VERSION ""

NS_ :

BS_:

BU_: TestTool_HS BCP_HS ECM_HS TCM_HS CGM_HS BCM_HS EBCM_OBD_HS ACCM_HS EBCM_HS TCCM_HS SAS_HS ICCM_OBD_HS ICCM_HS EPS_HS EPB_HS HMIM_HS ONSTAR_HS

BO_ 1931 DTC_Triggered_78B: 7 SAS_HS
 SG_ DTCI_CodeSupported_78B : 40|1@0+ (1,0) [0|1] ""  CGM_HS,HMIM_HS,ONSTAR_HS
 SG_ DTCI_CurrentStatus_78B : 41|1@0+ (1,0) [0|1] ""  CGM_HS,HMIM_HS,ONSTAR_HS
 SG_ DTCI_DTCFailType_78B : 39|8@0+ (1,0) [0|255] ""  CGM_HS,HMIM_HS,ONSTAR_HS
 SG_ DTCI_DTCFaultType_78B : 55|8@0+ (1,0) [0|255] ""  CGM_HS,HMIM_HS,ONSTAR_HS
 SG_ DTCI_DTCNumber_78B : 23|16@0+ (1,0) [0|65535] ""  CGM_HS,HMIM_HS,ONSTAR_HS
 SG_ DTCI_DTCSource_78B : 15|8@0+ (1,0) [0|255] ""  CGM_HS,HMIM_HS,ONSTAR_HS
 SG_ DTCI_DTCTriggered_78B : 0|1@0+ (1,0) [0|1] ""  CGM_HS,HMIM_HS,ONSTAR_HS
 SG_ DTCI_HistStat_78B : 44|1@0+ (1,0) [0|1] ""  CGM_HS,HMIM_HS,ONSTAR_HS
 SG_ DTCI_TstFldCdClrdStat_78B : 43|1@0+ (1,0) [0|1] ""  CGM_HS,HMIM_HS,ONSTAR_HS
 SG_ DTCI_TstFldPwrUpSt_78B : 46|1@0+ (1,0) [0|1] ""  CGM_HS,HMIM_HS,ONSTAR_HS
 SG_ DTCI_TstNPsdCdClrdSt_78B : 42|1@0+ (1,0) [0|1] ""  CGM_HS,HMIM_HS,ONSTAR_HS
 SG_ DTCI_TstNPsdPwrUpSt_78B : 45|1@0+ (1,0) [0|1] ""  CGM_HS,HMIM_HS,ONSTAR_HS
 SG_ DTCIUnused1_78B : 7|1@0+ (1,0) [0|1] ""  CGM_HS,HMIM_HS,ONSTAR_HS
 SG_ DTCIUnused2_78B : 6|1@0+ (1,0) [0|1] ""  CGM_HS,HMIM_HS,ONSTAR_HS
 SG_ DTCIUnused3_78B : 5|1@0+ (1,0) [0|1] ""  CGM_HS,HMIM_HS,ONSTAR_HS
 SG_ DTCIUnused4_78B : 4|1@0+ (1,0) [0|1] ""  CGM_HS,HMIM_HS,ONSTAR_HS
 SG_ DTCIUnused5_78B : 3|1@0+ (1,0) [0|1] ""  CGM_HS,HMIM_HS,ONSTAR_HS
 SG_ DTCIUnused6_78B : 2|1@0+ (1,0) [0|1] ""  CGM_HS,HMIM_HS,ONSTAR_HS
 SG_ DTCIUnused7_78B : 1|1@0+ (1,0) [0|1] ""  CGM_HS,HMIM_HS,ONSTAR_HS
 SG_ DTCI_WrnIndRqdSt_78B : 47|1@0+ (1,0) [0|1] ""  CGM_HS,HMIM_HS,ONSTAR_HS

BO_ 1928 DTC_Triggered_788: 7 HMIM_HS
 SG_ DTCI_CodeSupported_788 : 40|1@0+ (1,0) [0|1] ""  CGM_HS,HMIM_HS,ONSTAR_HS
 SG_ DTCI_CurrentStatus_788 : 41|1@0+ (1,0) [0|1] ""  CGM_HS,HMIM_HS,ONSTAR_HS
 SG_ DTCI_DTCFailType_788 : 39|8@0+ (1,0) [0|255] ""  CGM_HS,HMIM_HS,ONSTAR_HS
 SG_ DTCI_DTCFaultType_788 : 55|8@0+ (1,0) [0|255] ""  CGM_HS,HMIM_HS,ONSTAR_HS
 SG_ DTCI_DTCNumber_788 : 23|16@0+ (1,0) [0|65535] ""  CGM_HS,HMIM_HS,ONSTAR_HS
 SG_ DTCI_DTCSource_788 : 15|8@0+ (1,0) [0|255] ""  CGM_HS,HMIM_HS,ONSTAR_HS
 SG_ DTCI_DTCTriggered_788 : 0|1@0+ (1,0) [0|1] ""  CGM_HS,HMIM_HS,ONSTAR_HS
 SG_ DTCI_HistStat_788 : 44|1@0+ (1,0) [0|1] ""  CGM_HS,HMIM_HS,ONSTAR_HS
 SG_ DTCI_TstFldCdClrdStat_788 : 42|1@0+ (1,0) [0|1] ""  CGM_HS,HMIM_HS,ONSTAR_HS
 SG_ DTCI_TstFldPwrUpSt_788 : 46|1@0+ (1,0) [0|1] ""  CGM_HS,HMIM_HS,ONSTAR_HS
 SG_ DTCI_TstNPsdCdClrdSt_788 : 43|1@0+ (1,0) [0|1] ""  CGM_HS,HMIM_HS,ONSTAR_HS
 SG_ DTCI_TstNPsdPwrUpSt_788 : 45|1@0+ (1,0) [0|1] ""  CGM_HS,HMIM_HS,ONSTAR_HS
 SG_ DTCIUnused1_788 : 7|1@0+ (1,0) [0|1] ""  CGM_HS,HMIM_HS,ONSTAR_HS
 SG_ DTCIUnused2_788 : 6|1@0+ (1,0) [0|1] ""  CGM_HS,HMIM_HS,ONSTAR_HS
 SG_ DTCIUnused3_788 : 5|1@0+ (1,0) [0|1] ""  CGM_HS,HMIM_HS,ONSTAR_HS
 SG_ DTCIUnused4_788 : 4|1@0+ (1,0) [0|1] ""  CGM_HS,HMIM_HS,ONSTAR_HS
 SG_ DTCIUnused5_788 : 3|1@0+ (1,0) [0|1] ""  CGM_HS,HMIM_HS,ONSTAR_HS
 SG_ DTCIUnused6_788 : 2|1@0+ (1,0) [0|1] ""  CGM_HS,HMIM_HS,ONSTAR_HS
 SG_ DTCIUnused7_788 : 1|1@0+ (1,0) [0|1] ""  CGM_HS,HMIM_HS,ONSTAR_HS
 SG_ DTCI_WrnIndRqdSt_788 : 47|1@0+ (1,0) [0|1] ""  CGM_HS,HMIM_HS,ONSTAR_HS

BO_ 1925 DTC_Triggered_785: 7 ICCM_HS
 SG_ DTCI_CodeSupported_785 : 40|1@0+ (1,0) [0|1] ""  CGM_HS,HMIM_HS,ONSTAR_HS
 SG_ DTCI_CurrentStatus_785 : 41|1@0+ (1,0) [0|1] ""  CGM_HS,HMIM_HS,ONSTAR_HS
 SG_ DTCI_DTCFailType_785 : 39|8@0+ (1,0) [0|255] ""  CGM_HS,HMIM_HS,ONSTAR_HS
 SG_ DTCI_DTCFaultType_785 : 55|8@0+ (1,0) [0|255] ""  CGM_HS,HMIM_HS,ONSTAR_HS
 SG_ DTCI_DTCNumber_785 : 23|16@0+ (1,0) [0|65535] ""  CGM_HS,HMIM_HS,ONSTAR_HS
 SG_ DTCI_DTCSource_785 : 15|8@0+ (1,0) [0|255] ""  CGM_HS,HMIM_HS,ONSTAR_HS
 SG_ DTCI_DTCTriggered_785 : 0|1@0+ (1,0) [0|1] ""  CGM_HS,HMIM_HS,ONSTAR_HS
 SG_ DTCI_HistStat_785 : 44|1@0+ (1,0) [0|1] ""  CGM_HS,HMIM_HS,ONSTAR_HS
 SG_ DTCI_TstFldCdClrdStat_785 : 43|1@0+ (1,0) [0|1] ""  CGM_HS,HMIM_HS,ONSTAR_HS
 SG_ DTCI_TstFldPwrUpSt_785 : 46|1@0+ (1,0) [0|1] ""  CGM_HS,HMIM_HS,ONSTAR_HS
 SG_ DTCI_TstNPsdCdClrdSt_785 : 42|1@0+ (1,0) [0|1] ""  CGM_HS,HMIM_HS,ONSTAR_HS
 SG_ DTCI_TstNPsdPwrUpSt_785 : 45|1@0+ (1,0) [0|1] ""  CGM_HS,HMIM_HS,ONSTAR_HS
 SG_ DTCIUnused1_785 : 7|1@0+ (1,0) [0|1] ""  CGM_HS,HMIM_HS,ONSTAR_HS
 SG_ DTCIUnused2_785 : 6|1@0+ (1,0) [0|1] ""  CGM_HS,HMIM_HS,ONSTAR_HS
 SG_ DTCIUnused3_785 : 5|1@0+ (1,0) [0|1] ""  CGM_HS,HMIM_HS,ONSTAR_HS
 SG_ DTCIUnused4_785 : 4|1@0+ (1,0) [0|1] ""  CGM_HS,HMIM_HS,ONSTAR_HS
 SG_ DTCIUnused5_785 : 3|1@0+ (1,0) [0|1] ""  CGM_HS,HMIM_HS,ONSTAR_HS
 SG_ DTCIUnused6_785 : 2|1@0+ (1,0) [0|1] ""  CGM_HS,HMIM_HS,ONSTAR_HS
 SG_ DTCIUnused7_785 : 1|1@0+ (1,0) [0|1] ""  CGM_HS,HMIM_HS,ONSTAR_HS
 SG_ DTCI_WrnIndRqdSt_785 : 47|1@0+ (1,0) [0|1] ""  CGM_HS,HMIM_HS,ONSTAR_HS

BO_ 1922 DTC_Triggered_782: 7 CGM_HS
 SG_ DTCI_WrnIndRqdSt_782 : 47|1@0+ (1,0) [0|1] ""  CGM_HS,HMIM_HS,ONSTAR_HS
 SG_ DTCIUnused7_782 : 1|1@0+ (1,0) [0|1] ""  CGM_HS,HMIM_HS,ONSTAR_HS
 SG_ DTCIUnused6_782 : 2|1@0+ (1,0) [0|1] ""  CGM_HS,HMIM_HS,ONSTAR_HS
 SG_ DTCIUnused5_782 : 3|1@0+ (1,0) [0|1] ""  CGM_HS,HMIM_HS,ONSTAR_HS
 SG_ DTCIUnused4_782 : 4|1@0+ (1,0) [0|1] ""  CGM_HS,HMIM_HS,ONSTAR_HS
 SG_ DTCIUnused3_782 : 5|1@0+ (1,0) [0|1] ""  CGM_HS,HMIM_HS,ONSTAR_HS
 SG_ DTCIUnused2_782 : 6|1@0+ (1,0) [0|1] ""  CGM_HS,HMIM_HS,ONSTAR_HS
 SG_ DTCIUnused1_782 : 7|1@0+ (1,0) [0|1] ""  CGM_HS,HMIM_HS,ONSTAR_HS
 SG_ DTCI_TstNPsdPwrUpSt_782 : 45|1@0+ (1,0) [0|1] ""  CGM_HS,HMIM_HS,ONSTAR_HS
 SG_ DTCI_TstNPsdCdClrdSt_782 : 42|1@0+ (1,0) [0|1] ""  CGM_HS,HMIM_HS,ONSTAR_HS
 SG_ DTCI_TstFldPwrUpSt_782 : 46|1@0+ (1,0) [0|1] ""  CGM_HS,HMIM_HS,ONSTAR_HS
 SG_ DTCI_TstFldCdClrdStat_782 : 43|1@0+ (1,0) [0|1] ""  CGM_HS,HMIM_HS,ONSTAR_HS
 SG_ DTCI_HistStat_782 : 44|1@0+ (1,0) [0|1] ""  CGM_HS,HMIM_HS,ONSTAR_HS
 SG_ DTCI_DTCTriggered_782 : 0|1@0+ (1,0) [0|1] ""  CGM_HS,HMIM_HS,ONSTAR_HS
 SG_ DTCI_DTCSource_782 : 15|8@0+ (1,0) [0|255] ""  CGM_HS,HMIM_HS,ONSTAR_HS
 SG_ DTCI_DTCNumber_782 : 23|16@0+ (1,0) [0|65535] ""  CGM_HS,HMIM_HS,ONSTAR_HS
 SG_ DTCI_DTCFaultType_782 : 55|8@0+ (1,0) [0|255] ""  CGM_HS,HMIM_HS,ONSTAR_HS
 SG_ DTCI_DTCFailType_782 : 39|8@0+ (1,0) [0|255] ""  CGM_HS,HMIM_HS,ONSTAR_HS
 SG_ DTCI_CurrentStatus_782 : 41|1@0+ (1,0) [0|1] ""  CGM_HS,HMIM_HS,ONSTAR_HS
 SG_ DTCI_CodeSupported_782 : 40|1@0+ (1,0) [0|1] ""  CGM_HS,HMIM_HS,ONSTAR_HS

BO_ 1904 DTC_Triggered_770: 7 ICCM_OBD_HS
 SG_ DTCI_WrnIndRqdSt_770 : 47|1@0+ (1,0) [0|1] ""  CGM_HS,HMIM_HS,ONSTAR_HS
 SG_ DTCIUnused7_770 : 7|1@0+ (1,0) [0|1] ""  CGM_HS,HMIM_HS,ONSTAR_HS
 SG_ DTCIUnused6_770 : 6|1@0+ (1,0) [0|1] ""  CGM_HS,HMIM_HS,ONSTAR_HS
 SG_ DTCIUnused5_770 : 5|1@0+ (1,0) [0|1] ""  CGM_HS,HMIM_HS,ONSTAR_HS
 SG_ DTCIUnused4_770 : 4|1@0+ (1,0) [0|1] ""  CGM_HS,HMIM_HS,ONSTAR_HS
 SG_ DTCIUnused3_770 : 3|1@0+ (1,0) [0|1] ""  CGM_HS,HMIM_HS,ONSTAR_HS
 SG_ DTCIUnused2_770 : 2|1@0+ (1,0) [0|1] ""  CGM_HS,HMIM_HS,ONSTAR_HS
 SG_ DTCIUnused1_770 : 1|1@0+ (1,0) [0|1] ""  CGM_HS,HMIM_HS,ONSTAR_HS
 SG_ DTCI_TstNPsdPwrUpSt_770 : 45|1@0+ (1,0) [0|1] ""  CGM_HS,HMIM_HS,ONSTAR_HS
 SG_ DTCI_TstNPsdCdClrdSt_770 : 42|1@0+ (1,0) [0|1] ""  CGM_HS,HMIM_HS,ONSTAR_HS
 SG_ DTCI_TstFldPwrUpSt_770 : 46|1@0+ (1,0) [0|1] ""  CGM_HS,HMIM_HS,ONSTAR_HS
 SG_ DTCI_TstFldCdClrdStat_770 : 43|1@0+ (1,0) [0|1] ""  CGM_HS,HMIM_HS,ONSTAR_HS
 SG_ DTCI_HistStat_770 : 44|1@0+ (1,0) [0|1] ""  CGM_HS,HMIM_HS,ONSTAR_HS
 SG_ DTCI_DTCTriggered_770 : 0|1@0+ (1,0) [0|1] ""  CGM_HS,HMIM_HS,ONSTAR_HS
 SG_ DTCI_DTCSource_770 : 15|8@0+ (1,0) [0|255] ""  CGM_HS,HMIM_HS,ONSTAR_HS
 SG_ DTCI_DTCNumber_770 : 23|16@0+ (1,0) [0|65535] ""  CGM_HS,HMIM_HS,ONSTAR_HS
 SG_ DTCI_DTCFaultType_770 : 55|8@0+ (1,0) [0|255] ""  CGM_HS,HMIM_HS,ONSTAR_HS
 SG_ DTCI_DTCFailType_770 : 39|8@0+ (1,0) [0|255] ""  CGM_HS,HMIM_HS,ONSTAR_HS
 SG_ DTCI_CurrentStatus_770 : 41|1@0+ (1,0) [0|1] ""  CGM_HS,HMIM_HS,ONSTAR_HS
 SG_ DTCI_CodeSupported_770 : 40|1@0+ (1,0) [0|1] ""  CGM_HS,HMIM_HS,ONSTAR_HS

BO_ 1921 DTC_Triggered_781: 7 CGM_HS
 SG_ DTCI_CurrentStatus_781 : 41|1@0+ (1,0) [0|1] ""  CGM_HS,HMIM_HS,ONSTAR_HS
 SG_ DTCI_WrnIndRqdSt_781 : 47|1@0+ (1,0) [0|1] ""  CGM_HS,HMIM_HS,ONSTAR_HS
 SG_ DTCIUnused7_781 : 1|1@0+ (1,0) [0|1] ""  CGM_HS,HMIM_HS,ONSTAR_HS
 SG_ DTCIUnused6_781 : 2|1@0+ (1,0) [0|1] ""  CGM_HS,HMIM_HS,ONSTAR_HS
 SG_ DTCIUnused5_781 : 3|1@0+ (1,0) [0|1] ""  CGM_HS,HMIM_HS,ONSTAR_HS
 SG_ DTCIUnused4_781 : 4|1@0+ (1,0) [0|1] ""  CGM_HS,HMIM_HS,ONSTAR_HS
 SG_ DTCIUnused3_781 : 5|1@0+ (1,0) [0|1] ""  CGM_HS,HMIM_HS,ONSTAR_HS
 SG_ DTCIUnused2_781 : 6|1@0+ (1,0) [0|1] ""  CGM_HS,HMIM_HS,ONSTAR_HS
 SG_ DTCIUnused1_781 : 7|1@0+ (1,0) [0|1] ""  CGM_HS,HMIM_HS,ONSTAR_HS
 SG_ DTCI_TstNPsdPwrUpSt_781 : 45|1@0+ (1,0) [0|1] ""  CGM_HS,HMIM_HS,ONSTAR_HS
 SG_ DTCI_TstNPsdCdClrdSt_781 : 42|1@0+ (1,0) [0|1] ""  CGM_HS,HMIM_HS,ONSTAR_HS
 SG_ DTCI_TstFldPwrUpSt_781 : 46|1@0+ (1,0) [0|1] ""  CGM_HS,HMIM_HS,ONSTAR_HS
 SG_ DTCI_TstFldCdClrdStat_781 : 43|1@0+ (1,0) [0|1] ""  CGM_HS,HMIM_HS,ONSTAR_HS
 SG_ DTCI_HistStat_781 : 44|1@0+ (1,0) [0|1] ""  CGM_HS,HMIM_HS,ONSTAR_HS
 SG_ DTCI_DTCTriggered_781 : 0|1@0+ (1,0) [0|1] ""  CGM_HS,HMIM_HS,ONSTAR_HS
 SG_ DTCI_DTCSource_781 : 15|8@0+ (1,0) [0|255] ""  CGM_HS,HMIM_HS,ONSTAR_HS
 SG_ DTCI_DTCNumber_781 : 23|16@0+ (1,0) [0|65535] ""  CGM_HS,HMIM_HS,ONSTAR_HS
 SG_ DTCI_DTCFaultType_781 : 55|8@0+ (1,0) [0|255] ""  CGM_HS,HMIM_HS,ONSTAR_HS
 SG_ DTCI_DTCFailType_781 : 39|8@0+ (1,0) [0|255] ""  CGM_HS,HMIM_HS,ONSTAR_HS
 SG_ DTCI_CodeSupported_781 : 40|1@0+ (1,0) [0|1] ""  CGM_HS,HMIM_HS,ONSTAR_HS

BO_ 1912 DTC_Triggered_778: 7 EPS_HS
 SG_ DTCI_DTCFaultType_778 : 55|8@0+ (1,0) [0|255] ""  CGM_HS,HMIM_HS,ONSTAR_HS
 SG_ DTCI_CodeSupported_778 : 40|1@0+ (1,0) [0|1] ""  CGM_HS,HMIM_HS,ONSTAR_HS
 SG_ DTCI_CurrentStatus_778 : 41|1@0+ (1,0) [0|1] ""  CGM_HS,HMIM_HS,ONSTAR_HS
 SG_ DTCI_TstNPsdCdClrdSt_778 : 42|1@0+ (1,0) [0|1] ""  CGM_HS,HMIM_HS,ONSTAR_HS
 SG_ DTCI_TstFldCdClrdStat_778 : 43|1@0+ (1,0) [0|1] ""  CGM_HS,HMIM_HS,ONSTAR_HS
 SG_ DTCI_HistStat_778 : 44|1@0+ (1,0) [0|1] ""  CGM_HS,HMIM_HS,ONSTAR_HS
 SG_ DTCI_TstNPsdPwrUpSt_778 : 45|1@0+ (1,0) [0|1] ""  CGM_HS,HMIM_HS,ONSTAR_HS
 SG_ DTCI_TstFldPwrUpSt_778 : 46|1@0+ (1,0) [0|1] ""  CGM_HS,HMIM_HS,ONSTAR_HS
 SG_ DTCI_WrnIndRqdSt_778 : 47|1@0+ (1,0) [0|1] ""  CGM_HS,HMIM_HS,ONSTAR_HS
 SG_ DTCI_DTCFailType_778 : 39|8@0+ (1,0) [0|255] ""  CGM_HS,HMIM_HS,ONSTAR_HS
 SG_ DTCI_DTCNumber_778 : 23|16@0+ (1,0) [0|65535] ""  CGM_HS,HMIM_HS,ONSTAR_HS
 SG_ DTCI_DTCSource_778 : 15|8@0+ (1,0) [0|255] ""  CGM_HS,HMIM_HS,ONSTAR_HS
 SG_ DTCI_DTCTriggered_778 : 0|1@0+ (1,0) [0|1] ""  CGM_HS,HMIM_HS,ONSTAR_HS
 SG_ DTCIUnused7_778 : 1|1@0+ (1,0) [0|1] ""  CGM_HS,HMIM_HS,ONSTAR_HS
 SG_ DTCIUnused6_778 : 2|1@0+ (1,0) [0|1] ""  CGM_HS,HMIM_HS,ONSTAR_HS
 SG_ DTCIUnused5_778 : 3|1@0+ (1,0) [0|1] ""  CGM_HS,HMIM_HS,ONSTAR_HS
 SG_ DTCIUnused4_778 : 4|1@0+ (1,0) [0|1] ""  CGM_HS,HMIM_HS,ONSTAR_HS
 SG_ DTCIUnused3_778 : 5|1@0+ (1,0) [0|1] ""  CGM_HS,HMIM_HS,ONSTAR_HS
 SG_ DTCIUnused2_778 : 6|1@0+ (1,0) [0|1] ""  CGM_HS,HMIM_HS,ONSTAR_HS
 SG_ DTCIUnused1_778 : 7|1@0+ (1,0) [0|1] ""  CGM_HS,HMIM_HS,ONSTAR_HS

BO_ 1610 USDT_Resp_From_SAS_HS: 8 SAS_HS
 SG_ DgnInf : 7|64@0+ (1,0) [0|1.84467440737096E+019] ""  CGM_HS,ONSTAR_HS,TestTool_HS

BO_ 1363 UUDT_Resp_From_AMP_HS: 8 CGM_HS
 SG_ DgnInf_HS553 : 7|64@0+ (1,0) [0|1.84467440737096E+019] ""  ONSTAR_HS,TestTool_HS

BO_ 1631 USDT_Resp_From_VLBS_CGM_HS: 8 CGM_HS
 SG_ DgnInf : 7|64@0+ (1,0) [0|1.84467440737096E+019] ""  ONSTAR_HS,TestTool_HS

BO_ 1375 UUDT_Resp_From_VLBS_CGM_HS: 8 CGM_HS
 SG_ DgnInf_HS55F : 7|64@0+ (1,0) [0|1.84467440737096E+019] ""  ONSTAR_HS,TestTool_HS

BO_ 1372 UUDT_Resp_From_ACCM_HS: 8 ACCM_HS
 SG_ DgnInf_HS55C : 7|64@0+ (1,0) [0|1.84467440737096E+019] ""  CGM_HS,ONSTAR_HS,TestTool_HS

BO_ 1362 UUDT_Resp_From_HMIM_HS: 8 HMIM_HS
 SG_ DgnInf_HS552 : 7|64@0+ (1,0) [0|1.84467440737096E+019] ""  ONSTAR_HS,TestTool_HS

BO_ 1628 USDT_Resp_From_ACCM_HS: 8 ACCM_HS
 SG_ DgnInf : 7|64@0+ (1,0) [0|1.84467440737096E+019] ""  CGM_HS,ONSTAR_HS,TestTool_HS

BO_ 1619 USDT_Resp_From_AMP_HS: 8 CGM_HS
 SG_ DgnInf : 7|64@0+ (1,0) [0|1.84467440737096E+019] ""  ONSTAR_HS,TestTool_HS

BO_ 1618 USDT_Resp_From_HMIM_HS: 8 HMIM_HS
 SG_ DgnInf : 7|64@0+ (1,0) [0|1.84467440737096E+019] ""  ONSTAR_HS,TestTool_HS

BO_ 1357 UUDT_Resp_From_ONS_HS: 8 ONSTAR_HS
 SG_ DgnInf_HS54D : 7|64@0+ (1,0) [0|1.84467440737096E+019] ""  TestTool_HS

BO_ 1613 USDT_Resp_From_ONS_HS: 8 ONSTAR_HS
 SG_ DgnInf : 7|64@0+ (1,0) [0|1.84467440737096E+019] ""  TestTool_HS

BO_ 1606 USDT_Resp_From_APPS_HS: 8 CGM_HS
 SG_ DgnInf : 7|64@0+ (1,0) [0|1.84467440737096E+019] ""  CGM_HS,ONSTAR_HS,TestTool_HS

BO_ 1356 UUDT_Resp_From_PFAF_HS: 8 CGM_HS
 SG_ DgnInf_HS54C : 7|64@0+ (1,0) [0|1.84467440737096E+019] ""  CGM_HS,ONSTAR_HS,TestTool_HS

BO_ 1350 UUDT_Resp_From_APPS_HS: 8 CGM_HS
 SG_ DgnInf_HS546 : 7|64@0+ (1,0) [0|1.84467440737096E+019] ""  CGM_HS,TestTool_HS,ONSTAR_HS

BO_ 2029 USDT_Resp_From_OBD_Device5: 8 EBCM_OBD_HS
 SG_ DgnInf : 7|64@0+ (1,0) [0|1.84467440737096E+019] ""  CGM_HS,TestTool_HS,ONSTAR_HS

BO_ 1517 UUDT_Resp_From_OBD_Device5: 8 EBCM_OBD_HS
 SG_ DgnInf : 7|64@0+ (1,0) [0|1.84467440737096E+019] ""  CGM_HS,TestTool_HS,ONSTAR_HS

BO_ 1346 UUDT_Resp_From_EHPS_EPS_HS: 8 EPS_HS
 SG_ DgnInf_HS542 : 7|64@0+ (1,0) [0|1.84467440737096E+019] ""  CGM_HS,TestTool_HS,ONSTAR_HS

BO_ 1602 USDT_Resp_From_EHPS_EPS_HS: 8 EPS_HS
 SG_ DgnInf : 7|64@0+ (1,0) [0|1.84467440737096E+019] ""  CGM_HS,TestTool_HS,ONSTAR_HS

BO_ 2027 USDT_Resp_From_ICCM_OBD_HS: 8 ICCM_HS
 SG_ DgnInf : 7|64@0+ (1,0) [0|1.84467440737096E+019] ""  CGM_HS,TestTool_HS,ONSTAR_HS

BO_ 1515 UUDT_Resp_From_ICCM_OBD_HS: 8 ICCM_HS
 SG_ DgnInf : 7|64@0+ (1,0) [0|1.84467440737096E+019] ""  CGM_HS,TestTool_HS,ONSTAR_HS

BO_ 1354 UUDT_Resp_From_SAS_HS: 8 SAS_HS
 SG_ DgnInf_HS54A : 7|64@0+ (1,0) [0|1.84467440737096E+019] ""  CGM_HS,TestTool_HS,ONSTAR_HS

BO_ 1612 USDT_Resp_From_PFAF_HS: 8 CGM_HS
 SG_ DgnInf : 7|64@0+ (1,0) [0|1.84467440737096E+019] ""  CGM_HS,ONSTAR_HS,TestTool_HS

BO_ 607 USDT_Req_to_VLBS_CGM_HS: 8 TestTool_HS
 SG_ DgnInf : 7|64@0+ (1,0) [0|1.84467440737096E+019] ""  CGM_HS

BO_ 606 USDT_Req_to_VCM_HS: 8 TestTool_HS
 SG_ DgnInf : 7|64@0+ (1,0) [0|1.84467440737096E+019] "" Vector__XXX

BO_ 605 USDT_Req_to_ARS_HS: 8 TestTool_HS
 SG_ DgnInf : 7|64@0+ (1,0) [0|1.84467440737096E+019] "" Vector__XXX

BO_ 604 USDT_Req_to_ACCM_HS: 8 TestTool_HS
 SG_ DgnInf : 7|64@0+ (1,0) [0|1.84467440737096E+019] ""  ACCM_HS

BO_ 602 USDT_Req_to_Free_5A_HS: 8 TestTool_HS
 SG_ DgnInf : 7|64@0+ (1,0) [0|1.84467440737096E+019] "" Vector__XXX

BO_ 600 USDT_Req_to_MCP_B_HS: 8 TestTool_HS
 SG_ DgnInf : 7|64@0+ (1,0) [0|1.84467440737096E+019] "" Vector__XXX

BO_ 595 USDT_Req_to_AMP_HS: 8 TestTool_HS
 SG_ DgnInf : 7|64@0+ (1,0) [0|1.84467440737096E+019] ""  CGM_HS

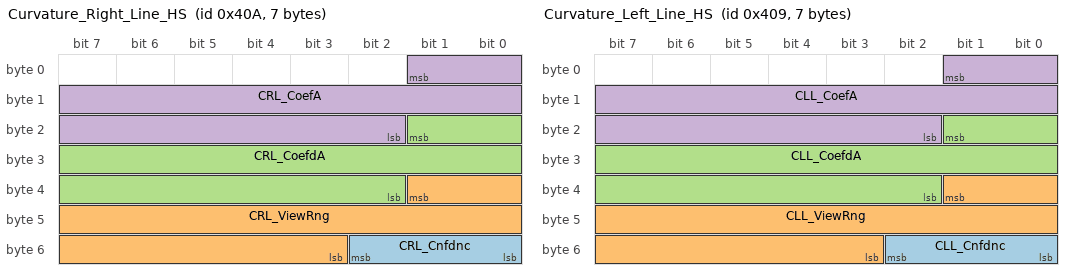
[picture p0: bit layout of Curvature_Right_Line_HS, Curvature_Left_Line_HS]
BO_ 1034 Curvature_Right_Line_HS: 7 CGM_HS
 SG_ CRL_Cnfdnc : 50|3@0+ (1,0) [0|7] ""  EBCM_OBD_HS,EBCM_HS
 SG_ CRL_ViewRng : 33|15@0+ (0.0039064,0) [0|128.0010088] "m"  EBCM_OBD_HS,EBCM_HS
 SG_ CRL_CoefdA : 17|16@0- (3.6622E-009,0) [-0.0001200029696|0.0001199993074] "1/m^2"  EBCM_OBD_HS,EBCM_HS
 SG_ CRL_CoefA : 1|16@0- (6.1036E-007,0) [-0.02000027648|0.01999966612] "1/m"  EBCM_OBD_HS,EBCM_HS

BO_ 1033 Curvature_Left_Line_HS: 7 CGM_HS
 SG_ CLL_Cnfdnc : 50|3@0+ (1,0) [0|7] ""  EBCM_OBD_HS,EBCM_HS
 SG_ CLL_ViewRng : 33|15@0+ (0.0039064,0) [0|128.0010088] "m"  EBCM_OBD_HS,EBCM_HS
 SG_ CLL_CoefdA : 17|16@0- (3.6622E-009,0) [-0.0001200029696|0.0001199993074] "1/m^2"  EBCM_OBD_HS,EBCM_HS
 SG_ CLL_CoefA : 1|16@0- (6.1036E-007,0) [-0.02000027648|0.01999966612] "1/m"  EBCM_OBD_HS,EBCM_HS

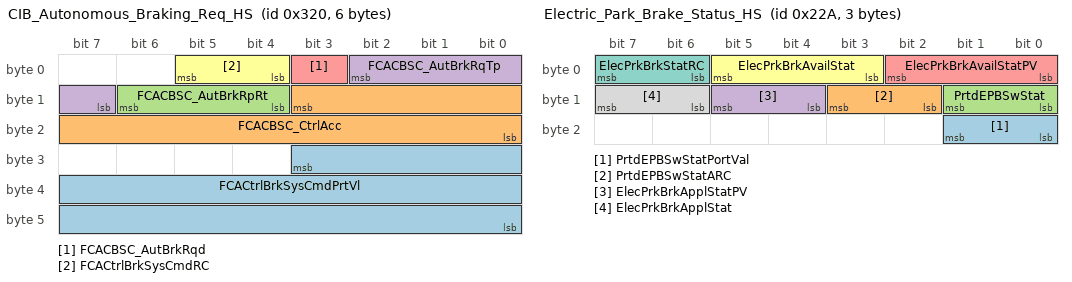
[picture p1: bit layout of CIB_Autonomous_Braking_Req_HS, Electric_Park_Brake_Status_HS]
BO_ 800 CIB_Autonomous_Braking_Req_HS: 6 CGM_HS
 SG_ FCACtrlBrkSysCmdPrtVl : 27|20@0+ (1,0) [0|1048575] ""  EBCM_OBD_HS,EBCM_HS
 SG_ FCACBSC_CtrlAcc : 11|12@0- (0.01,0) [-20.48|20.47] "m/s^2"  EBCM_OBD_HS,EBCM_HS
 SG_ FCACBSC_AutBrkRpRt : 14|3@0+ (1,0) [0|7] ""  EBCM_OBD_HS,EBCM_HS
 SG_ FCACBSC_AutBrkRqTp : 2|4@0+ (1,0) [0|15] ""  EBCM_OBD_HS,EBCM_HS
 SG_ FCACBSC_AutBrkRqd : 3|1@0+ (1,0) [0|1] ""  EBCM_OBD_HS,EBCM_HS
 SG_ FCACtrlBrkSysCmdRC : 5|2@0+ (1,0) [0|3] ""  EBCM_OBD_HS,EBCM_HS

BO_ 554 Electric_Park_Brake_Status_HS: 3 EPB_HS
 SG_ PrtdEPBSwStatPortVal : 17|2@0+ (1,0) [0|3] "Counts"  EBCM_OBD_HS,EBCM_HS
 SG_ PrtdEPBSwStatARC : 11|2@0+ (1,0) [0|3] "Counts"  EBCM_OBD_HS,EBCM_HS
 SG_ PrtdEPBSwStat : 9|2@0+ (1,0) [0|3] ""  EBCM_OBD_HS,EBCM_HS
 SG_ ElecPrkBrkApplStatPV : 13|2@0+ (1,0) [0|3] ""  EBCM_OBD_HS,EBCM_HS
 SG_ ElecPrkBrkAvailStatPV : 2|3@0+ (1,0) [0|7] ""  EBCM_OBD_HS,EBCM_HS
 SG_ ElecPrkBrkAvailStat : 5|3@0+ (1,0) [0|7] ""  EBCM_OBD_HS,EBCM_HS
 SG_ ElecPrkBrkStatRC : 7|2@0+ (1,0) [0|3] ""  EBCM_OBD_HS,EBCM_HS
 SG_ ElecPrkBrkApplStat : 15|2@0+ (1,0) [0|3] ""  EBCM_OBD_HS,EBCM_HS

BO_ 464 PPEI_Front_Axle_Status: 4 TCCM_HS
 SG_ FrtAxlOpeMod : 31|3@0+ (1,0) [0|7] ""  EBCM_OBD_HS,EBCM_HS

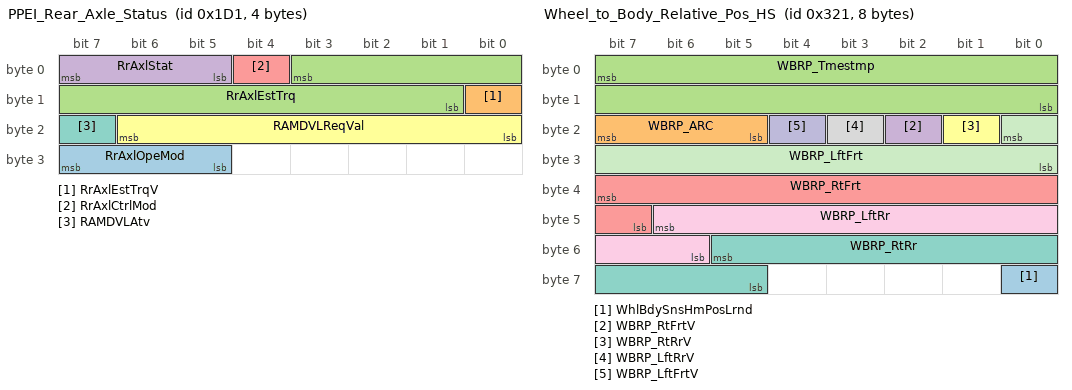
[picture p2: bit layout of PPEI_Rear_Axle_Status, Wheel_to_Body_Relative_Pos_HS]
BO_ 465 PPEI_Rear_Axle_Status: 4 TCCM_HS
 SG_ RrAxlOpeMod : 31|3@0+ (1,0) [0|7] ""  EBCM_OBD_HS,EBCM_HS
 SG_ RrAxlEstTrqV : 8|1@0+ (1,0) [0|1] ""  EBCM_OBD_HS,EBCM_HS
 SG_ RrAxlEstTrq : 3|11@0- (5,0) [-5120|5115] "Nm"  EBCM_OBD_HS,EBCM_HS
 SG_ RrAxlStat : 7|3@0+ (1,0) [0|7] ""  EBCM_OBD_HS,EBCM_HS
 SG_ RrAxlCtrlMod : 4|1@0+ (1,0) [0|1] ""  EBCM_OBD_HS,EBCM_HS
 SG_ RAMDVLReqVal : 22|7@0+ (2,0) [0|254] "rpm"  EBCM_OBD_HS,EBCM_HS
 SG_ RAMDVLAtv : 23|1@0+ (1,0) [0|1] ""  EBCM_OBD_HS,EBCM_HS

BO_ 801 Wheel_to_Body_Relative_Pos_HS: 8 ICCM_HS
 SG_ WhlBdySnsHmPosLrnd : 56|1@0+ (1,0) [0|1] ""  CGM_HS,ICCM_OBD_HS,EBCM_OBD_HS,ICCM_HS,EBCM_HS
 SG_ WBRP_ARC : 23|3@0+ (1,0) [0|7] "counts"  CGM_HS,ICCM_OBD_HS,EBCM_OBD_HS,ICCM_HS,EBCM_HS
 SG_ WBRP_Tmestmp : 7|16@0+ (1,0) [0|65535] "micro sec"  CGM_HS,ICCM_OBD_HS,EBCM_OBD_HS,ICCM_HS,EBCM_HS
 SG_ WBRP_RtFrtV : 18|1@0+ (1,0) [0|1] ""  CGM_HS,ICCM_OBD_HS,EBCM_OBD_HS,ICCM_HS,EBCM_HS
 SG_ WBRP_RtFrt : 39|9@0- (1,0) [-256|255] "mm"  CGM_HS,ICCM_OBD_HS,EBCM_OBD_HS,ICCM_HS,EBCM_HS
 SG_ WBRP_RtRrV : 17|1@0+ (1,0) [0|1] ""  CGM_HS,ICCM_OBD_HS,EBCM_OBD_HS,ICCM_HS,EBCM_HS
 SG_ WBRP_RtRr : 53|9@0- (1,0) [-256|255] "mm"  CGM_HS,ICCM_OBD_HS,EBCM_OBD_HS,ICCM_HS,EBCM_HS
 SG_ WBRP_LftRrV : 19|1@0+ (1,0) [0|1] ""  CGM_HS,ICCM_OBD_HS,EBCM_OBD_HS,ICCM_HS,EBCM_HS
 SG_ WBRP_LftRr : 46|9@0- (1,0) [-256|255] "mm"  CGM_HS,ICCM_OBD_HS,EBCM_OBD_HS,ICCM_HS,EBCM_HS
 SG_ WBRP_LftFrtV : 20|1@0+ (1,0) [0|1] ""  CGM_HS,ICCM_OBD_HS,EBCM_OBD_HS,ICCM_HS,EBCM_HS
 SG_ WBRP_LftFrt : 16|9@0- (1,0) [-256|255] "mm"  CGM_HS,ICCM_OBD_HS,EBCM_OBD_HS,ICCM_HS,EBCM_HS

BO_ 579 USDT_Req_to_EBCM_HPCC_HS: 8 TestTool_HS
 SG_ DgnInf : 7|64@0+ (1,0) [0|1.84467440737096E+019] ""  EBCM_HS

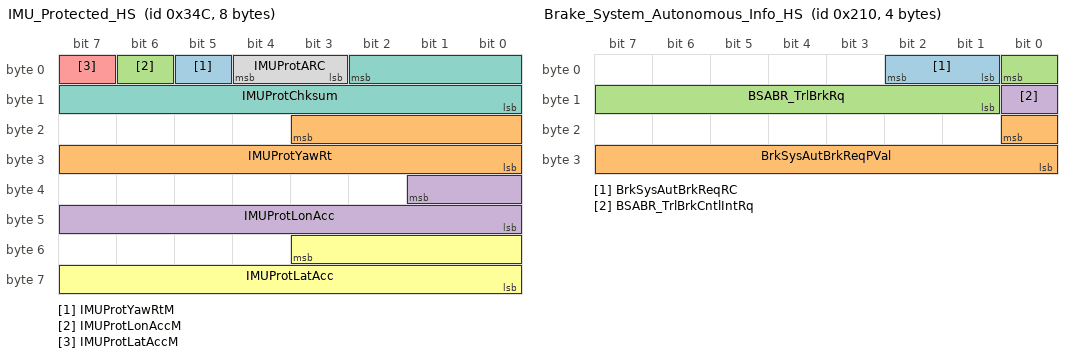
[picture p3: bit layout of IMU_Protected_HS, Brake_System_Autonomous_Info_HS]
BO_ 844 IMU_Protected_HS: 8 EBCM_HS
 SG_ IMUProtYawRtM : 5|1@0+ (1,0) [0|1] ""  CGM_HS,EPS_HS
 SG_ IMUProtYawRt : 19|12@0- (0.0625,0) [-128|127.9375] "deg/sec"  CGM_HS,EPS_HS
 SG_ IMUProtLonAccM : 6|1@0+ (1,0) [0|1] ""  CGM_HS,EPS_HS
 SG_ IMUProtLonAcc : 33|10@0- (0.03,0) [-15.36|15.33] "m/s^2"  CGM_HS,EPS_HS
 SG_ IMUProtLatAccM : 7|1@0+ (1,0) [0|1] ""  CGM_HS,EPS_HS
 SG_ IMUProtLatAcc : 51|12@0- (0.015625,0) [-32|31.984375] "m/s^2"  CGM_HS,EPS_HS
 SG_ IMUProtChksum : 2|11@0+ (1,0) [0|2047] ""  CGM_HS,EPS_HS
 SG_ IMUProtARC : 4|2@0+ (1,0) [0|3] ""  CGM_HS,EPS_HS

BO_ 528 Brake_System_Autonomous_Info_HS: 4 EBCM_HS
 SG_ BrkSysAutBrkReqRC : 2|2@0+ (1,0) [0|3] ""  ICCM_OBD_HS,ICCM_HS
 SG_ BrkSysAutBrkReqPVal : 16|9@0+ (1,0) [0|511] ""  ICCM_OBD_HS,ICCM_HS
 SG_ BSABR_TrlBrkRq : 0|8@0+ (0.392157,0) [0|100.000035] "%"  ICCM_OBD_HS,ICCM_HS
 SG_ BSABR_TrlBrkCntlIntRq : 8|1@0+ (1,0) [0|1] ""  ICCM_OBD_HS,ICCM_HS

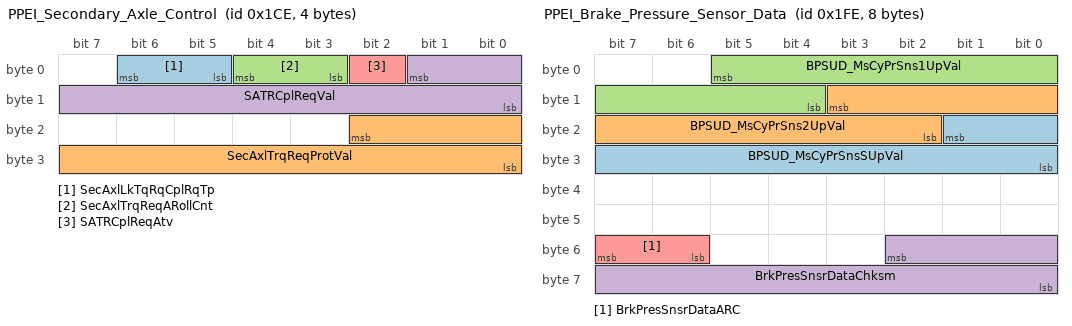
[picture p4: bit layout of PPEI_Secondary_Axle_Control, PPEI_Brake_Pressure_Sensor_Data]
BO_ 462 PPEI_Secondary_Axle_Control: 4 EBCM_HS
 SG_ SecAxlLkTqRqCplRqTp : 6|2@0+ (1,0) [0|3] ""  TCCM_HS
 SG_ SecAxlTrqReqProtVal : 18|11@0+ (1,0) [0|2047] "Counts"  TCCM_HS
 SG_ SecAxlTrqReqARollCnt : 4|2@0+ (1,0) [0|3] "Counts"  TCCM_HS
 SG_ SATRCplReqVal : 1|10@0+ (10,0) [0|10230] "Nm"  TCCM_HS
 SG_ SATRCplReqAtv : 2|1@0+ (1,0) [0|1] ""  TCCM_HS

BO_ 510 PPEI_Brake_Pressure_Sensor_Data: 8 EBCM_HS
 SG_ BPSUD_MsCyPrSnsSUpVal : 17|10@0+ (1,0) [0|1023] "" Vector__XXX
 SG_ BPSUD_MsCyPrSns2UpVal : 11|10@0+ (1,0) [0|1023] "" Vector__XXX
 SG_ BPSUD_MsCyPrSns1UpVal : 5|10@0+ (1,0) [0|1023] "" Vector__XXX
 SG_ BrkPresSnsrDataChksm : 50|11@0+ (1,0) [0|2047] "" Vector__XXX
 SG_ BrkPresSnsrDataARC : 55|2@0+ (1,0) [0|3] "" Vector__XXX

BO_ 1920 DTC_Triggered_780: 7 EBCM_HS
 SG_ DTCI_CurrentStatus_780 : 41|1@0+ (1,0) [0|1] ""  CGM_HS,HMIM_HS,ONSTAR_HS
 SG_ DTCI_WrnIndRqdSt_780 : 47|1@0+ (1,0) [0|1] ""  CGM_HS,HMIM_HS,ONSTAR_HS
 SG_ DTCIUnused7_780 : 1|1@0+ (1,0) [0|1] ""  CGM_HS,HMIM_HS,ONSTAR_HS
 SG_ DTCIUnused6_780 : 2|1@0+ (1,0) [0|1] ""  CGM_HS,HMIM_HS,ONSTAR_HS
 SG_ DTCIUnused5_780 : 3|1@0+ (1,0) [0|1] ""  CGM_HS,HMIM_HS,ONSTAR_HS
 SG_ DTCIUnused4_780 : 4|1@0+ (1,0) [0|1] ""  CGM_HS,HMIM_HS,ONSTAR_HS
 SG_ DTCIUnused3_780 : 5|1@0+ (1,0) [0|1] ""  CGM_HS,HMIM_HS,ONSTAR_HS
 SG_ DTCIUnused2_780 : 6|1@0+ (1,0) [0|1] ""  CGM_HS,HMIM_HS,ONSTAR_HS
 SG_ DTCIUnused1_780 : 7|1@0+ (1,0) [0|1] ""  CGM_HS,HMIM_HS,ONSTAR_HS
 SG_ DTCI_TstNPsdPwrUpSt_780 : 45|1@0+ (1,0) [0|1] ""  CGM_HS,HMIM_HS,ONSTAR_HS
 SG_ DTCI_TstNPsdCdClrdSt_780 : 42|1@0+ (1,0) [0|1] ""  CGM_HS,HMIM_HS,ONSTAR_HS
 SG_ DTCI_TstFldPwrUpSt_780 : 46|1@0+ (1,0) [0|1] ""  CGM_HS,HMIM_HS,ONSTAR_HS
 SG_ DTCI_TstFldCdClrdStat_780 : 43|1@0+ (1,0) [0|1] ""  CGM_HS,HMIM_HS,ONSTAR_HS
 SG_ DTCI_HistStat_780 : 44|1@0+ (1,0) [0|1] ""  CGM_HS,HMIM_HS,ONSTAR_HS
 SG_ DTCI_DTCTriggered_780 : 0|1@0+ (1,0) [0|1] ""  CGM_HS,HMIM_HS,ONSTAR_HS
 SG_ DTCI_DTCSource_780 : 15|8@0+ (1,0) [0|255] ""  CGM_HS,HMIM_HS,ONSTAR_HS
 SG_ DTCI_DTCNumber_780 : 23|16@0+ (1,0) [0|65535] ""  CGM_HS,HMIM_HS,ONSTAR_HS
 SG_ DTCI_DTCFaultType_780 : 55|8@0+ (1,0) [0|255] ""  CGM_HS,HMIM_HS,ONSTAR_HS
 SG_ DTCI_DTCFailType_780 : 39|8@0+ (1,0) [0|255] ""  CGM_HS,HMIM_HS,ONSTAR_HS
 SG_ DTCI_CodeSupported_780 : 40|1@0+ (1,0) [0|1] ""  CGM_HS,HMIM_HS,ONSTAR_HS

BO_ 1907 DTC_Triggered_773: 7 EBCM_HS
 SG_ DTCI_DTCFaultType_773 : 55|8@0+ (1,0) [0|255] ""  CGM_HS,HMIM_HS,ONSTAR_HS
 SG_ DTCI_CodeSupported_773 : 40|1@0+ (1,0) [0|1] ""  CGM_HS,HMIM_HS,ONSTAR_HS
 SG_ DTCI_CurrentStatus_773 : 41|1@0+ (1,0) [0|1] ""  CGM_HS,HMIM_HS,ONSTAR_HS
 SG_ DTCI_TstNPsdCdClrdSt_773 : 42|1@0+ (1,0) [0|1] ""  CGM_HS,HMIM_HS,ONSTAR_HS
 SG_ DTCI_TstFldCdClrdStat_773 : 43|1@0+ (1,0) [0|1] ""  CGM_HS,HMIM_HS,ONSTAR_HS
 SG_ DTCI_HistStat_773 : 44|1@0+ (1,0) [0|1] ""  CGM_HS,HMIM_HS,ONSTAR_HS
 SG_ DTCI_TstNPsdPwrUpSt_773 : 45|1@0+ (1,0) [0|1] ""  CGM_HS,HMIM_HS,ONSTAR_HS
 SG_ DTCI_TstFldPwrUpSt_773 : 46|1@0+ (1,0) [0|1] ""  CGM_HS,HMIM_HS,ONSTAR_HS
 SG_ DTCI_WrnIndRqdSt_773 : 47|1@0+ (1,0) [0|1] ""  CGM_HS,HMIM_HS,ONSTAR_HS
 SG_ DTCI_DTCFailType_773 : 39|8@0+ (1,0) [0|255] ""  CGM_HS,HMIM_HS,ONSTAR_HS
 SG_ DTCI_DTCNumber_773 : 23|16@0+ (1,0) [0|65535] ""  CGM_HS,HMIM_HS,ONSTAR_HS
 SG_ DTCI_DTCSource_773 : 15|8@0+ (1,0) [0|255] ""  CGM_HS,HMIM_HS,ONSTAR_HS
 SG_ DTCI_DTCTriggered_773 : 0|1@0+ (1,0) [0|1] ""  CGM_HS,HMIM_HS,ONSTAR_HS
 SG_ DTCIUnused7_773 : 1|1@0+ (1,0) [0|1] ""  CGM_HS,HMIM_HS,ONSTAR_HS
 SG_ DTCIUnused6_773 : 2|1@0+ (1,0) [0|1] ""  CGM_HS,HMIM_HS,ONSTAR_HS
 SG_ DTCIUnused5_773 : 3|1@0+ (1,0) [0|1] ""  CGM_HS,HMIM_HS,ONSTAR_HS
 SG_ DTCIUnused4_773 : 4|1@0+ (1,0) [0|1] ""  CGM_HS,HMIM_HS,ONSTAR_HS
 SG_ DTCIUnused3_773 : 5|1@0+ (1,0) [0|1] ""  CGM_HS,HMIM_HS,ONSTAR_HS
 SG_ DTCIUnused2_773 : 6|1@0+ (1,0) [0|1] ""  CGM_HS,HMIM_HS,ONSTAR_HS
 SG_ DTCIUnused1_773 : 7|1@0+ (1,0) [0|1] ""  CGM_HS,HMIM_HS,ONSTAR_HS

BO_ 1603 USDT_Resp_From_EBCM_HPCC_HS: 8 EBCM_HS
 SG_ DgnInf : 7|64@0+ (1,0) [0|1.84467440737096E+019] ""  CGM_HS,TestTool_HS,ONSTAR_HS

BO_ 1347 UUDT_Resp_From_EBCM_HPCC_HS: 8 EBCM_HS
 SG_ DgnInf_HS543 : 7|64@0+ (1,0) [0|1.84467440737096E+019] ""  CGM_HS,TestTool_HS,ONSTAR_HS

BO_ 603 USDT_Req_to_ACC_HS: 8 TestTool_HS
 SG_ DgnInf : 7|64@0+ (1,0) [0|1.84467440737096E+019] ""  CGM_HS

BO_ 1371 UUDT_Resp_From_ACC_HS: 8 CGM_HS
 SG_ DgnInf_HS55B : 7|64@0+ (1,0) [0|1.84467440737096E+019] ""  CGM_HS,ONSTAR_HS,TestTool_HS

BO_ 1627 USDT_Resp_From_ACC_HS: 8 CGM_HS
 SG_ DgnInf : 7|64@0+ (1,0) [0|1.84467440737096E+019] ""  CGM_HS,ONSTAR_HS,TestTool_HS

BO_ 1915 DTC_Triggered_77B: 7 CGM_HS
 SG_ DTCI_DTCFaultType_77B : 55|8@0+ (1,0) [0|255] ""  CGM_HS,HMIM_HS,ONSTAR_HS
 SG_ DTCI_CodeSupported_77B : 40|1@0+ (1,0) [0|1] ""  CGM_HS,HMIM_HS,ONSTAR_HS
 SG_ DTCI_CurrentStatus_77B : 41|1@0+ (1,0) [0|1] ""  CGM_HS,HMIM_HS,ONSTAR_HS
 SG_ DTCI_TstNPsdCdClrdSt_77B : 42|1@0+ (1,0) [0|1] ""  CGM_HS,HMIM_HS,ONSTAR_HS
 SG_ DTCI_TstFldCdClrdStat_77B : 43|1@0+ (1,0) [0|1] ""  CGM_HS,HMIM_HS,ONSTAR_HS
 SG_ DTCI_HistStat_77B : 44|1@0+ (1,0) [0|1] ""  CGM_HS,HMIM_HS,ONSTAR_HS
 SG_ DTCI_TstNPsdPwrUpSt_77B : 45|1@0+ (1,0) [0|1] ""  CGM_HS,HMIM_HS,ONSTAR_HS
 SG_ DTCI_TstFldPwrUpSt_77B : 46|1@0+ (1,0) [0|1] ""  CGM_HS,HMIM_HS,ONSTAR_HS
 SG_ DTCI_WrnIndRqdSt_77B : 47|1@0+ (1,0) [0|1] ""  CGM_HS,HMIM_HS,ONSTAR_HS
 SG_ DTCI_DTCFailType_77B : 39|8@0+ (1,0) [0|255] ""  CGM_HS,HMIM_HS,ONSTAR_HS
 SG_ DTCI_DTCNumber_77B : 23|16@0+ (1,0) [0|65535] ""  CGM_HS,HMIM_HS,ONSTAR_HS
 SG_ DTCI_DTCSource_77B : 15|8@0+ (1,0) [0|255] ""  CGM_HS,HMIM_HS,ONSTAR_HS
 SG_ DTCI_DTCTriggered_77B : 0|1@0+ (1,0) [0|1] ""  CGM_HS,HMIM_HS,ONSTAR_HS
 SG_ DTCIUnused7_77B : 1|1@0+ (1,0) [0|1] ""  CGM_HS,HMIM_HS,ONSTAR_HS
 SG_ DTCIUnused6_77B : 2|1@0+ (1,0) [0|1] ""  CGM_HS,HMIM_HS,ONSTAR_HS
 SG_ DTCIUnused5_77B : 3|1@0+ (1,0) [0|1] ""  CGM_HS,HMIM_HS,ONSTAR_HS
 SG_ DTCIUnused4_77B : 4|1@0+ (1,0) [0|1] ""  CGM_HS,HMIM_HS,ONSTAR_HS
 SG_ DTCIUnused3_77B : 5|1@0+ (1,0) [0|1] ""  CGM_HS,HMIM_HS,ONSTAR_HS
 SG_ DTCIUnused2_77B : 6|1@0+ (1,0) [0|1] ""  CGM_HS,HMIM_HS,ONSTAR_HS
 SG_ DTCIUnused1_77B : 7|1@0+ (1,0) [0|1] ""  CGM_HS,HMIM_HS,ONSTAR_HS

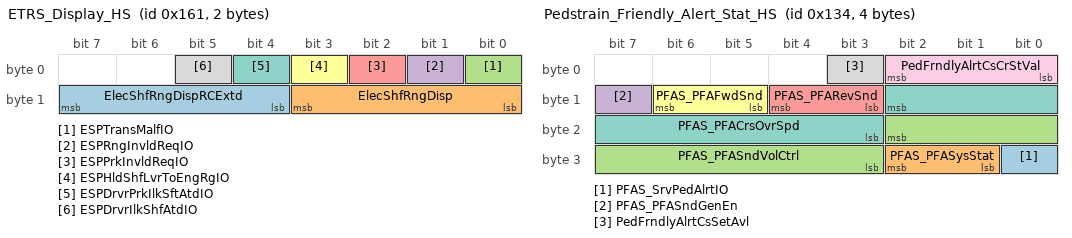
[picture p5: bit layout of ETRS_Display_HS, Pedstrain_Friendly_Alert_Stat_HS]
BO_ 353 ETRS_Display_HS: 2 ICCM_HS
 SG_ ElecShfRngDispRCExtd : 15|4@0+ (1,0) [0|15] ""  BCM_HS
 SG_ ElecShfRngDisp : 11|4@0+ (1,0) [0|15] ""  BCM_HS
 SG_ ESPTransMalfIO : 0|1@0+ (1,0) [0|1] ""  BCM_HS
 SG_ ESPRngInvldReqIO : 1|1@0+ (1,0) [0|1] ""  BCM_HS
 SG_ ESPPrkInvldReqIO : 2|1@0+ (1,0) [0|1] ""  BCM_HS
 SG_ ESPHldShfLvrToEngRgIO : 3|1@0+ (1,0) [0|1] ""  BCM_HS
 SG_ ESPDrvrPrkIlkSftAtdIO : 4|1@0+ (1,0) [0|1] ""  BCM_HS
 SG_ ESPDrvrIlkShfAtdIO : 5|1@0+ (1,0) [0|1] ""  BCM_HS

BO_ 308 Pedstrain_Friendly_Alert_Stat_HS: 4 CGM_HS
 SG_ PFAS_SrvPedAlrtIO : 24|1@0+ (1,0) [0|1] ""  BCM_HS
 SG_ PFAS_PFASysStat : 26|2@0+ (1,0) [0|3] ""  BCM_HS
 SG_ PFAS_PFASndVolCtrl : 18|8@0+ (0.392157,0) [0|100.000035] "%"  BCM_HS
 SG_ PFAS_PFASndGenEn : 15|1@0+ (1,0) [0|1] ""  BCM_HS
 SG_ PFAS_PFARevSnd : 12|2@0+ (1,0) [0|3] ""  BCM_HS
 SG_ PFAS_PFAFwdSnd : 14|2@0+ (1,0) [0|3] ""  BCM_HS
 SG_ PFAS_PFACrsOvrSpd : 10|8@0+ (1,0) [0|255] "km/h"  BCM_HS
 SG_ PedFrndlyAlrtCsSetAvl : 3|1@0+ (1,0) [0|1] ""  BCM_HS
 SG_ PedFrndlyAlrtCsCrStVal : 2|3@0+ (1,0) [0|7] ""  BCM_HS

BO_ 563 Performance_Mode_Cust_Setings_HS: 5 EBCM_HS
 SG_ SPMCA_SusPrfMd6Avl : 32|1@0+ (1,0) [0|1] ""  BCM_HS
 SG_ SPMCA_SusPrfMd5Avl : 33|1@0+ (1,0) [0|1] ""  BCM_HS
 SG_ SPMCA_SusPrfMd4Avl : 34|1@0+ (1,0) [0|1] ""  BCM_HS
 SG_ SPMCA_SusPrfMd3Avl : 35|1@0+ (1,0) [0|1] ""  BCM_HS
 SG_ SPMCA_SusPrfMd2Avl : 36|1@0+ (1,0) [0|1] ""  BCM_HS
 SG_ SPMCA_SusPrfMd1Avl : 37|1@0+ (1,0) [0|1] ""  BCM_HS
 SG_ SPMCA_StrPrfMd6Avl : 24|1@0+ (1,0) [0|1] ""  BCM_HS
 SG_ SPMCA_StrPrfMd5Avl : 25|1@0+ (1,0) [0|1] ""  BCM_HS
 SG_ SPMCA_StrPrfMd4Avl : 26|1@0+ (1,0) [0|1] ""  BCM_HS
 SG_ SPMCA_StrPrfMd3Avl : 27|1@0+ (1,0) [0|1] ""  BCM_HS
 SG_ SPMCA_StrPrfMd2Avl : 28|1@0+ (1,0) [0|1] ""  BCM_HS
 SG_ SPMCA_StrPrfMd1Avl : 29|1@0+ (1,0) [0|1] ""  BCM_HS
 SG_ SPMCA_SndPrfMd6Avl : 16|1@0+ (1,0) [0|1] ""  BCM_HS
 SG_ SPMCA_SndPrfMd5Avl : 17|1@0+ (1,0) [0|1] ""  BCM_HS
 SG_ SPMCA_SndPrfMd4Avl : 18|1@0+ (1,0) [0|1] ""  BCM_HS
 SG_ SPMCA_SndPrfMd3Avl : 19|1@0+ (1,0) [0|1] ""  BCM_HS
 SG_ SPMCA_SndPrfMd2Avl : 20|1@0+ (1,0) [0|1] ""  BCM_HS
 SG_ SPMCA_SndPrfMd1Avl : 21|1@0+ (1,0) [0|1] ""  BCM_HS
 SG_ DPMCA_DispPrfMd6Avl : 8|1@0+ (1,0) [0|1] ""  BCM_HS
 SG_ DPMCA_DispPrfMd5Avl : 9|1@0+ (1,0) [0|1] ""  BCM_HS
 SG_ DPMCA_DispPrfMd4Avl : 10|1@0+ (1,0) [0|1] ""  BCM_HS
 SG_ DPMCA_DispPrfMd3Avl : 11|1@0+ (1,0) [0|1] ""  BCM_HS
 SG_ DPMCA_DispPrfMd2Avl : 12|1@0+ (1,0) [0|1] ""  BCM_HS
 SG_ DPMCA_DispPrfMd1Avl : 13|1@0+ (1,0) [0|1] ""  BCM_HS
 SG_ DPMCA_DrvlPrfMd6Avl : 0|1@0+ (1,0) [0|1] ""  BCM_HS
 SG_ DPMCA_DrvlPrfMd5Avl : 1|1@0+ (1,0) [0|1] ""  BCM_HS
 SG_ DPMCA_DrvlPrfMd4Avl : 2|1@0+ (1,0) [0|1] ""  BCM_HS
 SG_ DPMCA_DrvlPrfMd3Avl : 3|1@0+ (1,0) [0|1] ""  BCM_HS
 SG_ DPMCA_DrvlPrfMd2Avl : 4|1@0+ (1,0) [0|1] ""  BCM_HS
 SG_ DPMCA_DrvlPrfMd1Avl : 5|1@0+ (1,0) [0|1] ""  BCM_HS

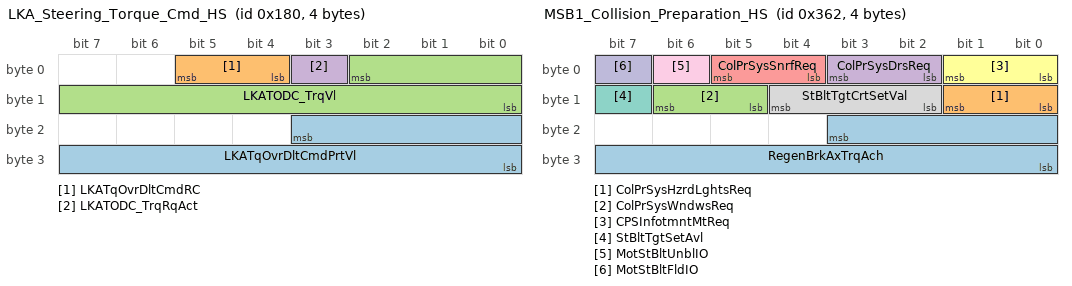
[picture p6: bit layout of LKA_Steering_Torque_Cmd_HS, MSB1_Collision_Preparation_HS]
BO_ 384 LKA_Steering_Torque_Cmd_HS: 4 CGM_HS
 SG_ LKATqOvrDltCmdPrtVl : 19|12@0+ (1,0) [0|4095] ""  EPS_HS
 SG_ LKATqOvrDltCmdRC : 5|2@0+ (1,0) [0|3] ""  EPS_HS
 SG_ LKATODC_TrqVl : 2|11@0- (0.01,0) [-10.24|10.23] "Nm"  EPS_HS,BCM_HS
 SG_ LKATODC_TrqRqAct : 3|1@0+ (1,0) [0|1] ""  EPS_HS,BCM_HS

BO_ 866 MSB1_Collision_Preparation_HS: 4 EBCM_HS
 SG_ RegenBrkAxTrqAch : 19|12@0+ (2,0) [0|8190] "Nm" Vector__XXX
 SG_ ColPrSysHzrdLghtsReq : 9|2@0+ (1,0) [0|3] ""  BCM_HS
 SG_ ColPrSysWndwsReq : 14|2@0+ (1,0) [0|3] ""  BCM_HS
 SG_ ColPrSysDrsReq : 3|2@0+ (1,0) [0|3] ""  BCM_HS
 SG_ ColPrSysSnrfReq : 5|2@0+ (1,0) [0|3] ""  BCM_HS
 SG_ CPSInfotmntMtReq : 1|2@0+ (1,0) [0|3] ""  BCM_HS
 SG_ StBltTgtSetAvl : 15|1@0+ (1,0) [0|1] ""  BCM_HS
 SG_ StBltTgtCrtSetVal : 12|3@0+ (1,0) [0|7] ""  BCM_HS
 SG_ MotStBltUnblIO : 6|1@0+ (1,0) [0|1] ""  BCM_HS
 SG_ MotStBltFldIO : 7|1@0+ (1,0) [0|1] ""  BCM_HS

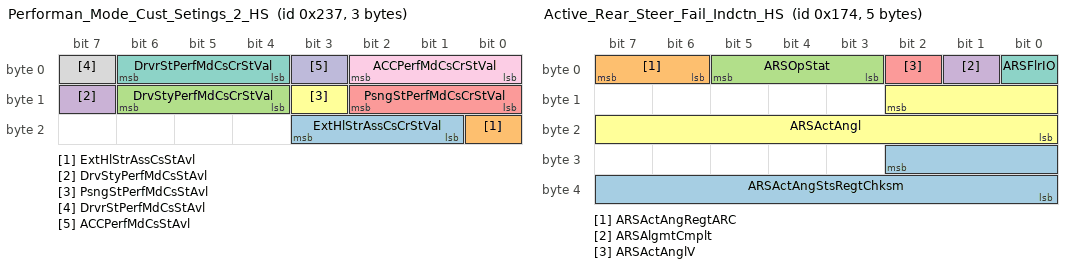
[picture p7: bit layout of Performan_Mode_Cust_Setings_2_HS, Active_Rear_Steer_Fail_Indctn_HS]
BO_ 567 Performan_Mode_Cust_Setings_2_HS: 3 EBCM_HS
 SG_ ExtHlStrAssCsCrStVal : 19|3@0+ (1,0) [0|7] ""  BCM_HS
 SG_ ExtHlStrAssCsStAvl : 16|1@0+ (1,0) [0|1] ""  BCM_HS
 SG_ DrvStyPerfMdCsCrStVal : 14|3@0+ (1,0) [0|7] ""  BCM_HS
 SG_ DrvStyPerfMdCsStAvl : 15|1@0+ (1,0) [0|1] ""  BCM_HS
 SG_ PsngStPerfMdCsCrStVal : 10|3@0+ (1,0) [0|7] ""  BCM_HS
 SG_ PsngStPerfMdCsStAvl : 11|1@0+ (1,0) [0|1] ""  BCM_HS
 SG_ DrvrStPerfMdCsCrStVal : 6|3@0+ (1,0) [0|7] ""  BCM_HS
 SG_ DrvrStPerfMdCsStAvl : 7|1@0+ (1,0) [0|1] ""  BCM_HS
 SG_ ACCPerfMdCsCrStVal : 2|3@0+ (1,0) [0|7] ""  BCM_HS
 SG_ ACCPerfMdCsStAvl : 3|1@0+ (1,0) [0|1] ""  BCM_HS

BO_ 372 Active_Rear_Steer_Fail_Indctn_HS: 5 EBCM_HS
 SG_ ARSActAngStsRegtChksm : 26|11@0+ (1,0) [0|2047] ""  CGM_HS
 SG_ ARSActAngRegtARC : 7|2@0+ (1,0) [0|3] ""  CGM_HS
 SG_ ARSOpStat : 5|3@0+ (1,0) [0|7] ""  CGM_HS
 SG_ ARSAlgmtCmplt : 1|1@0+ (1,0) [0|1] ""  CGM_HS
 SG_ ARSActAnglV : 2|1@0+ (1,0) [0|1] ""  CGM_HS
 SG_ ARSActAngl : 10|11@0- (0.01,0) [-10.24|10.23] "deg"  CGM_HS
 SG_ ARSFlrIO : 0|1@0+ (1,0) [0|1] ""  CGM_HS,BCM_HS

BO_TX_BU_ 1362 : CGM_HS,HMIM_HS;
BO_TX_BU_ 1618 : CGM_HS,HMIM_HS;
BO_TX_BU_ 1357 : CGM_HS,ONSTAR_HS;
BO_TX_BU_ 1613 : CGM_HS,ONSTAR_HS;
BO_TX_BU_ 2027 : ICCM_OBD_HS,ICCM_HS;
BO_TX_BU_ 1515 : ICCM_OBD_HS,ICCM_HS;
BO_TX_BU_ 607 : ONSTAR_HS,TestTool_HS;
BO_TX_BU_ 606 : CGM_HS,ONSTAR_HS,TestTool_HS;
BO_TX_BU_ 605 : CGM_HS,ONSTAR_HS,TestTool_HS;
BO_TX_BU_ 604 : CGM_HS,ONSTAR_HS,TestTool_HS;
BO_TX_BU_ 602 : CGM_HS,ONSTAR_HS,TestTool_HS;
BO_TX_BU_ 600 : CGM_HS,ONSTAR_HS,TestTool_HS;
BO_TX_BU_ 595 : ONSTAR_HS,TestTool_HS;
BO_TX_BU_ 801 : ICCM_OBD_HS,ICCM_HS;
BO_TX_BU_ 579 : CGM_HS,ONSTAR_HS,TestTool_HS;
BO_TX_BU_ 844 : EBCM_OBD_HS,EBCM_HS;
BO_TX_BU_ 528 : EBCM_OBD_HS,EBCM_HS;
BO_TX_BU_ 462 : EBCM_OBD_HS,EBCM_HS;
BO_TX_BU_ 510 : EBCM_OBD_HS,EBCM_HS;
BO_TX_BU_ 1920 : EBCM_OBD_HS,EBCM_HS;
BO_TX_BU_ 1907 : EBCM_OBD_HS,EBCM_HS;
BO_TX_BU_ 603 : CGM_HS,ONSTAR_HS,TestTool_HS;
BO_TX_BU_ 563 : EBCM_OBD_HS,EBCM_HS;
BO_TX_BU_ 866 : EBCM_OBD_HS,EBCM_HS;
BO_TX_BU_ 567 : EBCM_OBD_HS,EBCM_HS;
BO_TX_BU_ 372 : EBCM_OBD_HS,EBCM_HS;
CM_ SG_ 1931 DTCI_DTCFailType_78B "Assigned per GMW3110, Appendix E";
CM_ SG_ 1931 DTCI_DTCFaultType_78B "Based on Powertrain definition.  Not expected to be supported by all devices.";
CM_ SG_ 1931 DTCI_DTCSource_78B "This shall be equal to the Diagnostic Address of the transmittting device.";
CM_ SG_ 1928 DTCI_DTCFailType_788 "Assigned per GMW3110, Appendix E";
CM_ SG_ 1928 DTCI_DTCFaultType_788 "Based on Powertrain definition.  Not expected to be supported by all devices.";
CM_ SG_ 1928 DTCI_DTCSource_788 "This shall be equal to the Diagnostic Address of the transmittting device.";
CM_ SG_ 1925 DTCI_DTCFailType_785 "Assigned per GMW3110, Appendix E";
CM_ SG_ 1925 DTCI_DTCFaultType_785 "Based on Powertrain definition.  Not expected to be supported by all devices.";
CM_ SG_ 1925 DTCI_DTCSource_785 "This shall be equal to the Diagnostic Address of the transmittting device.";
CM_ SG_ 1922 DTCI_DTCSource_782 "This shall be equal to the Diagnostic Address of the transmittting device.";
CM_ SG_ 1922 DTCI_DTCFaultType_782 "Based on Powertrain definition.  Not expected to be supported by all devices.";
CM_ SG_ 1922 DTCI_DTCFailType_782 "Assigned per GMW3110, Appendix E";
CM_ SG_ 1904 DTCI_DTCSource_770 "This shall be equal to the Diagnostic Address of the transmittting device.";
CM_ SG_ 1904 DTCI_DTCFaultType_770 "Based on Powertrain definition.  Not expected to be supported by all devices.";
CM_ SG_ 1904 DTCI_DTCFailType_770 "Assigned per GMW3110, Appendix E";
CM_ SG_ 1921 DTCI_DTCSource_781 "This shall be equal to the Diagnostic Address of the transmittting device.";
CM_ SG_ 1921 DTCI_DTCFaultType_781 "Based on Powertrain definition.  Not expected to be supported by all devices.";
CM_ SG_ 1921 DTCI_DTCFailType_781 "Assigned per GMW3110, Appendix E";
CM_ SG_ 1912 DTCI_DTCFaultType_778 "Based on Powertrain definition.  Not expected to be supported by all devices.";
CM_ SG_ 1912 DTCI_DTCFailType_778 "Assigned per GMW3110, Appendix E";
CM_ SG_ 1912 DTCI_DTCSource_778 "This shall be equal to the Diagnostic Address of the transmittting device.";
CM_ SG_ 801 WBRP_RtFrt "Negative values indicate Compression, Positive values indicate Extension.";
CM_ SG_ 801 WBRP_RtRr "Negative values indicate Compression, Positive values indicate Extension.";
CM_ SG_ 801 WBRP_LftRr "Negative values indicate Compression, Positive values indicate Extension.";
CM_ SG_ 801 WBRP_LftFrt "Negative values indicate Compression, Positive values indicate Extension.";
CM_ SG_ 1920 DTCI_DTCSource_780 "This shall be equal to the Diagnostic Address of the transmittting device.";
CM_ SG_ 1920 DTCI_DTCFaultType_780 "Based on Powertrain definition.  Not expected to be supported by all devices.";
CM_ SG_ 1920 DTCI_DTCFailType_780 "Assigned per GMW3110, Appendix E";
CM_ SG_ 1907 DTCI_DTCFaultType_773 "Based on Powertrain definition.  Not expected to be supported by all devices.";
CM_ SG_ 1907 DTCI_DTCFailType_773 "Assigned per GMW3110, Appendix E";
CM_ SG_ 1907 DTCI_DTCSource_773 "This shall be equal to the Diagnostic Address of the transmittting device.";
CM_ SG_ 1915 DTCI_DTCFaultType_77B "Based on Powertrain definition.  Not expected to be supported by all devices.";
CM_ SG_ 1915 DTCI_DTCFailType_77B "Assigned per GMW3110, Appendix E";
CM_ SG_ 1915 DTCI_DTCSource_77B "This shall be equal to the Diagnostic Address of the transmittting device.";
BA_DEF_ SG_  "VNSigSLHSSharedDiagnostic" ENUM  "No","Yes";
BA_DEF_ SG_  "VNSigSLHS_VNReq" ENUM  "No","Yes";
BA_DEF_ SG_  "GenSigSendOnInit" ENUM  "Not Initialized","Application","Handler";
BA_DEF_ SG_  "GenSigSendType" ENUM  "not used","not used","not used","not used","not used","not used","not used","NoSigSendType","not used","not used","OnAnyChange","OnChangeIfActive","OnDelta";
BA_DEF_ SG_  "GenSigDeltaValue" INT 0 0;
BA_DEF_ SG_  "VNSigAllNodes" ENUM  "No","Yes";
BA_DEF_ SG_  "SignalType" STRING ;
BA_DEF_ SG_  "PacketOrder" INT 0 65535;
BA_DEF_ SG_  "SignalLongName" STRING ;
BA_DEF_ SG_  "GenSigStartValue" INT 0 65535;
BA_DEF_ SG_  "TxSignalSendOnInit" ENUM  "Not Initialized","Application","Handler";
BA_DEF_ BO_  "GenMsgILSupport" ENUM  "No","Yes";
BA_DEF_ BO_  "AppGenMsgCycleTime" INT 0 0;
BA_DEF_ BO_  "TpApplType" STRING ;
BA_DEF_ BO_  "Prio" INT 0 7;
BA_DEF_ BO_  "MessageSubnet" ENUM  "LS","MS","HS","CE","PE","HV","FO","S1","HE","LE","HE2","vector_leerstring";
BA_DEF_ BO_  "DiagState" ENUM  "No","Yes";
BA_DEF_ BO_  "GenMsgIlSupport" ENUM  "No","Yes";
BA_DEF_ BO_  "GenMsgStartDelayTime" INT 0 100000;
BA_DEF_ BO_  "GenMsgDelayTime" INT 0 100000;
BA_DEF_ BO_  "GenMsgCycleTime" INT 0 100000;
BA_DEF_ BO_  "GenMsgSendType" ENUM  "cyclicX","spontanX","cyclicIfActiveX","spontanWithDelay","cyclicAndSpontanX","cyclicAndSpontanWithDelay","spontanWithRepitition","cyclicIfActiveAndSpontanWD";
BA_DEF_ BO_  "DiagResponse" ENUM  "No","Yes";
BA_DEF_ BO_  "DiagRequest" ENUM  "No","Yes";
BA_DEF_ BO_  "NmMessage" ENUM  "No","Yes";
BA_DEF_REL_ BU_SG_REL_  "GenSigSuprvResp" ENUM  "None","Notify App","Substitute Default";
BA_DEF_REL_ BU_SG_REL_  "GenSigSuprvRespSubValue" INT 0 65535;
BA_DEF_REL_ BU_SG_REL_  "GenSigRxStartValue" STRING ;
BA_DEF_REL_ BU_SG_REL_  "GenSigVDAFailResp" ENUM  "No","Yes";
BA_DEF_REL_ BU_SG_REL_  "GenSigVDAFailComment" STRING ;
BA_DEF_REL_ BU_SG_REL_  "GenSigVBitRespComment" STRING ;
BA_DEF_REL_ BU_SG_REL_  "GenSigVBitResp" ENUM  "No","Yes";
BA_DEF_REL_ BU_SG_REL_  "GenSigSuprvRespComment" STRING ;
BA_DEF_REL_ BU_SG_REL_  "GenSigTimeoutMsg" HEX 0 268435455;
BA_DEF_REL_ BU_SG_REL_  "GenSigTimeoutTime" INT 0 5000;
BA_DEF_DEF_  "VNSigSLHSSharedDiagnostic" "No";
BA_DEF_DEF_  "VNSigSLHS_VNReq" "No";
BA_DEF_DEF_  "GenSigSendOnInit" "Not Initialized";
BA_DEF_DEF_  "GenSigSendType" "NoSigSendType";
BA_DEF_DEF_  "GenSigDeltaValue" 0;
BA_DEF_DEF_  "VNSigAllNodes" "No";
BA_DEF_DEF_  "SignalType" "";
BA_DEF_DEF_  "PacketOrder" 0;
BA_DEF_DEF_  "SignalLongName" "";
BA_DEF_DEF_  "GenSigStartValue" 0;
BA_DEF_DEF_  "TxSignalSendOnInit" "Not Initialized";
BA_DEF_DEF_  "GenMsgILSupport" "Yes";
BA_DEF_DEF_  "AppGenMsgCycleTime" 0;
BA_DEF_DEF_  "TpApplType" "";
BA_DEF_DEF_  "Prio" 0;
BA_DEF_DEF_  "MessageSubnet" "LS";
BA_DEF_DEF_  "DiagState" "No";
BA_DEF_DEF_  "GenMsgIlSupport" "Yes";
BA_DEF_DEF_  "GenMsgStartDelayTime" 0;
BA_DEF_DEF_  "GenMsgDelayTime" 0;
BA_DEF_DEF_  "GenMsgCycleTime" 0;
BA_DEF_DEF_  "GenMsgSendType" "spontanX";
BA_DEF_DEF_  "DiagResponse" "No";
BA_DEF_DEF_  "DiagRequest" "No";
BA_DEF_DEF_  "NmMessage" "No";
BA_DEF_DEF_REL_ "GenSigSuprvResp" "None";
BA_DEF_DEF_REL_ "GenSigSuprvRespSubValue" 0;
BA_DEF_DEF_REL_ "GenSigRxStartValue" "";
BA_DEF_DEF_REL_ "GenSigVDAFailResp" "No";
BA_DEF_DEF_REL_ "GenSigVDAFailComment" "";
BA_DEF_DEF_REL_ "GenSigVBitRespComment" "";
BA_DEF_DEF_REL_ "GenSigVBitResp" "No";
BA_DEF_DEF_REL_ "GenSigSuprvRespComment" "";
BA_DEF_DEF_REL_ "GenSigTimeoutMsg" 0;
BA_DEF_DEF_REL_ "GenSigTimeoutTime" 0;
BA_ "GenMsgSendType" BO_ 1931 0;
BA_ "GenMsgCycleTime" BO_ 1931 1000;
BA_ "MessageSubnet" BO_ 1931 2;
BA_ "GenMsgSendType" BO_ 1928 0;
BA_ "GenMsgCycleTime" BO_ 1928 1000;
BA_ "MessageSubnet" BO_ 1928 2;
BA_ "GenMsgSendType" BO_ 1925 0;
BA_ "GenMsgCycleTime" BO_ 1925 1000;
BA_ "MessageSubnet" BO_ 1925 2;
BA_ "GenMsgSendType" BO_ 1922 0;
BA_ "GenMsgCycleTime" BO_ 1922 1000;
BA_ "MessageSubnet" BO_ 1922 2;
BA_ "GenMsgSendType" BO_ 1904 0;
BA_ "GenMsgCycleTime" BO_ 1904 1000;
BA_ "MessageSubnet" BO_ 1904 2;
BA_ "Prio" BO_ 1904 6;
BA_ "GenMsgSendType" BO_ 1921 0;
BA_ "GenMsgCycleTime" BO_ 1921 1000;
BA_ "MessageSubnet" BO_ 1921 2;
BA_ "GenMsgSendType" BO_ 1912 0;
BA_ "GenMsgCycleTime" BO_ 1912 1000;
BA_ "MessageSubnet" BO_ 1912 2;
BA_ "Prio" BO_ 1912 6;
BA_ "DiagResponse" BO_ 1610 1;
BA_ "MessageSubnet" BO_ 1610 2;
BA_ "MessageSubnet" BO_ 1363 2;
BA_ "TpApplType" BO_ 1363 "DiagUUDTResponse";
BA_ "GenMsgILSupport" BO_ 1363 0;
BA_ "DiagResponse" BO_ 1631 1;
BA_ "MessageSubnet" BO_ 1631 2;
BA_ "MessageSubnet" BO_ 1375 2;
BA_ "TpApplType" BO_ 1375 "DiagUUDTResponse";
BA_ "GenMsgILSupport" BO_ 1375 0;
BA_ "MessageSubnet" BO_ 1372 2;
BA_ "TpApplType" BO_ 1372 "DiagUUDTResponse";
BA_ "GenMsgILSupport" BO_ 1372 0;
BA_ "MessageSubnet" BO_ 1362 2;
BA_ "TpApplType" BO_ 1362 "DiagUUDTResponse";
BA_ "GenMsgILSupport" BO_ 1362 0;
BA_ "DiagResponse" BO_ 1628 1;
BA_ "MessageSubnet" BO_ 1628 2;
BA_ "DiagResponse" BO_ 1619 1;
BA_ "MessageSubnet" BO_ 1619 2;
BA_ "DiagResponse" BO_ 1618 1;
BA_ "MessageSubnet" BO_ 1618 2;
BA_ "MessageSubnet" BO_ 1357 2;
BA_ "TpApplType" BO_ 1357 "DiagUUDTResponse";
BA_ "GenMsgILSupport" BO_ 1357 0;
BA_ "DiagResponse" BO_ 1613 1;
BA_ "MessageSubnet" BO_ 1613 2;
BA_ "DiagResponse" BO_ 1606 1;
BA_ "MessageSubnet" BO_ 1606 2;
BA_ "MessageSubnet" BO_ 1356 2;
BA_ "TpApplType" BO_ 1356 "DiagUUDTResponse";
BA_ "GenMsgILSupport" BO_ 1356 0;
BA_ "MessageSubnet" BO_ 1350 2;
BA_ "TpApplType" BO_ 1350 "DiagUUDTResponse";
BA_ "GenMsgILSupport" BO_ 1350 0;
BA_ "DiagResponse" BO_ 2029 1;
BA_ "MessageSubnet" BO_ 2029 2;
BA_ "MessageSubnet" BO_ 1517 2;
BA_ "TpApplType" BO_ 1517 "DiagUUDTResponse";
BA_ "GenMsgILSupport" BO_ 1517 0;
BA_ "MessageSubnet" BO_ 1346 2;
BA_ "TpApplType" BO_ 1346 "DiagUUDTResponse";
BA_ "GenMsgILSupport" BO_ 1346 0;
BA_ "DiagResponse" BO_ 1602 1;
BA_ "MessageSubnet" BO_ 1602 2;
BA_ "DiagResponse" BO_ 2027 1;
BA_ "MessageSubnet" BO_ 2027 2;
BA_ "MessageSubnet" BO_ 1515 2;
BA_ "TpApplType" BO_ 1515 "DiagUUDTResponse";
BA_ "GenMsgILSupport" BO_ 1515 0;
BA_ "MessageSubnet" BO_ 1354 2;
BA_ "TpApplType" BO_ 1354 "DiagUUDTResponse";
BA_ "GenMsgILSupport" BO_ 1354 0;
BA_ "DiagResponse" BO_ 1612 1;
BA_ "MessageSubnet" BO_ 1612 2;
BA_ "GenMsgILSupport" BO_ 1612 0;
BA_ "DiagRequest" BO_ 607 1;
BA_ "MessageSubnet" BO_ 607 2;
BA_ "DiagRequest" BO_ 606 1;
BA_ "MessageSubnet" BO_ 606 2;
BA_ "GenMsgILSupport" BO_ 606 0;
BA_ "DiagRequest" BO_ 605 1;
BA_ "MessageSubnet" BO_ 605 2;
BA_ "GenMsgILSupport" BO_ 605 0;
BA_ "DiagRequest" BO_ 604 1;
BA_ "MessageSubnet" BO_ 604 2;
BA_ "DiagRequest" BO_ 602 1;
BA_ "MessageSubnet" BO_ 602 2;
BA_ "DiagRequest" BO_ 600 1;
BA_ "MessageSubnet" BO_ 600 2;
BA_ "DiagRequest" BO_ 595 1;
BA_ "MessageSubnet" BO_ 595 2;
BA_ "GenMsgSendType" BO_ 1034 0;
BA_ "GenMsgCycleTime" BO_ 1034 100;
BA_ "MessageSubnet" BO_ 1034 2;
BA_ "GenMsgSendType" BO_ 1033 0;
BA_ "GenMsgCycleTime" BO_ 1033 100;
BA_ "MessageSubnet" BO_ 1033 2;
BA_ "GenMsgSendType" BO_ 800 0;
BA_ "GenMsgCycleTime" BO_ 800 100;
BA_ "GenMsgDelayTime" BO_ 800 10;
BA_ "MessageSubnet" BO_ 800 2;
BA_ "GenMsgSendType" BO_ 554 0;
BA_ "GenMsgCycleTime" BO_ 554 100;
BA_ "MessageSubnet" BO_ 554 2;
BA_ "GenMsgSendType" BO_ 464 0;
BA_ "GenMsgCycleTime" BO_ 464 20;
BA_ "MessageSubnet" BO_ 464 2;
BA_ "GenMsgSendType" BO_ 465 0;
BA_ "GenMsgCycleTime" BO_ 465 20;
BA_ "MessageSubnet" BO_ 465 2;
BA_ "GenMsgSendType" BO_ 801 0;
BA_ "GenMsgCycleTime" BO_ 801 25;
BA_ "MessageSubnet" BO_ 801 2;
BA_ "DiagRequest" BO_ 579 1;
BA_ "MessageSubnet" BO_ 579 2;
BA_ "GenMsgSendType" BO_ 844 0;
BA_ "GenMsgCycleTime" BO_ 844 50;
BA_ "MessageSubnet" BO_ 844 2;
BA_ "GenMsgSendType" BO_ 528 0;
BA_ "GenMsgCycleTime" BO_ 528 50;
BA_ "MessageSubnet" BO_ 528 2;
BA_ "GenMsgSendType" BO_ 462 0;
BA_ "GenMsgCycleTime" BO_ 462 20;
BA_ "MessageSubnet" BO_ 462 2;
BA_ "GenMsgSendType" BO_ 510 0;
BA_ "GenMsgCycleTime" BO_ 510 50;
BA_ "MessageSubnet" BO_ 510 2;
BA_ "GenMsgSendType" BO_ 1920 0;
BA_ "GenMsgCycleTime" BO_ 1920 1000;
BA_ "MessageSubnet" BO_ 1920 2;
BA_ "GenMsgSendType" BO_ 1907 0;
BA_ "GenMsgCycleTime" BO_ 1907 1000;
BA_ "MessageSubnet" BO_ 1907 2;
BA_ "Prio" BO_ 1907 6;
BA_ "DiagResponse" BO_ 1603 1;
BA_ "MessageSubnet" BO_ 1603 2;
BA_ "MessageSubnet" BO_ 1347 2;
BA_ "TpApplType" BO_ 1347 "DiagUUDTResponse";
BA_ "GenMsgILSupport" BO_ 1347 0;
BA_ "DiagRequest" BO_ 603 1;
BA_ "MessageSubnet" BO_ 603 2;
BA_ "MessageSubnet" BO_ 1371 2;
BA_ "TpApplType" BO_ 1371 "DiagUUDTResponse";
BA_ "GenMsgILSupport" BO_ 1371 0;
BA_ "DiagResponse" BO_ 1627 1;
BA_ "MessageSubnet" BO_ 1627 2;
BA_ "GenMsgSendType" BO_ 1915 0;
BA_ "GenMsgCycleTime" BO_ 1915 1000;
BA_ "MessageSubnet" BO_ 1915 2;
BA_ "Prio" BO_ 1915 6;
BA_ "GenMsgSendType" BO_ 353 0;
BA_ "GenMsgCycleTime" BO_ 353 100;
BA_ "MessageSubnet" BO_ 353 2;
BA_ "GenMsgSendType" BO_ 308 0;
BA_ "GenMsgCycleTime" BO_ 308 1000;
BA_ "MessageSubnet" BO_ 308 2;
BA_ "GenMsgSendType" BO_ 563 0;
BA_ "GenMsgCycleTime" BO_ 563 2000;
BA_ "MessageSubnet" BO_ 563 2;
BA_ "GenMsgSendType" BO_ 384 0;
BA_ "GenMsgCycleTime" BO_ 384 100;
BA_ "GenMsgDelayTime" BO_ 384 10;
BA_ "MessageSubnet" BO_ 384 2;
BA_ "GenMsgSendType" BO_ 866 0;
BA_ "GenMsgCycleTime" BO_ 866 50;
BA_ "MessageSubnet" BO_ 866 2;
BA_ "GenMsgSendType" BO_ 567 0;
BA_ "GenMsgCycleTime" BO_ 567 250;
BA_ "MessageSubnet" BO_ 567 2;
BA_ "GenMsgSendType" BO_ 372 0;
BA_ "GenMsgCycleTime" BO_ 372 100;
BA_ "MessageSubnet" BO_ 372 2;
BA_ "SignalLongName" SG_ 1931 DTCI_CodeSupported_78B "Diagnostic Trouble Code Information Extended 78B : Code Supported";
BA_ "PacketOrder" SG_ 1931 DTCI_CodeSupported_78B 19;
BA_ "SignalType" SG_ 1931 DTCI_CodeSupported_78B "BLN";
BA_ "VNSigAllNodes" SG_ 1931 DTCI_CodeSupported_78B 1;
BA_ "SignalLongName" SG_ 1931 DTCI_CurrentStatus_78B "Diagnostic Trouble Code Information Extended 78B : Current Status";
BA_ "PacketOrder" SG_ 1931 DTCI_CurrentStatus_78B 18;
BA_ "SignalType" SG_ 1931 DTCI_CurrentStatus_78B "BLN";
BA_ "VNSigAllNodes" SG_ 1931 DTCI_CurrentStatus_78B 1;
BA_ "SignalLongName" SG_ 1931 DTCI_DTCFailType_78B "Diagnostic Trouble Code Information Extended 78B : Diagnostic Trouble Code Failure Type";
BA_ "PacketOrder" SG_ 1931 DTCI_DTCFailType_78B 11;
BA_ "SignalType" SG_ 1931 DTCI_DTCFailType_78B "UNM";
BA_ "VNSigAllNodes" SG_ 1931 DTCI_DTCFailType_78B 1;
BA_ "SignalLongName" SG_ 1931 DTCI_DTCFaultType_78B "Diagnostic Trouble Code Information Extended 78B : Diagnostic Trouble Code Fault Type";
BA_ "PacketOrder" SG_ 1931 DTCI_DTCFaultType_78B 20;
BA_ "SignalType" SG_ 1931 DTCI_DTCFaultType_78B "ENM";
BA_ "VNSigAllNodes" SG_ 1931 DTCI_DTCFaultType_78B 1;
BA_ "SignalLongName" SG_ 1931 DTCI_DTCNumber_78B "Diagnostic Trouble Code Information Extended 78B : Diagnostic Trouble Code Number";
BA_ "PacketOrder" SG_ 1931 DTCI_DTCNumber_78B 10;
BA_ "SignalType" SG_ 1931 DTCI_DTCNumber_78B "UNM";
BA_ "VNSigAllNodes" SG_ 1931 DTCI_DTCNumber_78B 1;
BA_ "SignalLongName" SG_ 1931 DTCI_DTCSource_78B "Diagnostic Trouble Code Information Extended 78B : Diagnostic Trouble Code Source";
BA_ "PacketOrder" SG_ 1931 DTCI_DTCSource_78B 9;
BA_ "SignalType" SG_ 1931 DTCI_DTCSource_78B "UNM";
BA_ "VNSigAllNodes" SG_ 1931 DTCI_DTCSource_78B 1;
BA_ "SignalLongName" SG_ 1931 DTCI_DTCTriggered_78B "Diagnostic Trouble Code Information Extended 78B : Diagnostic Trouble Code Triggered";
BA_ "PacketOrder" SG_ 1931 DTCI_DTCTriggered_78B 8;
BA_ "SignalType" SG_ 1931 DTCI_DTCTriggered_78B "BLN";
BA_ "VNSigAllNodes" SG_ 1931 DTCI_DTCTriggered_78B 1;
BA_ "SignalLongName" SG_ 1931 DTCI_HistStat_78B "Diagnostic Trouble Code Information Extended 78B : History Status";
BA_ "PacketOrder" SG_ 1931 DTCI_HistStat_78B 15;
BA_ "SignalType" SG_ 1931 DTCI_HistStat_78B "BLN";
BA_ "VNSigAllNodes" SG_ 1931 DTCI_HistStat_78B 1;
BA_ "SignalLongName" SG_ 1931 DTCI_TstFldCdClrdStat_78B "Diagnostic Trouble Code Information Extended 78B : Test Failed Since Code Cleared Status";
BA_ "PacketOrder" SG_ 1931 DTCI_TstFldCdClrdStat_78B 16;
BA_ "SignalType" SG_ 1931 DTCI_TstFldCdClrdStat_78B "BLN";
BA_ "VNSigAllNodes" SG_ 1931 DTCI_TstFldCdClrdStat_78B 1;
BA_ "SignalLongName" SG_ 1931 DTCI_TstFldPwrUpSt_78B "Diagnostic Trouble Code Information Extended 78B : Test Failed Since Power Up Status";
BA_ "PacketOrder" SG_ 1931 DTCI_TstFldPwrUpSt_78B 13;
BA_ "SignalType" SG_ 1931 DTCI_TstFldPwrUpSt_78B "BLN";
BA_ "VNSigAllNodes" SG_ 1931 DTCI_TstFldPwrUpSt_78B 1;
BA_ "SignalLongName" SG_ 1931 DTCI_TstNPsdCdClrdSt_78B "Diagnostic Trouble Code Information Extended 78B : Test Not Passed Since Code Cleared Status";
BA_ "PacketOrder" SG_ 1931 DTCI_TstNPsdCdClrdSt_78B 17;
BA_ "SignalType" SG_ 1931 DTCI_TstNPsdCdClrdSt_78B "BLN";
BA_ "VNSigAllNodes" SG_ 1931 DTCI_TstNPsdCdClrdSt_78B 1;
BA_ "SignalLongName" SG_ 1931 DTCI_TstNPsdPwrUpSt_78B "Diagnostic Trouble Code Information Extended 78B : Test Not Passed Since Power Up Status";
BA_ "PacketOrder" SG_ 1931 DTCI_TstNPsdPwrUpSt_78B 14;
BA_ "SignalType" SG_ 1931 DTCI_TstNPsdPwrUpSt_78B "BLN";
BA_ "VNSigAllNodes" SG_ 1931 DTCI_TstNPsdPwrUpSt_78B 1;
BA_ "SignalLongName" SG_ 1931 DTCIUnused1_78B "Diagnostic Trouble Code Information Extended 78B : Unused 1";
BA_ "PacketOrder" SG_ 1931 DTCIUnused1_78B 1;
BA_ "SignalType" SG_ 1931 DTCIUnused1_78B "BLN";
BA_ "VNSigAllNodes" SG_ 1931 DTCIUnused1_78B 1;
BA_ "SignalLongName" SG_ 1931 DTCIUnused2_78B "Diagnostic Trouble Code Information Extended 78B : Unused 2";
BA_ "PacketOrder" SG_ 1931 DTCIUnused2_78B 2;
BA_ "SignalType" SG_ 1931 DTCIUnused2_78B "BLN";
BA_ "VNSigAllNodes" SG_ 1931 DTCIUnused2_78B 1;
BA_ "SignalLongName" SG_ 1931 DTCIUnused3_78B "Diagnostic Trouble Code Information Extended 78B : Unused 3";
BA_ "PacketOrder" SG_ 1931 DTCIUnused3_78B 3;
BA_ "SignalType" SG_ 1931 DTCIUnused3_78B "BLN";
BA_ "VNSigAllNodes" SG_ 1931 DTCIUnused3_78B 1;
BA_ "SignalLongName" SG_ 1931 DTCIUnused4_78B "Diagnostic Trouble Code Information Extended 78B : Unused 4";
BA_ "PacketOrder" SG_ 1931 DTCIUnused4_78B 4;
BA_ "SignalType" SG_ 1931 DTCIUnused4_78B "BLN";
BA_ "VNSigAllNodes" SG_ 1931 DTCIUnused4_78B 1;
BA_ "SignalLongName" SG_ 1931 DTCIUnused5_78B "Diagnostic Trouble Code Information Extended 78B : Unused 5";
BA_ "PacketOrder" SG_ 1931 DTCIUnused5_78B 5;
BA_ "SignalType" SG_ 1931 DTCIUnused5_78B "BLN";
BA_ "VNSigAllNodes" SG_ 1931 DTCIUnused5_78B 1;
BA_ "SignalLongName" SG_ 1931 DTCIUnused6_78B "Diagnostic Trouble Code Information Extended 78B : Unused 6";
BA_ "PacketOrder" SG_ 1931 DTCIUnused6_78B 6;
BA_ "SignalType" SG_ 1931 DTCIUnused6_78B "BLN";
BA_ "VNSigAllNodes" SG_ 1931 DTCIUnused6_78B 1;
BA_ "SignalLongName" SG_ 1931 DTCIUnused7_78B "Diagnostic Trouble Code Information Extended 78B : Unused 7";
BA_ "PacketOrder" SG_ 1931 DTCIUnused7_78B 7;
BA_ "SignalType" SG_ 1931 DTCIUnused7_78B "BLN";
BA_ "VNSigAllNodes" SG_ 1931 DTCIUnused7_78B 1;
BA_ "SignalLongName" SG_ 1931 DTCI_WrnIndRqdSt_78B "Diagnostic Trouble Code Information Extended 78B : Warning Indicator Requested Status";
BA_ "PacketOrder" SG_ 1931 DTCI_WrnIndRqdSt_78B 12;
BA_ "SignalType" SG_ 1931 DTCI_WrnIndRqdSt_78B "BLN";
BA_ "VNSigAllNodes" SG_ 1931 DTCI_WrnIndRqdSt_78B 1;
BA_ "SignalLongName" SG_ 1928 DTCI_CodeSupported_788 "Diagnostic Trouble Code Information Extended 788 : Code Supported";
BA_ "PacketOrder" SG_ 1928 DTCI_CodeSupported_788 19;
BA_ "SignalType" SG_ 1928 DTCI_CodeSupported_788 "BLN";
BA_ "VNSigAllNodes" SG_ 1928 DTCI_CodeSupported_788 1;
BA_ "SignalLongName" SG_ 1928 DTCI_CurrentStatus_788 "Diagnostic Trouble Code Information Extended 788 : Current Status";
BA_ "PacketOrder" SG_ 1928 DTCI_CurrentStatus_788 18;
BA_ "SignalType" SG_ 1928 DTCI_CurrentStatus_788 "BLN";
BA_ "VNSigAllNodes" SG_ 1928 DTCI_CurrentStatus_788 1;
BA_ "SignalLongName" SG_ 1928 DTCI_DTCFailType_788 "Diagnostic Trouble Code Information Extended 788 : Diagnostic Trouble Code Failure Type";
BA_ "PacketOrder" SG_ 1928 DTCI_DTCFailType_788 11;
BA_ "SignalType" SG_ 1928 DTCI_DTCFailType_788 "UNM";
BA_ "VNSigAllNodes" SG_ 1928 DTCI_DTCFailType_788 1;
BA_ "SignalLongName" SG_ 1928 DTCI_DTCFaultType_788 "Diagnostic Trouble Code Information Extended 788 : Diagnostic Trouble Code Fault Type";
BA_ "PacketOrder" SG_ 1928 DTCI_DTCFaultType_788 20;
BA_ "SignalType" SG_ 1928 DTCI_DTCFaultType_788 "ENM";
BA_ "VNSigAllNodes" SG_ 1928 DTCI_DTCFaultType_788 1;
BA_ "SignalLongName" SG_ 1928 DTCI_DTCNumber_788 "Diagnostic Trouble Code Information Extended 788 : Diagnostic Trouble Code Number";
BA_ "PacketOrder" SG_ 1928 DTCI_DTCNumber_788 10;
BA_ "SignalType" SG_ 1928 DTCI_DTCNumber_788 "UNM";
BA_ "VNSigAllNodes" SG_ 1928 DTCI_DTCNumber_788 1;
BA_ "SignalLongName" SG_ 1928 DTCI_DTCSource_788 "Diagnostic Trouble Code Information Extended 788 : Diagnostic Trouble Code Source";
BA_ "PacketOrder" SG_ 1928 DTCI_DTCSource_788 9;
BA_ "SignalType" SG_ 1928 DTCI_DTCSource_788 "UNM";
BA_ "VNSigAllNodes" SG_ 1928 DTCI_DTCSource_788 1;
BA_ "SignalLongName" SG_ 1928 DTCI_DTCTriggered_788 "Diagnostic Trouble Code Information Extended 788 : Diagnostic Trouble Code Triggered";
BA_ "PacketOrder" SG_ 1928 DTCI_DTCTriggered_788 8;
BA_ "SignalType" SG_ 1928 DTCI_DTCTriggered_788 "BLN";
BA_ "VNSigAllNodes" SG_ 1928 DTCI_DTCTriggered_788 1;
BA_ "SignalLongName" SG_ 1928 DTCI_HistStat_788 "Diagnostic Trouble Code Information Extended 788 : History Status";
BA_ "PacketOrder" SG_ 1928 DTCI_HistStat_788 15;
BA_ "SignalType" SG_ 1928 DTCI_HistStat_788 "BLN";
BA_ "VNSigAllNodes" SG_ 1928 DTCI_HistStat_788 1;
BA_ "SignalLongName" SG_ 1928 DTCI_TstFldCdClrdStat_788 "Diagnostic Trouble Code Information Extended 788 : Test Failed Since Code Cleared Status";
BA_ "PacketOrder" SG_ 1928 DTCI_TstFldCdClrdStat_788 17;
BA_ "SignalType" SG_ 1928 DTCI_TstFldCdClrdStat_788 "BLN";
BA_ "VNSigAllNodes" SG_ 1928 DTCI_TstFldCdClrdStat_788 1;
BA_ "SignalLongName" SG_ 1928 DTCI_TstFldPwrUpSt_788 "Diagnostic Trouble Code Information Extended 788 : Test Failed Since Power Up Status";
BA_ "PacketOrder" SG_ 1928 DTCI_TstFldPwrUpSt_788 13;
BA_ "SignalType" SG_ 1928 DTCI_TstFldPwrUpSt_788 "BLN";
BA_ "VNSigAllNodes" SG_ 1928 DTCI_TstFldPwrUpSt_788 1;
BA_ "SignalLongName" SG_ 1928 DTCI_TstNPsdCdClrdSt_788 "Diagnostic Trouble Code Information Extended 788 : Test Not Passed Since Code Cleared Status";
BA_ "PacketOrder" SG_ 1928 DTCI_TstNPsdCdClrdSt_788 16;
BA_ "SignalType" SG_ 1928 DTCI_TstNPsdCdClrdSt_788 "BLN";
BA_ "VNSigAllNodes" SG_ 1928 DTCI_TstNPsdCdClrdSt_788 1;
BA_ "SignalLongName" SG_ 1928 DTCI_TstNPsdPwrUpSt_788 "Diagnostic Trouble Code Information Extended 788 : Test Not Passed Since Power Up Status";
BA_ "PacketOrder" SG_ 1928 DTCI_TstNPsdPwrUpSt_788 14;
BA_ "SignalType" SG_ 1928 DTCI_TstNPsdPwrUpSt_788 "BLN";
BA_ "VNSigAllNodes" SG_ 1928 DTCI_TstNPsdPwrUpSt_788 1;
BA_ "SignalLongName" SG_ 1928 DTCIUnused1_788 "Diagnostic Trouble Code Information Extended 788 : Unused 1";
BA_ "PacketOrder" SG_ 1928 DTCIUnused1_788 1;
BA_ "SignalType" SG_ 1928 DTCIUnused1_788 "BLN";
BA_ "VNSigAllNodes" SG_ 1928 DTCIUnused1_788 1;
BA_ "SignalLongName" SG_ 1928 DTCIUnused2_788 "Diagnostic Trouble Code Information Extended 788 : Unused 2";
BA_ "PacketOrder" SG_ 1928 DTCIUnused2_788 2;
BA_ "SignalType" SG_ 1928 DTCIUnused2_788 "BLN";
BA_ "VNSigAllNodes" SG_ 1928 DTCIUnused2_788 1;
BA_ "SignalLongName" SG_ 1928 DTCIUnused3_788 "Diagnostic Trouble Code Information Extended 788 : Unused 3";
BA_ "PacketOrder" SG_ 1928 DTCIUnused3_788 3;
BA_ "SignalType" SG_ 1928 DTCIUnused3_788 "BLN";
BA_ "VNSigAllNodes" SG_ 1928 DTCIUnused3_788 1;
BA_ "SignalLongName" SG_ 1928 DTCIUnused4_788 "Diagnostic Trouble Code Information Extended 788 : Unused 4";
BA_ "PacketOrder" SG_ 1928 DTCIUnused4_788 4;
BA_ "SignalType" SG_ 1928 DTCIUnused4_788 "BLN";
BA_ "VNSigAllNodes" SG_ 1928 DTCIUnused4_788 1;
BA_ "SignalLongName" SG_ 1928 DTCIUnused5_788 "Diagnostic Trouble Code Information Extended 788 : Unused 5";
BA_ "PacketOrder" SG_ 1928 DTCIUnused5_788 5;
BA_ "SignalType" SG_ 1928 DTCIUnused5_788 "BLN";
BA_ "VNSigAllNodes" SG_ 1928 DTCIUnused5_788 1;
BA_ "SignalLongName" SG_ 1928 DTCIUnused6_788 "Diagnostic Trouble Code Information Extended 788 : Unused 6";
BA_ "PacketOrder" SG_ 1928 DTCIUnused6_788 6;
BA_ "SignalType" SG_ 1928 DTCIUnused6_788 "BLN";
BA_ "VNSigAllNodes" SG_ 1928 DTCIUnused6_788 1;
BA_ "SignalLongName" SG_ 1928 DTCIUnused7_788 "Diagnostic Trouble Code Information Extended 788 : Unused 7";
BA_ "PacketOrder" SG_ 1928 DTCIUnused7_788 7;
BA_ "SignalType" SG_ 1928 DTCIUnused7_788 "BLN";
BA_ "VNSigAllNodes" SG_ 1928 DTCIUnused7_788 1;
BA_ "SignalLongName" SG_ 1928 DTCI_WrnIndRqdSt_788 "Diagnostic Trouble Code Information Extended 788 : Warning Indicator Requested Status";
BA_ "PacketOrder" SG_ 1928 DTCI_WrnIndRqdSt_788 12;
BA_ "SignalType" SG_ 1928 DTCI_WrnIndRqdSt_788 "BLN";
BA_ "VNSigAllNodes" SG_ 1928 DTCI_WrnIndRqdSt_788 1;
BA_ "SignalLongName" SG_ 1925 DTCI_CodeSupported_785 "Diagnostic Trouble Code Information Extended 785 : Code Supported";
BA_ "PacketOrder" SG_ 1925 DTCI_CodeSupported_785 19;
BA_ "SignalType" SG_ 1925 DTCI_CodeSupported_785 "BLN";
BA_ "VNSigAllNodes" SG_ 1925 DTCI_CodeSupported_785 1;
BA_ "SignalLongName" SG_ 1925 DTCI_CurrentStatus_785 "Diagnostic Trouble Code Information Extended 785 : Current Status";
BA_ "PacketOrder" SG_ 1925 DTCI_CurrentStatus_785 18;
BA_ "SignalType" SG_ 1925 DTCI_CurrentStatus_785 "BLN";
BA_ "VNSigAllNodes" SG_ 1925 DTCI_CurrentStatus_785 1;
BA_ "SignalLongName" SG_ 1925 DTCI_DTCFailType_785 "Diagnostic Trouble Code Information Extended 785 : Diagnostic Trouble Code Failure Type";
BA_ "PacketOrder" SG_ 1925 DTCI_DTCFailType_785 11;
BA_ "SignalType" SG_ 1925 DTCI_DTCFailType_785 "UNM";
BA_ "VNSigAllNodes" SG_ 1925 DTCI_DTCFailType_785 1;
BA_ "SignalLongName" SG_ 1925 DTCI_DTCFaultType_785 "Diagnostic Trouble Code Information Extended 785 : Diagnostic Trouble Code Fault Type";
BA_ "PacketOrder" SG_ 1925 DTCI_DTCFaultType_785 20;
BA_ "SignalType" SG_ 1925 DTCI_DTCFaultType_785 "ENM";
BA_ "VNSigAllNodes" SG_ 1925 DTCI_DTCFaultType_785 1;
BA_ "SignalLongName" SG_ 1925 DTCI_DTCNumber_785 "Diagnostic Trouble Code Information Extended 785 : Diagnostic Trouble Code Number";
BA_ "PacketOrder" SG_ 1925 DTCI_DTCNumber_785 10;
BA_ "SignalType" SG_ 1925 DTCI_DTCNumber_785 "UNM";
BA_ "VNSigAllNodes" SG_ 1925 DTCI_DTCNumber_785 1;
BA_ "SignalLongName" SG_ 1925 DTCI_DTCSource_785 "Diagnostic Trouble Code Information Extended 785 : Diagnostic Trouble Code Source";
BA_ "PacketOrder" SG_ 1925 DTCI_DTCSource_785 9;
BA_ "SignalType" SG_ 1925 DTCI_DTCSource_785 "UNM";
BA_ "VNSigAllNodes" SG_ 1925 DTCI_DTCSource_785 1;
BA_ "SignalLongName" SG_ 1925 DTCI_DTCTriggered_785 "Diagnostic Trouble Code Information Extended 785 : Diagnostic Trouble Code Triggered";
BA_ "PacketOrder" SG_ 1925 DTCI_DTCTriggered_785 8;
BA_ "SignalType" SG_ 1925 DTCI_DTCTriggered_785 "BLN";
BA_ "VNSigAllNodes" SG_ 1925 DTCI_DTCTriggered_785 1;
BA_ "SignalLongName" SG_ 1925 DTCI_HistStat_785 "Diagnostic Trouble Code Information Extended 785 : History Status";
BA_ "PacketOrder" SG_ 1925 DTCI_HistStat_785 15;
BA_ "SignalType" SG_ 1925 DTCI_HistStat_785 "BLN";
BA_ "VNSigAllNodes" SG_ 1925 DTCI_HistStat_785 1;
BA_ "SignalLongName" SG_ 1925 DTCI_TstFldCdClrdStat_785 "Diagnostic Trouble Code Information Extended 785 : Test Failed Since Code Cleared Status";
BA_ "PacketOrder" SG_ 1925 DTCI_TstFldCdClrdStat_785 16;
BA_ "SignalType" SG_ 1925 DTCI_TstFldCdClrdStat_785 "BLN";
BA_ "VNSigAllNodes" SG_ 1925 DTCI_TstFldCdClrdStat_785 1;
BA_ "SignalLongName" SG_ 1925 DTCI_TstFldPwrUpSt_785 "Diagnostic Trouble Code Information Extended 785 : Test Failed Since Power Up Status";
BA_ "PacketOrder" SG_ 1925 DTCI_TstFldPwrUpSt_785 13;
BA_ "SignalType" SG_ 1925 DTCI_TstFldPwrUpSt_785 "BLN";
BA_ "VNSigAllNodes" SG_ 1925 DTCI_TstFldPwrUpSt_785 1;
BA_ "SignalLongName" SG_ 1925 DTCI_TstNPsdCdClrdSt_785 "Diagnostic Trouble Code Information Extended 785 : Test Not Passed Since Code Cleared Status";
BA_ "PacketOrder" SG_ 1925 DTCI_TstNPsdCdClrdSt_785 17;
BA_ "SignalType" SG_ 1925 DTCI_TstNPsdCdClrdSt_785 "BLN";
BA_ "VNSigAllNodes" SG_ 1925 DTCI_TstNPsdCdClrdSt_785 1;
BA_ "SignalLongName" SG_ 1925 DTCI_TstNPsdPwrUpSt_785 "Diagnostic Trouble Code Information Extended 785 : Test Not Passed Since Power Up Status";
BA_ "PacketOrder" SG_ 1925 DTCI_TstNPsdPwrUpSt_785 14;
BA_ "SignalType" SG_ 1925 DTCI_TstNPsdPwrUpSt_785 "BLN";
BA_ "VNSigAllNodes" SG_ 1925 DTCI_TstNPsdPwrUpSt_785 1;
BA_ "SignalLongName" SG_ 1925 DTCIUnused1_785 "Diagnostic Trouble Code Information Extended 785 : Unused 1";
BA_ "PacketOrder" SG_ 1925 DTCIUnused1_785 1;
BA_ "SignalType" SG_ 1925 DTCIUnused1_785 "BLN";
BA_ "VNSigAllNodes" SG_ 1925 DTCIUnused1_785 1;
BA_ "SignalLongName" SG_ 1925 DTCIUnused2_785 "Diagnostic Trouble Code Information Extended 785 : Unused 2";
BA_ "PacketOrder" SG_ 1925 DTCIUnused2_785 2;
BA_ "SignalType" SG_ 1925 DTCIUnused2_785 "BLN";
BA_ "VNSigAllNodes" SG_ 1925 DTCIUnused2_785 1;
BA_ "SignalLongName" SG_ 1925 DTCIUnused3_785 "Diagnostic Trouble Code Information Extended 785 : Unused 3";
BA_ "PacketOrder" SG_ 1925 DTCIUnused3_785 3;
BA_ "SignalType" SG_ 1925 DTCIUnused3_785 "BLN";
BA_ "VNSigAllNodes" SG_ 1925 DTCIUnused3_785 1;
BA_ "SignalLongName" SG_ 1925 DTCIUnused4_785 "Diagnostic Trouble Code Information Extended 785 : Unused 4";
BA_ "PacketOrder" SG_ 1925 DTCIUnused4_785 4;
BA_ "SignalType" SG_ 1925 DTCIUnused4_785 "BLN";
BA_ "VNSigAllNodes" SG_ 1925 DTCIUnused4_785 1;
BA_ "SignalLongName" SG_ 1925 DTCIUnused5_785 "Diagnostic Trouble Code Information Extended 785 : Unused 5";
BA_ "PacketOrder" SG_ 1925 DTCIUnused5_785 5;
BA_ "SignalType" SG_ 1925 DTCIUnused5_785 "BLN";
BA_ "VNSigAllNodes" SG_ 1925 DTCIUnused5_785 1;
BA_ "SignalLongName" SG_ 1925 DTCIUnused6_785 "Diagnostic Trouble Code Information Extended 785 : Unused 6";
BA_ "PacketOrder" SG_ 1925 DTCIUnused6_785 6;
BA_ "SignalType" SG_ 1925 DTCIUnused6_785 "BLN";
BA_ "VNSigAllNodes" SG_ 1925 DTCIUnused6_785 1;
BA_ "SignalLongName" SG_ 1925 DTCIUnused7_785 "Diagnostic Trouble Code Information Extended 785 : Unused 7";
BA_ "PacketOrder" SG_ 1925 DTCIUnused7_785 7;
BA_ "SignalType" SG_ 1925 DTCIUnused7_785 "BLN";
BA_ "VNSigAllNodes" SG_ 1925 DTCIUnused7_785 1;
BA_ "SignalLongName" SG_ 1925 DTCI_WrnIndRqdSt_785 "Diagnostic Trouble Code Information Extended 785 : Warning Indicator Requested Status";
BA_ "PacketOrder" SG_ 1925 DTCI_WrnIndRqdSt_785 12;
BA_ "SignalType" SG_ 1925 DTCI_WrnIndRqdSt_785 "BLN";
BA_ "VNSigAllNodes" SG_ 1925 DTCI_WrnIndRqdSt_785 1;
BA_ "SignalLongName" SG_ 1922 DTCI_WrnIndRqdSt_782 "Diagnostic Trouble Code Information Extended 782 : Warning Indicator Requested Status";
BA_ "PacketOrder" SG_ 1922 DTCI_WrnIndRqdSt_782 12;
BA_ "SignalType" SG_ 1922 DTCI_WrnIndRqdSt_782 "BLN";
BA_ "VNSigAllNodes" SG_ 1922 DTCI_WrnIndRqdSt_782 1;
BA_ "SignalLongName" SG_ 1922 DTCIUnused7_782 "Diagnostic Trouble Code Information Extended 782 : Unused 7";
BA_ "PacketOrder" SG_ 1922 DTCIUnused7_782 7;
BA_ "SignalType" SG_ 1922 DTCIUnused7_782 "BLN";
BA_ "VNSigAllNodes" SG_ 1922 DTCIUnused7_782 1;
BA_ "SignalLongName" SG_ 1922 DTCIUnused6_782 "Diagnostic Trouble Code Information Extended 782 : Unused 6";
BA_ "PacketOrder" SG_ 1922 DTCIUnused6_782 6;
BA_ "SignalType" SG_ 1922 DTCIUnused6_782 "BLN";
BA_ "VNSigAllNodes" SG_ 1922 DTCIUnused6_782 1;
BA_ "SignalLongName" SG_ 1922 DTCIUnused5_782 "Diagnostic Trouble Code Information Extended 782 : Unused 5";
BA_ "PacketOrder" SG_ 1922 DTCIUnused5_782 5;
BA_ "SignalType" SG_ 1922 DTCIUnused5_782 "BLN";
BA_ "VNSigAllNodes" SG_ 1922 DTCIUnused5_782 1;
BA_ "SignalLongName" SG_ 1922 DTCIUnused4_782 "Diagnostic Trouble Code Information Extended 782 : Unused 4";
BA_ "PacketOrder" SG_ 1922 DTCIUnused4_782 4;
BA_ "SignalType" SG_ 1922 DTCIUnused4_782 "BLN";
BA_ "VNSigAllNodes" SG_ 1922 DTCIUnused4_782 1;
BA_ "SignalLongName" SG_ 1922 DTCIUnused3_782 "Diagnostic Trouble Code Information Extended 782 : Unused 3";
BA_ "PacketOrder" SG_ 1922 DTCIUnused3_782 3;
BA_ "SignalType" SG_ 1922 DTCIUnused3_782 "BLN";
BA_ "VNSigAllNodes" SG_ 1922 DTCIUnused3_782 1;
BA_ "SignalLongName" SG_ 1922 DTCIUnused2_782 "Diagnostic Trouble Code Information Extended 782 : Unused 2";
BA_ "PacketOrder" SG_ 1922 DTCIUnused2_782 2;
BA_ "SignalType" SG_ 1922 DTCIUnused2_782 "BLN";
BA_ "VNSigAllNodes" SG_ 1922 DTCIUnused2_782 1;
BA_ "SignalLongName" SG_ 1922 DTCIUnused1_782 "Diagnostic Trouble Code Information Extended 782 : Unused 1";
BA_ "PacketOrder" SG_ 1922 DTCIUnused1_782 1;
BA_ "SignalType" SG_ 1922 DTCIUnused1_782 "BLN";
BA_ "VNSigAllNodes" SG_ 1922 DTCIUnused1_782 1;
BA_ "SignalLongName" SG_ 1922 DTCI_TstNPsdPwrUpSt_782 "Diagnostic Trouble Code Information Extended 782 : Test Not Passed Since Power Up Status";
BA_ "PacketOrder" SG_ 1922 DTCI_TstNPsdPwrUpSt_782 14;
BA_ "SignalType" SG_ 1922 DTCI_TstNPsdPwrUpSt_782 "BLN";
BA_ "VNSigAllNodes" SG_ 1922 DTCI_TstNPsdPwrUpSt_782 1;
BA_ "SignalLongName" SG_ 1922 DTCI_TstNPsdCdClrdSt_782 "Diagnostic Trouble Code Information Extended 782 : Test Not Passed Since Code Cleared Status";
BA_ "PacketOrder" SG_ 1922 DTCI_TstNPsdCdClrdSt_782 17;
BA_ "SignalType" SG_ 1922 DTCI_TstNPsdCdClrdSt_782 "BLN";
BA_ "VNSigAllNodes" SG_ 1922 DTCI_TstNPsdCdClrdSt_782 1;
BA_ "SignalLongName" SG_ 1922 DTCI_TstFldPwrUpSt_782 "Diagnostic Trouble Code Information Extended 782 : Test Failed Since Power Up Status";
BA_ "PacketOrder" SG_ 1922 DTCI_TstFldPwrUpSt_782 13;
BA_ "SignalType" SG_ 1922 DTCI_TstFldPwrUpSt_782 "BLN";
BA_ "VNSigAllNodes" SG_ 1922 DTCI_TstFldPwrUpSt_782 1;
BA_ "SignalLongName" SG_ 1922 DTCI_TstFldCdClrdStat_782 "Diagnostic Trouble Code Information Extended 782 : Test Failed Since Code Cleared Status";
BA_ "PacketOrder" SG_ 1922 DTCI_TstFldCdClrdStat_782 16;
BA_ "SignalType" SG_ 1922 DTCI_TstFldCdClrdStat_782 "BLN";
BA_ "VNSigAllNodes" SG_ 1922 DTCI_TstFldCdClrdStat_782 1;
BA_ "SignalLongName" SG_ 1922 DTCI_HistStat_782 "Diagnostic Trouble Code Information Extended 782 : History Status";
BA_ "PacketOrder" SG_ 1922 DTCI_HistStat_782 15;
BA_ "SignalType" SG_ 1922 DTCI_HistStat_782 "BLN";
BA_ "VNSigAllNodes" SG_ 1922 DTCI_HistStat_782 1;
BA_ "SignalLongName" SG_ 1922 DTCI_DTCTriggered_782 "Diagnostic Trouble Code Information Extended 782 : Diagnostic Trouble Code Triggered";
BA_ "PacketOrder" SG_ 1922 DTCI_DTCTriggered_782 8;
BA_ "SignalType" SG_ 1922 DTCI_DTCTriggered_782 "BLN";
BA_ "VNSigAllNodes" SG_ 1922 DTCI_DTCTriggered_782 1;
BA_ "SignalLongName" SG_ 1922 DTCI_DTCSource_782 "Diagnostic Trouble Code Information Extended 782 : Diagnostic Trouble Code Source";
BA_ "PacketOrder" SG_ 1922 DTCI_DTCSource_782 9;
BA_ "SignalType" SG_ 1922 DTCI_DTCSource_782 "UNM";
BA_ "VNSigAllNodes" SG_ 1922 DTCI_DTCSource_782 1;
BA_ "SignalLongName" SG_ 1922 DTCI_DTCNumber_782 "Diagnostic Trouble Code Information Extended 782 : Diagnostic Trouble Code Number";
BA_ "PacketOrder" SG_ 1922 DTCI_DTCNumber_782 10;
BA_ "SignalType" SG_ 1922 DTCI_DTCNumber_782 "UNM";
BA_ "VNSigAllNodes" SG_ 1922 DTCI_DTCNumber_782 1;
BA_ "SignalLongName" SG_ 1922 DTCI_DTCFaultType_782 "Diagnostic Trouble Code Information Extended 782 : Diagnostic Trouble Code Fault Type";
BA_ "PacketOrder" SG_ 1922 DTCI_DTCFaultType_782 20;
BA_ "SignalType" SG_ 1922 DTCI_DTCFaultType_782 "ENM";
BA_ "VNSigAllNodes" SG_ 1922 DTCI_DTCFaultType_782 1;
BA_ "SignalLongName" SG_ 1922 DTCI_DTCFailType_782 "Diagnostic Trouble Code Information Extended 782 : Diagnostic Trouble Code Failure Type";
BA_ "PacketOrder" SG_ 1922 DTCI_DTCFailType_782 11;
BA_ "SignalType" SG_ 1922 DTCI_DTCFailType_782 "UNM";
BA_ "VNSigAllNodes" SG_ 1922 DTCI_DTCFailType_782 1;
BA_ "SignalLongName" SG_ 1922 DTCI_CurrentStatus_782 "Diagnostic Trouble Code Information Extended 782 : Current Status";
BA_ "PacketOrder" SG_ 1922 DTCI_CurrentStatus_782 18;
BA_ "SignalType" SG_ 1922 DTCI_CurrentStatus_782 "BLN";
BA_ "VNSigAllNodes" SG_ 1922 DTCI_CurrentStatus_782 1;
BA_ "SignalLongName" SG_ 1922 DTCI_CodeSupported_782 "Diagnostic Trouble Code Information Extended 782 : Code Supported";
BA_ "PacketOrder" SG_ 1922 DTCI_CodeSupported_782 19;
BA_ "SignalType" SG_ 1922 DTCI_CodeSupported_782 "BLN";
BA_ "VNSigAllNodes" SG_ 1922 DTCI_CodeSupported_782 1;
BA_ "SignalLongName" SG_ 1904 DTCI_WrnIndRqdSt_770 "Diagnostic Trouble Code Information Extended 770 : Warning Indicator Requested Status";
BA_ "PacketOrder" SG_ 1904 DTCI_WrnIndRqdSt_770 12;
BA_ "SignalType" SG_ 1904 DTCI_WrnIndRqdSt_770 "BLN";
BA_ "VNSigAllNodes" SG_ 1904 DTCI_WrnIndRqdSt_770 1;
BA_ "SignalLongName" SG_ 1904 DTCIUnused7_770 "Diagnostic Trouble Code Information Extended 770 : Unused 7";
BA_ "PacketOrder" SG_ 1904 DTCIUnused7_770 1;
BA_ "SignalType" SG_ 1904 DTCIUnused7_770 "BLN";
BA_ "VNSigAllNodes" SG_ 1904 DTCIUnused7_770 1;
BA_ "SignalLongName" SG_ 1904 DTCIUnused6_770 "Diagnostic Trouble Code Information Extended 770 : Unused 6";
BA_ "PacketOrder" SG_ 1904 DTCIUnused6_770 2;
BA_ "SignalType" SG_ 1904 DTCIUnused6_770 "BLN";
BA_ "VNSigAllNodes" SG_ 1904 DTCIUnused6_770 1;
BA_ "SignalLongName" SG_ 1904 DTCIUnused5_770 "Diagnostic Trouble Code Information Extended 770 : Unused 5";
BA_ "PacketOrder" SG_ 1904 DTCIUnused5_770 3;
BA_ "SignalType" SG_ 1904 DTCIUnused5_770 "BLN";
BA_ "VNSigAllNodes" SG_ 1904 DTCIUnused5_770 1;
BA_ "SignalLongName" SG_ 1904 DTCIUnused4_770 "Diagnostic Trouble Code Information Extended 770 : Unused 4";
BA_ "PacketOrder" SG_ 1904 DTCIUnused4_770 4;
BA_ "SignalType" SG_ 1904 DTCIUnused4_770 "BLN";
BA_ "VNSigAllNodes" SG_ 1904 DTCIUnused4_770 1;
BA_ "SignalLongName" SG_ 1904 DTCIUnused3_770 "Diagnostic Trouble Code Information Extended 770 : Unused 3";
BA_ "PacketOrder" SG_ 1904 DTCIUnused3_770 5;
BA_ "SignalType" SG_ 1904 DTCIUnused3_770 "BLN";
BA_ "VNSigAllNodes" SG_ 1904 DTCIUnused3_770 1;
BA_ "SignalLongName" SG_ 1904 DTCIUnused2_770 "Diagnostic Trouble Code Information Extended 770 : Unused 2";
BA_ "PacketOrder" SG_ 1904 DTCIUnused2_770 6;
BA_ "SignalType" SG_ 1904 DTCIUnused2_770 "BLN";
BA_ "VNSigAllNodes" SG_ 1904 DTCIUnused2_770 1;
BA_ "SignalLongName" SG_ 1904 DTCIUnused1_770 "Diagnostic Trouble Code Information Extended 770 : Unused 1";
BA_ "PacketOrder" SG_ 1904 DTCIUnused1_770 7;
BA_ "SignalType" SG_ 1904 DTCIUnused1_770 "BLN";
BA_ "VNSigAllNodes" SG_ 1904 DTCIUnused1_770 1;
BA_ "SignalLongName" SG_ 1904 DTCI_TstNPsdPwrUpSt_770 "Diagnostic Trouble Code Information Extended 770 : Test Not Passed Since Power Up Status";
BA_ "PacketOrder" SG_ 1904 DTCI_TstNPsdPwrUpSt_770 14;
BA_ "SignalType" SG_ 1904 DTCI_TstNPsdPwrUpSt_770 "BLN";
BA_ "VNSigAllNodes" SG_ 1904 DTCI_TstNPsdPwrUpSt_770 1;
BA_ "SignalLongName" SG_ 1904 DTCI_TstNPsdCdClrdSt_770 "Diagnostic Trouble Code Information Extended 770 : Test Not Passed Since Code Cleared Status";
BA_ "PacketOrder" SG_ 1904 DTCI_TstNPsdCdClrdSt_770 17;
BA_ "SignalType" SG_ 1904 DTCI_TstNPsdCdClrdSt_770 "BLN";
BA_ "VNSigAllNodes" SG_ 1904 DTCI_TstNPsdCdClrdSt_770 1;
BA_ "SignalLongName" SG_ 1904 DTCI_TstFldPwrUpSt_770 "Diagnostic Trouble Code Information Extended 770 : Test Failed Since Power Up Status";
BA_ "PacketOrder" SG_ 1904 DTCI_TstFldPwrUpSt_770 13;
BA_ "SignalType" SG_ 1904 DTCI_TstFldPwrUpSt_770 "BLN";
BA_ "VNSigAllNodes" SG_ 1904 DTCI_TstFldPwrUpSt_770 1;
BA_ "SignalLongName" SG_ 1904 DTCI_TstFldCdClrdStat_770 "Diagnostic Trouble Code Information Extended 770 : Test Failed Since Code Cleared Status";
BA_ "PacketOrder" SG_ 1904 DTCI_TstFldCdClrdStat_770 16;
BA_ "SignalType" SG_ 1904 DTCI_TstFldCdClrdStat_770 "BLN";
BA_ "VNSigAllNodes" SG_ 1904 DTCI_TstFldCdClrdStat_770 1;
BA_ "SignalLongName" SG_ 1904 DTCI_HistStat_770 "Diagnostic Trouble Code Information Extended 770 : History Status";
BA_ "PacketOrder" SG_ 1904 DTCI_HistStat_770 15;
BA_ "SignalType" SG_ 1904 DTCI_HistStat_770 "BLN";
BA_ "VNSigAllNodes" SG_ 1904 DTCI_HistStat_770 1;
BA_ "SignalLongName" SG_ 1904 DTCI_DTCTriggered_770 "Diagnostic Trouble Code Information Extended 770 : Diagnostic Trouble Code Triggered";
BA_ "PacketOrder" SG_ 1904 DTCI_DTCTriggered_770 8;
BA_ "SignalType" SG_ 1904 DTCI_DTCTriggered_770 "BLN";
BA_ "VNSigAllNodes" SG_ 1904 DTCI_DTCTriggered_770 1;
BA_ "SignalLongName" SG_ 1904 DTCI_DTCSource_770 "Diagnostic Trouble Code Information Extended 770 : Diagnostic Trouble Code Source";
BA_ "PacketOrder" SG_ 1904 DTCI_DTCSource_770 9;
BA_ "SignalType" SG_ 1904 DTCI_DTCSource_770 "UNM";
BA_ "VNSigAllNodes" SG_ 1904 DTCI_DTCSource_770 1;
BA_ "SignalLongName" SG_ 1904 DTCI_DTCNumber_770 "Diagnostic Trouble Code Information Extended 770 : Diagnostic Trouble Code Number";
BA_ "PacketOrder" SG_ 1904 DTCI_DTCNumber_770 10;
BA_ "SignalType" SG_ 1904 DTCI_DTCNumber_770 "UNM";
BA_ "VNSigAllNodes" SG_ 1904 DTCI_DTCNumber_770 1;
BA_ "SignalLongName" SG_ 1904 DTCI_DTCFaultType_770 "Diagnostic Trouble Code Information Extended 770 : Diagnostic Trouble Code Fault Type";
BA_ "PacketOrder" SG_ 1904 DTCI_DTCFaultType_770 20;
BA_ "SignalType" SG_ 1904 DTCI_DTCFaultType_770 "ENM";
BA_ "VNSigAllNodes" SG_ 1904 DTCI_DTCFaultType_770 1;
BA_ "SignalLongName" SG_ 1904 DTCI_DTCFailType_770 "Diagnostic Trouble Code Information Extended 770 : Diagnostic Trouble Code Failure Type";
BA_ "PacketOrder" SG_ 1904 DTCI_DTCFailType_770 11;
BA_ "SignalType" SG_ 1904 DTCI_DTCFailType_770 "UNM";
BA_ "VNSigAllNodes" SG_ 1904 DTCI_DTCFailType_770 1;
BA_ "SignalLongName" SG_ 1904 DTCI_CurrentStatus_770 "Diagnostic Trouble Code Information Extended 770 : Current Status";
BA_ "PacketOrder" SG_ 1904 DTCI_CurrentStatus_770 18;
BA_ "SignalType" SG_ 1904 DTCI_CurrentStatus_770 "BLN";
BA_ "VNSigAllNodes" SG_ 1904 DTCI_CurrentStatus_770 1;
BA_ "SignalLongName" SG_ 1904 DTCI_CodeSupported_770 "Diagnostic Trouble Code Information Extended 770 : Code Supported";
BA_ "PacketOrder" SG_ 1904 DTCI_CodeSupported_770 19;
BA_ "SignalType" SG_ 1904 DTCI_CodeSupported_770 "BLN";
BA_ "VNSigAllNodes" SG_ 1904 DTCI_CodeSupported_770 1;
BA_ "SignalLongName" SG_ 1921 DTCI_CurrentStatus_781 "Diagnostic Trouble Code Information Extended 781: Current Status";
BA_ "PacketOrder" SG_ 1921 DTCI_CurrentStatus_781 18;
BA_ "SignalType" SG_ 1921 DTCI_CurrentStatus_781 "BLN";
BA_ "VNSigAllNodes" SG_ 1921 DTCI_CurrentStatus_781 1;
BA_ "SignalLongName" SG_ 1921 DTCI_WrnIndRqdSt_781 "Diagnostic Trouble Code Information Extended 781 : Warning Indicator Requested Status";
BA_ "PacketOrder" SG_ 1921 DTCI_WrnIndRqdSt_781 12;
BA_ "SignalType" SG_ 1921 DTCI_WrnIndRqdSt_781 "BLN";
BA_ "VNSigAllNodes" SG_ 1921 DTCI_WrnIndRqdSt_781 1;
BA_ "SignalLongName" SG_ 1921 DTCIUnused7_781 "Diagnostic Trouble Code Information Extended 781 : Unused 7";
BA_ "PacketOrder" SG_ 1921 DTCIUnused7_781 7;
BA_ "SignalType" SG_ 1921 DTCIUnused7_781 "BLN";
BA_ "VNSigAllNodes" SG_ 1921 DTCIUnused7_781 1;
BA_ "SignalLongName" SG_ 1921 DTCIUnused6_781 "Diagnostic Trouble Code Information Extended 781 : Unused 6";
BA_ "PacketOrder" SG_ 1921 DTCIUnused6_781 6;
BA_ "SignalType" SG_ 1921 DTCIUnused6_781 "BLN";
BA_ "VNSigAllNodes" SG_ 1921 DTCIUnused6_781 1;
BA_ "SignalLongName" SG_ 1921 DTCIUnused5_781 "Diagnostic Trouble Code Information Extended 781 : Unused 5";
BA_ "PacketOrder" SG_ 1921 DTCIUnused5_781 5;
BA_ "SignalType" SG_ 1921 DTCIUnused5_781 "BLN";
BA_ "VNSigAllNodes" SG_ 1921 DTCIUnused5_781 1;
BA_ "SignalLongName" SG_ 1921 DTCIUnused4_781 "Diagnostic Trouble Code Information Extended 781 : Unused 4";
BA_ "PacketOrder" SG_ 1921 DTCIUnused4_781 4;
BA_ "SignalType" SG_ 1921 DTCIUnused4_781 "BLN";
BA_ "VNSigAllNodes" SG_ 1921 DTCIUnused4_781 1;
BA_ "SignalLongName" SG_ 1921 DTCIUnused3_781 "Diagnostic Trouble Code Information Extended 781 : Unused 3";
BA_ "PacketOrder" SG_ 1921 DTCIUnused3_781 3;
BA_ "SignalType" SG_ 1921 DTCIUnused3_781 "BLN";
BA_ "VNSigAllNodes" SG_ 1921 DTCIUnused3_781 1;
BA_ "SignalLongName" SG_ 1921 DTCIUnused2_781 "Diagnostic Trouble Code Information Extended 781 : Unused 2";
BA_ "PacketOrder" SG_ 1921 DTCIUnused2_781 2;
BA_ "SignalType" SG_ 1921 DTCIUnused2_781 "BLN";
BA_ "VNSigAllNodes" SG_ 1921 DTCIUnused2_781 1;
BA_ "SignalLongName" SG_ 1921 DTCIUnused1_781 "Diagnostic Trouble Code Information Extended 781 : Unused 1";
BA_ "PacketOrder" SG_ 1921 DTCIUnused1_781 1;
BA_ "SignalType" SG_ 1921 DTCIUnused1_781 "BLN";
BA_ "VNSigAllNodes" SG_ 1921 DTCIUnused1_781 1;
BA_ "SignalLongName" SG_ 1921 DTCI_TstNPsdPwrUpSt_781 "Diagnostic Trouble Code Information Extended 781 : Test Not Passed Since Power Up Status";
BA_ "PacketOrder" SG_ 1921 DTCI_TstNPsdPwrUpSt_781 14;
BA_ "SignalType" SG_ 1921 DTCI_TstNPsdPwrUpSt_781 "BLN";
BA_ "VNSigAllNodes" SG_ 1921 DTCI_TstNPsdPwrUpSt_781 1;
BA_ "SignalLongName" SG_ 1921 DTCI_TstNPsdCdClrdSt_781 "Diagnostic Trouble Code Information Extended 781 : Test Not Passed Since Code Cleared Status";
BA_ "PacketOrder" SG_ 1921 DTCI_TstNPsdCdClrdSt_781 17;
BA_ "SignalType" SG_ 1921 DTCI_TstNPsdCdClrdSt_781 "BLN";
BA_ "VNSigAllNodes" SG_ 1921 DTCI_TstNPsdCdClrdSt_781 1;
BA_ "SignalLongName" SG_ 1921 DTCI_TstFldPwrUpSt_781 "Diagnostic Trouble Code Information Extended 781 : Test Failed Since Power Up Status";
BA_ "PacketOrder" SG_ 1921 DTCI_TstFldPwrUpSt_781 13;
BA_ "SignalType" SG_ 1921 DTCI_TstFldPwrUpSt_781 "BLN";
BA_ "VNSigAllNodes" SG_ 1921 DTCI_TstFldPwrUpSt_781 1;
BA_ "SignalLongName" SG_ 1921 DTCI_TstFldCdClrdStat_781 "Diagnostic Trouble Code Information Extended 781 : Test Failed Since Code Cleared Status";
BA_ "PacketOrder" SG_ 1921 DTCI_TstFldCdClrdStat_781 16;
BA_ "SignalType" SG_ 1921 DTCI_TstFldCdClrdStat_781 "BLN";
BA_ "VNSigAllNodes" SG_ 1921 DTCI_TstFldCdClrdStat_781 1;
BA_ "SignalLongName" SG_ 1921 DTCI_HistStat_781 "Diagnostic Trouble Code Information Extended 781 : History Status";
BA_ "PacketOrder" SG_ 1921 DTCI_HistStat_781 15;
BA_ "SignalType" SG_ 1921 DTCI_HistStat_781 "BLN";
BA_ "VNSigAllNodes" SG_ 1921 DTCI_HistStat_781 1;
BA_ "SignalLongName" SG_ 1921 DTCI_DTCTriggered_781 "Diagnostic Trouble Code Information Extended 781 : Diagnostic Trouble Code Triggered";
BA_ "PacketOrder" SG_ 1921 DTCI_DTCTriggered_781 8;
BA_ "SignalType" SG_ 1921 DTCI_DTCTriggered_781 "BLN";
BA_ "VNSigAllNodes" SG_ 1921 DTCI_DTCTriggered_781 1;
BA_ "SignalLongName" SG_ 1921 DTCI_DTCSource_781 "Diagnostic Trouble Code Information Extended 781 : Diagnostic Trouble Code Source";
BA_ "PacketOrder" SG_ 1921 DTCI_DTCSource_781 9;
BA_ "SignalType" SG_ 1921 DTCI_DTCSource_781 "UNM";
BA_ "VNSigAllNodes" SG_ 1921 DTCI_DTCSource_781 1;
BA_ "SignalLongName" SG_ 1921 DTCI_DTCNumber_781 "Diagnostic Trouble Code Information Extended 781 : Diagnostic Trouble Code Number";
BA_ "PacketOrder" SG_ 1921 DTCI_DTCNumber_781 10;
BA_ "SignalType" SG_ 1921 DTCI_DTCNumber_781 "UNM";
BA_ "VNSigAllNodes" SG_ 1921 DTCI_DTCNumber_781 1;
BA_ "SignalLongName" SG_ 1921 DTCI_DTCFaultType_781 "Diagnostic Trouble Code Information Extended 781 : Diagnostic Trouble Code Fault Type";
BA_ "PacketOrder" SG_ 1921 DTCI_DTCFaultType_781 20;
BA_ "SignalType" SG_ 1921 DTCI_DTCFaultType_781 "ENM";
BA_ "VNSigAllNodes" SG_ 1921 DTCI_DTCFaultType_781 1;
BA_ "SignalLongName" SG_ 1921 DTCI_DTCFailType_781 "Diagnostic Trouble Code Information Extended 781 : Diagnostic Trouble Code Failure Type";
BA_ "PacketOrder" SG_ 1921 DTCI_DTCFailType_781 11;
BA_ "SignalType" SG_ 1921 DTCI_DTCFailType_781 "UNM";
BA_ "VNSigAllNodes" SG_ 1921 DTCI_DTCFailType_781 1;
BA_ "SignalLongName" SG_ 1921 DTCI_CodeSupported_781 "Diagnostic Trouble Code Information Extended 781 : Code Supported";
BA_ "PacketOrder" SG_ 1921 DTCI_CodeSupported_781 19;
BA_ "SignalType" SG_ 1921 DTCI_CodeSupported_781 "BLN";
BA_ "VNSigAllNodes" SG_ 1921 DTCI_CodeSupported_781 1;
BA_ "SignalLongName" SG_ 1912 DTCI_DTCFaultType_778 "Diagnostic Trouble Code Information Extended 778 : Diagnostic Trouble Code Fault Type";
BA_ "PacketOrder" SG_ 1912 DTCI_DTCFaultType_778 20;
BA_ "SignalType" SG_ 1912 DTCI_DTCFaultType_778 "ENM";
BA_ "VNSigAllNodes" SG_ 1912 DTCI_DTCFaultType_778 1;
BA_ "SignalLongName" SG_ 1912 DTCI_CodeSupported_778 "Diagnostic Trouble Code Information Extended 778 : Code Supported";
BA_ "PacketOrder" SG_ 1912 DTCI_CodeSupported_778 19;
BA_ "SignalType" SG_ 1912 DTCI_CodeSupported_778 "BLN";
BA_ "VNSigAllNodes" SG_ 1912 DTCI_CodeSupported_778 1;
BA_ "SignalLongName" SG_ 1912 DTCI_CurrentStatus_778 "Diagnostic Trouble Code Information Extended 778 : Current Status";
BA_ "PacketOrder" SG_ 1912 DTCI_CurrentStatus_778 18;
BA_ "SignalType" SG_ 1912 DTCI_CurrentStatus_778 "BLN";
BA_ "VNSigAllNodes" SG_ 1912 DTCI_CurrentStatus_778 1;
BA_ "SignalLongName" SG_ 1912 DTCI_TstNPsdCdClrdSt_778 "Diagnostic Trouble Code Information Extended 778 : Test Not Passed Since Code Cleared Status";
BA_ "PacketOrder" SG_ 1912 DTCI_TstNPsdCdClrdSt_778 17;
BA_ "SignalType" SG_ 1912 DTCI_TstNPsdCdClrdSt_778 "BLN";
BA_ "VNSigAllNodes" SG_ 1912 DTCI_TstNPsdCdClrdSt_778 1;
BA_ "SignalLongName" SG_ 1912 DTCI_TstFldCdClrdStat_778 "Diagnostic Trouble Code Information Extended 778 : Test Failed Since Code Cleared Status";
BA_ "PacketOrder" SG_ 1912 DTCI_TstFldCdClrdStat_778 16;
BA_ "SignalType" SG_ 1912 DTCI_TstFldCdClrdStat_778 "BLN";
BA_ "VNSigAllNodes" SG_ 1912 DTCI_TstFldCdClrdStat_778 1;
BA_ "SignalLongName" SG_ 1912 DTCI_HistStat_778 "Diagnostic Trouble Code Information Extended 778 : History Status";
BA_ "PacketOrder" SG_ 1912 DTCI_HistStat_778 15;
BA_ "SignalType" SG_ 1912 DTCI_HistStat_778 "BLN";
BA_ "VNSigAllNodes" SG_ 1912 DTCI_HistStat_778 1;
BA_ "SignalLongName" SG_ 1912 DTCI_TstNPsdPwrUpSt_778 "Diagnostic Trouble Code Information Extended 778 : Test Not Passed Since Power Up Status";
BA_ "PacketOrder" SG_ 1912 DTCI_TstNPsdPwrUpSt_778 14;
BA_ "SignalType" SG_ 1912 DTCI_TstNPsdPwrUpSt_778 "BLN";
BA_ "VNSigAllNodes" SG_ 1912 DTCI_TstNPsdPwrUpSt_778 1;
BA_ "SignalLongName" SG_ 1912 DTCI_TstFldPwrUpSt_778 "Diagnostic Trouble Code Information Extended 778 : Test Failed Since Power Up Status";
BA_ "PacketOrder" SG_ 1912 DTCI_TstFldPwrUpSt_778 13;
BA_ "SignalType" SG_ 1912 DTCI_TstFldPwrUpSt_778 "BLN";
BA_ "VNSigAllNodes" SG_ 1912 DTCI_TstFldPwrUpSt_778 1;
BA_ "SignalLongName" SG_ 1912 DTCI_WrnIndRqdSt_778 "Diagnostic Trouble Code Information Extended 778 : Warning Indicator Requested Status";
BA_ "PacketOrder" SG_ 1912 DTCI_WrnIndRqdSt_778 12;
BA_ "SignalType" SG_ 1912 DTCI_WrnIndRqdSt_778 "BLN";
BA_ "VNSigAllNodes" SG_ 1912 DTCI_WrnIndRqdSt_778 1;
BA_ "SignalLongName" SG_ 1912 DTCI_DTCFailType_778 "Diagnostic Trouble Code Information Extended 778 : Diagnostic Trouble Code Failure Type";
BA_ "PacketOrder" SG_ 1912 DTCI_DTCFailType_778 11;
BA_ "SignalType" SG_ 1912 DTCI_DTCFailType_778 "UNM";
BA_ "VNSigAllNodes" SG_ 1912 DTCI_DTCFailType_778 1;
BA_ "SignalLongName" SG_ 1912 DTCI_DTCNumber_778 "Diagnostic Trouble Code Information Extended 778 : Diagnostic Trouble Code Number";
BA_ "PacketOrder" SG_ 1912 DTCI_DTCNumber_778 10;
BA_ "SignalType" SG_ 1912 DTCI_DTCNumber_778 "UNM";
BA_ "VNSigAllNodes" SG_ 1912 DTCI_DTCNumber_778 1;
BA_ "SignalLongName" SG_ 1912 DTCI_DTCSource_778 "Diagnostic Trouble Code Information Extended 778 : Diagnostic Trouble Code Source";
BA_ "PacketOrder" SG_ 1912 DTCI_DTCSource_778 9;
BA_ "SignalType" SG_ 1912 DTCI_DTCSource_778 "UNM";
BA_ "VNSigAllNodes" SG_ 1912 DTCI_DTCSource_778 1;
BA_ "SignalLongName" SG_ 1912 DTCI_DTCTriggered_778 "Diagnostic Trouble Code Information Extended 778 : Diagnostic Trouble Code Triggered";
BA_ "PacketOrder" SG_ 1912 DTCI_DTCTriggered_778 8;
BA_ "SignalType" SG_ 1912 DTCI_DTCTriggered_778 "BLN";
BA_ "VNSigAllNodes" SG_ 1912 DTCI_DTCTriggered_778 1;
BA_ "SignalLongName" SG_ 1912 DTCIUnused7_778 "Diagnostic Trouble Code Information Extended 778 : Unused 7";
BA_ "PacketOrder" SG_ 1912 DTCIUnused7_778 7;
BA_ "SignalType" SG_ 1912 DTCIUnused7_778 "BLN";
BA_ "VNSigAllNodes" SG_ 1912 DTCIUnused7_778 1;
BA_ "SignalLongName" SG_ 1912 DTCIUnused6_778 "Diagnostic Trouble Code Information Extended 778 : Unused 6";
BA_ "PacketOrder" SG_ 1912 DTCIUnused6_778 6;
BA_ "SignalType" SG_ 1912 DTCIUnused6_778 "BLN";
BA_ "VNSigAllNodes" SG_ 1912 DTCIUnused6_778 1;
BA_ "SignalLongName" SG_ 1912 DTCIUnused5_778 "Diagnostic Trouble Code Information Extended 778 : Unused 5";
BA_ "PacketOrder" SG_ 1912 DTCIUnused5_778 5;
BA_ "SignalType" SG_ 1912 DTCIUnused5_778 "BLN";
BA_ "VNSigAllNodes" SG_ 1912 DTCIUnused5_778 1;
BA_ "SignalLongName" SG_ 1912 DTCIUnused4_778 "Diagnostic Trouble Code Information Extended 778 : Unused 4";
BA_ "PacketOrder" SG_ 1912 DTCIUnused4_778 4;
BA_ "SignalType" SG_ 1912 DTCIUnused4_778 "BLN";
BA_ "VNSigAllNodes" SG_ 1912 DTCIUnused4_778 1;
BA_ "SignalLongName" SG_ 1912 DTCIUnused3_778 "Diagnostic Trouble Code Information Extended 778 : Unused 3";
BA_ "PacketOrder" SG_ 1912 DTCIUnused3_778 3;
BA_ "SignalType" SG_ 1912 DTCIUnused3_778 "BLN";
BA_ "VNSigAllNodes" SG_ 1912 DTCIUnused3_778 1;
BA_ "SignalLongName" SG_ 1912 DTCIUnused2_778 "Diagnostic Trouble Code Information Extended 778 : Unused 2";
BA_ "PacketOrder" SG_ 1912 DTCIUnused2_778 2;
BA_ "SignalType" SG_ 1912 DTCIUnused2_778 "BLN";
BA_ "VNSigAllNodes" SG_ 1912 DTCIUnused2_778 1;
BA_ "SignalLongName" SG_ 1912 DTCIUnused1_778 "Diagnostic Trouble Code Information Extended 778 : Unused 1";
BA_ "PacketOrder" SG_ 1912 DTCIUnused1_778 1;
BA_ "SignalType" SG_ 1912 DTCIUnused1_778 "BLN";
BA_ "VNSigAllNodes" SG_ 1912 DTCIUnused1_778 1;
BA_ "SignalLongName" SG_ 1610 DgnInf "Diagnostic Information";
BA_ "SignalType" SG_ 1610 DgnInf "UNM";
BA_ "VNSigAllNodes" SG_ 1610 DgnInf 1;
BA_ "VNSigSLHSSharedDiagnostic" SG_ 1610 DgnInf 1;
BA_ "SignalLongName" SG_ 1363 DgnInf_HS553 "Diagnostic Information HS553";
BA_ "SignalType" SG_ 1363 DgnInf_HS553 "UNM";
BA_ "VNSigAllNodes" SG_ 1363 DgnInf_HS553 1;
BA_ "VNSigSLHSSharedDiagnostic" SG_ 1363 DgnInf_HS553 1;
BA_ "SignalLongName" SG_ 1631 DgnInf "Diagnostic Information";
BA_ "SignalType" SG_ 1631 DgnInf "UNM";
BA_ "VNSigAllNodes" SG_ 1631 DgnInf 1;
BA_ "VNSigSLHSSharedDiagnostic" SG_ 1631 DgnInf 1;
BA_ "SignalLongName" SG_ 1375 DgnInf_HS55F "Diagnostic Information HS55F";
BA_ "SignalType" SG_ 1375 DgnInf_HS55F "UNM";
BA_ "VNSigAllNodes" SG_ 1375 DgnInf_HS55F 1;
BA_ "VNSigSLHSSharedDiagnostic" SG_ 1375 DgnInf_HS55F 1;
BA_ "SignalLongName" SG_ 1372 DgnInf_HS55C "Diagnostic Information HS55C";
BA_ "SignalType" SG_ 1372 DgnInf_HS55C "UNM";
BA_ "VNSigAllNodes" SG_ 1372 DgnInf_HS55C 1;
BA_ "VNSigSLHSSharedDiagnostic" SG_ 1372 DgnInf_HS55C 1;
BA_ "SignalLongName" SG_ 1362 DgnInf_HS552 "Diagnostic Information HS552";
BA_ "SignalType" SG_ 1362 DgnInf_HS552 "UNM";
BA_ "VNSigAllNodes" SG_ 1362 DgnInf_HS552 1;
BA_ "VNSigSLHSSharedDiagnostic" SG_ 1362 DgnInf_HS552 1;
BA_ "SignalLongName" SG_ 1628 DgnInf "Diagnostic Information";
BA_ "SignalType" SG_ 1628 DgnInf "UNM";
BA_ "VNSigAllNodes" SG_ 1628 DgnInf 1;
BA_ "VNSigSLHSSharedDiagnostic" SG_ 1628 DgnInf 1;
BA_ "SignalLongName" SG_ 1619 DgnInf "Diagnostic Information";
BA_ "SignalType" SG_ 1619 DgnInf "UNM";
BA_ "VNSigAllNodes" SG_ 1619 DgnInf 1;
BA_ "VNSigSLHSSharedDiagnostic" SG_ 1619 DgnInf 1;
BA_ "SignalLongName" SG_ 1618 DgnInf "Diagnostic Information";
BA_ "SignalType" SG_ 1618 DgnInf "UNM";
BA_ "VNSigAllNodes" SG_ 1618 DgnInf 1;
BA_ "VNSigSLHSSharedDiagnostic" SG_ 1618 DgnInf 1;
BA_ "SignalLongName" SG_ 1357 DgnInf_HS54D "Diagnostic Information HS54D";
BA_ "SignalType" SG_ 1357 DgnInf_HS54D "UNM";
BA_ "VNSigAllNodes" SG_ 1357 DgnInf_HS54D 1;
BA_ "VNSigSLHSSharedDiagnostic" SG_ 1357 DgnInf_HS54D 1;
BA_ "SignalLongName" SG_ 1613 DgnInf "Diagnostic Information";
BA_ "SignalType" SG_ 1613 DgnInf "UNM";
BA_ "VNSigAllNodes" SG_ 1613 DgnInf 1;
BA_ "VNSigSLHSSharedDiagnostic" SG_ 1613 DgnInf 1;
BA_ "SignalLongName" SG_ 1606 DgnInf "Diagnostic Information";
BA_ "SignalType" SG_ 1606 DgnInf "UNM";
BA_ "VNSigAllNodes" SG_ 1606 DgnInf 1;
BA_ "VNSigSLHSSharedDiagnostic" SG_ 1606 DgnInf 1;
BA_ "SignalLongName" SG_ 1356 DgnInf_HS54C "Diagnostic Information HS54C";
BA_ "SignalType" SG_ 1356 DgnInf_HS54C "UNM";
BA_ "VNSigAllNodes" SG_ 1356 DgnInf_HS54C 1;
BA_ "VNSigSLHSSharedDiagnostic" SG_ 1356 DgnInf_HS54C 1;
BA_ "SignalLongName" SG_ 1350 DgnInf_HS546 "Diagnostic Information HS546";
BA_ "SignalType" SG_ 1350 DgnInf_HS546 "UNM";
BA_ "VNSigAllNodes" SG_ 1350 DgnInf_HS546 1;
BA_ "VNSigSLHSSharedDiagnostic" SG_ 1350 DgnInf_HS546 1;
BA_ "SignalLongName" SG_ 2029 DgnInf "Diagnostic Information";
BA_ "SignalType" SG_ 2029 DgnInf "UNM";
BA_ "VNSigAllNodes" SG_ 2029 DgnInf 1;
BA_ "VNSigSLHSSharedDiagnostic" SG_ 2029 DgnInf 1;
BA_ "SignalLongName" SG_ 1517 DgnInf "Diagnostic Information";
BA_ "SignalType" SG_ 1517 DgnInf "UNM";
BA_ "VNSigAllNodes" SG_ 1517 DgnInf 1;
BA_ "VNSigSLHSSharedDiagnostic" SG_ 1517 DgnInf 1;
BA_ "SignalLongName" SG_ 1346 DgnInf_HS542 "Diagnostic Information HS542";
BA_ "SignalType" SG_ 1346 DgnInf_HS542 "UNM";
BA_ "VNSigAllNodes" SG_ 1346 DgnInf_HS542 1;
BA_ "VNSigSLHSSharedDiagnostic" SG_ 1346 DgnInf_HS542 1;
BA_ "SignalLongName" SG_ 1602 DgnInf "Diagnostic Information";
BA_ "SignalType" SG_ 1602 DgnInf "UNM";
BA_ "VNSigAllNodes" SG_ 1602 DgnInf 1;
BA_ "VNSigSLHSSharedDiagnostic" SG_ 1602 DgnInf 1;
BA_ "SignalLongName" SG_ 2027 DgnInf "Diagnostic Information";
BA_ "SignalType" SG_ 2027 DgnInf "UNM";
BA_ "VNSigAllNodes" SG_ 2027 DgnInf 1;
BA_ "VNSigSLHSSharedDiagnostic" SG_ 2027 DgnInf 1;
BA_ "SignalLongName" SG_ 1515 DgnInf "Diagnostic Information";
BA_ "SignalType" SG_ 1515 DgnInf "UNM";
BA_ "VNSigAllNodes" SG_ 1515 DgnInf 1;
BA_ "VNSigSLHSSharedDiagnostic" SG_ 1515 DgnInf 1;
BA_ "SignalLongName" SG_ 1354 DgnInf_HS54A "Diagnostic Information HS54A";
BA_ "SignalType" SG_ 1354 DgnInf_HS54A "UNM";
BA_ "VNSigAllNodes" SG_ 1354 DgnInf_HS54A 1;
BA_ "VNSigSLHSSharedDiagnostic" SG_ 1354 DgnInf_HS54A 1;
BA_ "SignalLongName" SG_ 1612 DgnInf "Diagnostic Information";
BA_ "SignalType" SG_ 1612 DgnInf "UNM";
BA_ "VNSigAllNodes" SG_ 1612 DgnInf 1;
BA_ "VNSigSLHSSharedDiagnostic" SG_ 1612 DgnInf 1;
BA_ "SignalLongName" SG_ 607 DgnInf "Diagnostic Information";
BA_ "SignalType" SG_ 607 DgnInf "UNM";
BA_ "VNSigAllNodes" SG_ 607 DgnInf 1;
BA_ "VNSigSLHSSharedDiagnostic" SG_ 607 DgnInf 1;
BA_ "SignalLongName" SG_ 606 DgnInf "Diagnostic Information";
BA_ "SignalType" SG_ 606 DgnInf "UNM";
BA_ "VNSigAllNodes" SG_ 606 DgnInf 1;
BA_ "VNSigSLHSSharedDiagnostic" SG_ 606 DgnInf 1;
BA_ "SignalLongName" SG_ 605 DgnInf "Diagnostic Information";
BA_ "SignalType" SG_ 605 DgnInf "UNM";
BA_ "VNSigAllNodes" SG_ 605 DgnInf 1;
BA_ "VNSigSLHSSharedDiagnostic" SG_ 605 DgnInf 1;
BA_ "SignalLongName" SG_ 604 DgnInf "Diagnostic Information";
BA_ "SignalType" SG_ 604 DgnInf "UNM";
BA_ "VNSigAllNodes" SG_ 604 DgnInf 1;
BA_ "VNSigSLHSSharedDiagnostic" SG_ 604 DgnInf 1;
BA_ "SignalLongName" SG_ 602 DgnInf "Diagnostic Information";
BA_ "SignalType" SG_ 602 DgnInf "UNM";
BA_ "VNSigAllNodes" SG_ 602 DgnInf 1;
BA_ "VNSigSLHSSharedDiagnostic" SG_ 602 DgnInf 1;
BA_ "SignalLongName" SG_ 600 DgnInf "Diagnostic Information";
BA_ "SignalType" SG_ 600 DgnInf "UNM";
BA_ "VNSigAllNodes" SG_ 600 DgnInf 1;
BA_ "VNSigSLHSSharedDiagnostic" SG_ 600 DgnInf 1;
BA_ "SignalLongName" SG_ 595 DgnInf "Diagnostic Information";
BA_ "SignalType" SG_ 595 DgnInf "UNM";
BA_ "VNSigAllNodes" SG_ 595 DgnInf 1;
BA_ "VNSigSLHSSharedDiagnostic" SG_ 595 DgnInf 1;
BA_ "SignalLongName" SG_ 1034 CRL_Cnfdnc "Curvature Right Line : Confidence";
BA_ "PacketOrder" SG_ 1034 CRL_Cnfdnc 4;
BA_ "SignalType" SG_ 1034 CRL_Cnfdnc "ENM";
BA_ "VNSigAllNodes" SG_ 1034 CRL_Cnfdnc 1;
BA_ "SignalLongName" SG_ 1034 CRL_ViewRng "Curvature Right Line : View Range";
BA_ "PacketOrder" SG_ 1034 CRL_ViewRng 3;
BA_ "SignalType" SG_ 1034 CRL_ViewRng "UNM";
BA_ "VNSigAllNodes" SG_ 1034 CRL_ViewRng 1;
BA_ "SignalLongName" SG_ 1034 CRL_CoefdA "Curvature Right Line : Coefficient dA";
BA_ "PacketOrder" SG_ 1034 CRL_CoefdA 2;
BA_ "SignalType" SG_ 1034 CRL_CoefdA "SNM";
BA_ "VNSigAllNodes" SG_ 1034 CRL_CoefdA 1;
BA_ "SignalLongName" SG_ 1034 CRL_CoefA "Curvature Right Line : Coefficient A";
BA_ "PacketOrder" SG_ 1034 CRL_CoefA 1;
BA_ "SignalType" SG_ 1034 CRL_CoefA "SNM";
BA_ "VNSigAllNodes" SG_ 1034 CRL_CoefA 1;
BA_ "SignalLongName" SG_ 1033 CLL_Cnfdnc "Curvature Left Line : Confidence";
BA_ "PacketOrder" SG_ 1033 CLL_Cnfdnc 4;
BA_ "SignalType" SG_ 1033 CLL_Cnfdnc "ENM";
BA_ "VNSigAllNodes" SG_ 1033 CLL_Cnfdnc 1;
BA_ "SignalLongName" SG_ 1033 CLL_ViewRng "Curvature Left Line : View Range";
BA_ "PacketOrder" SG_ 1033 CLL_ViewRng 3;
BA_ "SignalType" SG_ 1033 CLL_ViewRng "UNM";
BA_ "VNSigAllNodes" SG_ 1033 CLL_ViewRng 1;
BA_ "SignalLongName" SG_ 1033 CLL_CoefdA "Curvature Left Line : Coefficient dA";
BA_ "PacketOrder" SG_ 1033 CLL_CoefdA 2;
BA_ "SignalType" SG_ 1033 CLL_CoefdA "SNM";
BA_ "VNSigAllNodes" SG_ 1033 CLL_CoefdA 1;
BA_ "SignalLongName" SG_ 1033 CLL_CoefA "Curvature Left Line : Coefficient A";
BA_ "PacketOrder" SG_ 1033 CLL_CoefA 1;
BA_ "SignalType" SG_ 1033 CLL_CoefA "SNM";
BA_ "VNSigAllNodes" SG_ 1033 CLL_CoefA 1;
BA_ "SignalLongName" SG_ 800 FCACtrlBrkSysCmdPrtVl "Forward Collision Alert Control Brake System Command Protection Value";
BA_ "SignalType" SG_ 800 FCACtrlBrkSysCmdPrtVl "UNM";
BA_ "VNSigAllNodes" SG_ 800 FCACtrlBrkSysCmdPrtVl 1;
BA_ "GenSigDeltaValue" SG_ 800 FCACtrlBrkSysCmdPrtVl 1;
BA_ "GenSigSendType" SG_ 800 FCACtrlBrkSysCmdPrtVl 12;
BA_ "SignalLongName" SG_ 800 FCACBSC_CtrlAcc "Forward Collision Alert Control Brake System Command : Control Acceleration";
BA_ "PacketOrder" SG_ 800 FCACBSC_CtrlAcc 4;
BA_ "SignalType" SG_ 800 FCACBSC_CtrlAcc "SNM";
BA_ "VNSigAllNodes" SG_ 800 FCACBSC_CtrlAcc 1;
BA_ "GenSigDeltaValue" SG_ 800 FCACBSC_CtrlAcc 1;
BA_ "GenSigSendType" SG_ 800 FCACBSC_CtrlAcc 12;
BA_ "SignalLongName" SG_ 800 FCACBSC_AutBrkRpRt "Forward Collision Alert Control Brake System Command : Automatic Braking Ramp Rate";
BA_ "PacketOrder" SG_ 800 FCACBSC_AutBrkRpRt 3;
BA_ "SignalType" SG_ 800 FCACBSC_AutBrkRpRt "ENM";
BA_ "VNSigAllNodes" SG_ 800 FCACBSC_AutBrkRpRt 1;
BA_ "GenSigSendType" SG_ 800 FCACBSC_AutBrkRpRt 10;
BA_ "SignalLongName" SG_ 800 FCACBSC_AutBrkRqTp "Forward Collision Alert Control Brake System Command : Signal1880";
BA_ "PacketOrder" SG_ 800 FCACBSC_AutBrkRqTp 2;
BA_ "SignalType" SG_ 800 FCACBSC_AutBrkRqTp "ENM";
BA_ "VNSigAllNodes" SG_ 800 FCACBSC_AutBrkRqTp 1;
BA_ "GenSigSendType" SG_ 800 FCACBSC_AutBrkRqTp 10;
BA_ "SignalLongName" SG_ 800 FCACBSC_AutBrkRqd "Forward Collision Alert Control Brake System Command : Signal1879";
BA_ "PacketOrder" SG_ 800 FCACBSC_AutBrkRqd 1;
BA_ "SignalType" SG_ 800 FCACBSC_AutBrkRqd "BLN";
BA_ "VNSigAllNodes" SG_ 800 FCACBSC_AutBrkRqd 1;
BA_ "GenSigSendType" SG_ 800 FCACBSC_AutBrkRqd 10;
BA_ "SignalLongName" SG_ 800 FCACtrlBrkSysCmdRC "Forward Collision Alert Control Brake System Command Rolling Count";
BA_ "SignalType" SG_ 800 FCACtrlBrkSysCmdRC "UNM";
BA_ "VNSigAllNodes" SG_ 800 FCACtrlBrkSysCmdRC 1;
BA_ "GenSigDeltaValue" SG_ 800 FCACtrlBrkSysCmdRC 1;
BA_ "GenSigSendType" SG_ 800 FCACtrlBrkSysCmdRC 12;
BA_ "SignalLongName" SG_ 554 PrtdEPBSwStatPortVal "Protected Electric Park Brake Switch Status Protection Value";
BA_ "SignalType" SG_ 554 PrtdEPBSwStatPortVal "UNM";
BA_ "VNSigAllNodes" SG_ 554 PrtdEPBSwStatPortVal 1;
BA_ "SignalLongName" SG_ 554 PrtdEPBSwStatARC "Protected Electric Park Brake Switch Status Alive Rolling Count";
BA_ "SignalType" SG_ 554 PrtdEPBSwStatARC "UNM";
BA_ "VNSigAllNodes" SG_ 554 PrtdEPBSwStatARC 1;
BA_ "SignalLongName" SG_ 554 PrtdEPBSwStat "Protected Electric Park Brake Switch Status";
BA_ "SignalType" SG_ 554 PrtdEPBSwStat "ENM";
BA_ "VNSigAllNodes" SG_ 554 PrtdEPBSwStat 1;
BA_ "SignalLongName" SG_ 554 ElecPrkBrkApplStatPV "Electric Park Brake Application Status Protection Value";
BA_ "SignalType" SG_ 554 ElecPrkBrkApplStatPV "UNM";
BA_ "VNSigAllNodes" SG_ 554 ElecPrkBrkApplStatPV 1;
BA_ "SignalLongName" SG_ 554 ElecPrkBrkAvailStatPV "Electric Park Brake Availability Status Protection Value";
BA_ "SignalType" SG_ 554 ElecPrkBrkAvailStatPV "UNM";
BA_ "VNSigAllNodes" SG_ 554 ElecPrkBrkAvailStatPV 1;
BA_ "SignalLongName" SG_ 554 ElecPrkBrkAvailStat "Electric Park Brake Availability Status";
BA_ "SignalType" SG_ 554 ElecPrkBrkAvailStat "ENM";
BA_ "VNSigAllNodes" SG_ 554 ElecPrkBrkAvailStat 1;
BA_ "SignalLongName" SG_ 554 ElecPrkBrkStatRC "Electric Park Brake Status Rolling Count";
BA_ "SignalType" SG_ 554 ElecPrkBrkStatRC "UNM";
BA_ "VNSigAllNodes" SG_ 554 ElecPrkBrkStatRC 1;
BA_ "SignalLongName" SG_ 554 ElecPrkBrkApplStat "Electric Park Brake Application Status";
BA_ "SignalType" SG_ 554 ElecPrkBrkApplStat "ENM";
BA_ "VNSigAllNodes" SG_ 554 ElecPrkBrkApplStat 1;
BA_ "SignalLongName" SG_ 464 FrtAxlOpeMod "Front Axle Operational Mode";
BA_ "SignalType" SG_ 464 FrtAxlOpeMod "ENM";
BA_ "VNSigAllNodes" SG_ 464 FrtAxlOpeMod 1;
BA_ "SignalLongName" SG_ 465 RrAxlOpeMod "Rear Axle Operational Mode";
BA_ "SignalType" SG_ 465 RrAxlOpeMod "ENM";
BA_ "VNSigAllNodes" SG_ 465 RrAxlOpeMod 1;
BA_ "SignalLongName" SG_ 465 RrAxlEstTrqV "Rear Axle Estimated Torque Validity";
BA_ "SignalType" SG_ 465 RrAxlEstTrqV "ENM";
BA_ "VNSigAllNodes" SG_ 465 RrAxlEstTrqV 1;
BA_ "SignalLongName" SG_ 465 RrAxlEstTrq "Rear Axle Estimated Torque";
BA_ "SignalType" SG_ 465 RrAxlEstTrq "SNM";
BA_ "VNSigAllNodes" SG_ 465 RrAxlEstTrq 1;
BA_ "SignalLongName" SG_ 465 RrAxlStat "Rear Axle Status";
BA_ "SignalType" SG_ 465 RrAxlStat "ENM";
BA_ "VNSigAllNodes" SG_ 465 RrAxlStat 1;
BA_ "SignalLongName" SG_ 465 RrAxlCtrlMod "Rear Axle Control Mode";
BA_ "SignalType" SG_ 465 RrAxlCtrlMod "ENM";
BA_ "VNSigAllNodes" SG_ 465 RrAxlCtrlMod 1;
BA_ "SignalLongName" SG_ 465 RAMDVLReqVal "Rear Axle Maximum Differential Velocity Limit : Request Value";
BA_ "PacketOrder" SG_ 465 RAMDVLReqVal 2;
BA_ "SignalType" SG_ 465 RAMDVLReqVal "UNM";
BA_ "VNSigAllNodes" SG_ 465 RAMDVLReqVal 1;
BA_ "SignalLongName" SG_ 465 RAMDVLAtv "Rear Axle Maximum Differential Velocity Limit : Active";
BA_ "PacketOrder" SG_ 465 RAMDVLAtv 1;
BA_ "SignalType" SG_ 465 RAMDVLAtv "BLN";
BA_ "VNSigAllNodes" SG_ 465 RAMDVLAtv 1;
BA_ "SignalLongName" SG_ 801 WhlBdySnsHmPosLrnd "Wheel to Body Sensors Home Position Learned";
BA_ "SignalType" SG_ 801 WhlBdySnsHmPosLrnd "BLN";
BA_ "VNSigAllNodes" SG_ 801 WhlBdySnsHmPosLrnd 1;
BA_ "SignalLongName" SG_ 801 WBRP_ARC "Wheel to Body Relative Position : Alive Rolling Count";
BA_ "PacketOrder" SG_ 801 WBRP_ARC 2;
BA_ "SignalType" SG_ 801 WBRP_ARC "UNM";
BA_ "VNSigAllNodes" SG_ 801 WBRP_ARC 1;
BA_ "SignalLongName" SG_ 801 WBRP_Tmestmp "Wheel to Body Relative Position : Timestamp";
BA_ "PacketOrder" SG_ 801 WBRP_Tmestmp 1;
BA_ "SignalType" SG_ 801 WBRP_Tmestmp "UNM";
BA_ "VNSigAllNodes" SG_ 801 WBRP_Tmestmp 1;
BA_ "SignalLongName" SG_ 801 WBRP_RtFrtV "Wheel to Body Relative Position : Right Front Validity";
BA_ "PacketOrder" SG_ 801 WBRP_RtFrtV 5;
BA_ "SignalType" SG_ 801 WBRP_RtFrtV "ENM";
BA_ "VNSigAllNodes" SG_ 801 WBRP_RtFrtV 1;
BA_ "SignalLongName" SG_ 801 WBRP_RtFrt "Wheel to Body Relative Position : Right Front";
BA_ "PacketOrder" SG_ 801 WBRP_RtFrt 8;
BA_ "SignalType" SG_ 801 WBRP_RtFrt "SNM";
BA_ "VNSigAllNodes" SG_ 801 WBRP_RtFrt 1;
BA_ "SignalLongName" SG_ 801 WBRP_RtRrV "Wheel to Body Relative Position : Right Rear Validity";
BA_ "PacketOrder" SG_ 801 WBRP_RtRrV 6;
BA_ "SignalType" SG_ 801 WBRP_RtRrV "ENM";
BA_ "VNSigAllNodes" SG_ 801 WBRP_RtRrV 1;
BA_ "SignalLongName" SG_ 801 WBRP_RtRr "Wheel to Body Relative Position : Right Rear";
BA_ "PacketOrder" SG_ 801 WBRP_RtRr 10;
BA_ "SignalType" SG_ 801 WBRP_RtRr "SNM";
BA_ "VNSigAllNodes" SG_ 801 WBRP_RtRr 1;
BA_ "SignalLongName" SG_ 801 WBRP_LftRrV "Wheel to Body Relative Position : Left Rear Validity";
BA_ "PacketOrder" SG_ 801 WBRP_LftRrV 4;
BA_ "SignalType" SG_ 801 WBRP_LftRrV "ENM";
BA_ "VNSigAllNodes" SG_ 801 WBRP_LftRrV 1;
BA_ "SignalLongName" SG_ 801 WBRP_LftRr "Wheel to Body Relative Position : Left Rear";
BA_ "PacketOrder" SG_ 801 WBRP_LftRr 9;
BA_ "SignalType" SG_ 801 WBRP_LftRr "SNM";
BA_ "VNSigAllNodes" SG_ 801 WBRP_LftRr 1;
BA_ "SignalLongName" SG_ 801 WBRP_LftFrtV "Wheel to Body Relative Position : Left Front Validity";
BA_ "PacketOrder" SG_ 801 WBRP_LftFrtV 3;
BA_ "SignalType" SG_ 801 WBRP_LftFrtV "ENM";
BA_ "VNSigAllNodes" SG_ 801 WBRP_LftFrtV 1;
BA_ "SignalLongName" SG_ 801 WBRP_LftFrt "Wheel to Body Relative Position : Left Front";
BA_ "PacketOrder" SG_ 801 WBRP_LftFrt 7;
BA_ "SignalType" SG_ 801 WBRP_LftFrt "SNM";
BA_ "VNSigAllNodes" SG_ 801 WBRP_LftFrt 1;
BA_ "SignalLongName" SG_ 579 DgnInf "Diagnostic Information";
BA_ "SignalType" SG_ 579 DgnInf "UNM";
BA_ "VNSigAllNodes" SG_ 579 DgnInf 1;
BA_ "VNSigSLHSSharedDiagnostic" SG_ 579 DgnInf 1;
BA_ "SignalLongName" SG_ 844 IMUProtYawRtM "Inertial Measurement Unit Protected Yaw Rate Mask";
BA_ "SignalType" SG_ 844 IMUProtYawRtM "ENM";
BA_ "VNSigAllNodes" SG_ 844 IMUProtYawRtM 1;
BA_ "SignalLongName" SG_ 844 IMUProtYawRt "Inertial Measurement Unit Protected Yaw Rate";
BA_ "SignalType" SG_ 844 IMUProtYawRt "SNM";
BA_ "VNSigAllNodes" SG_ 844 IMUProtYawRt 1;
BA_ "SignalLongName" SG_ 844 IMUProtLonAccM "Inertial Measurement Unit Protected Longitudinal Acceleration Mask";
BA_ "SignalType" SG_ 844 IMUProtLonAccM "ENM";
BA_ "VNSigAllNodes" SG_ 844 IMUProtLonAccM 1;
BA_ "SignalLongName" SG_ 844 IMUProtLonAcc "Inertial Measurement Unit Protected Longitudinal Acceleration";
BA_ "SignalType" SG_ 844 IMUProtLonAcc "SNM";
BA_ "VNSigAllNodes" SG_ 844 IMUProtLonAcc 1;
BA_ "SignalLongName" SG_ 844 IMUProtLatAccM "Inertial Measurement Unit Protected Lateral Acceleration Mask";
BA_ "SignalType" SG_ 844 IMUProtLatAccM "ENM";
BA_ "VNSigAllNodes" SG_ 844 IMUProtLatAccM 1;
BA_ "SignalLongName" SG_ 844 IMUProtLatAcc "Inertial Measurement Unit Protected Lateral Acceleration";
BA_ "SignalType" SG_ 844 IMUProtLatAcc "SNM";
BA_ "VNSigAllNodes" SG_ 844 IMUProtLatAcc 1;
BA_ "SignalLongName" SG_ 844 IMUProtChksum "Inertial Measurement Unit Protected state0589";
BA_ "SignalType" SG_ 844 IMUProtChksum "UNM";
BA_ "VNSigAllNodes" SG_ 844 IMUProtChksum 1;
BA_ "SignalLongName" SG_ 844 IMUProtARC "Inertial Measurement Unit Protected Alive Rolling Count";
BA_ "SignalType" SG_ 844 IMUProtARC "UNM";
BA_ "VNSigAllNodes" SG_ 844 IMUProtARC 1;
BA_ "SignalLongName" SG_ 528 BrkSysAutBrkReqRC "Brake System Autonomous Braking Request Rolling Count";
BA_ "SignalType" SG_ 528 BrkSysAutBrkReqRC "UNM";
BA_ "VNSigAllNodes" SG_ 528 BrkSysAutBrkReqRC 1;
BA_ "SignalLongName" SG_ 528 BrkSysAutBrkReqPVal "Brake System Autonomous Braking Request Protection Value";
BA_ "SignalType" SG_ 528 BrkSysAutBrkReqPVal "UNM";
BA_ "VNSigAllNodes" SG_ 528 BrkSysAutBrkReqPVal 1;
BA_ "SignalLongName" SG_ 528 BSABR_TrlBrkRq "Brake System Autonomous Braking Request : Trailer Brake Request";
BA_ "PacketOrder" SG_ 528 BSABR_TrlBrkRq 1;
BA_ "SignalType" SG_ 528 BSABR_TrlBrkRq "UNM";
BA_ "VNSigAllNodes" SG_ 528 BSABR_TrlBrkRq 1;
BA_ "SignalLongName" SG_ 528 BSABR_TrlBrkCntlIntRq "Brake System Autonomous Braking Request : Trailer Brake Control Interactive Request";
BA_ "PacketOrder" SG_ 528 BSABR_TrlBrkCntlIntRq 2;
BA_ "SignalType" SG_ 528 BSABR_TrlBrkCntlIntRq "BLN";
BA_ "VNSigAllNodes" SG_ 528 BSABR_TrlBrkCntlIntRq 1;
BA_ "SignalLongName" SG_ 462 SecAxlLkTqRqCplRqTp "Secondary Axle Locking Torque Request Coupling Request Type";
BA_ "SignalType" SG_ 462 SecAxlLkTqRqCplRqTp "ENM";
BA_ "VNSigAllNodes" SG_ 462 SecAxlLkTqRqCplRqTp 1;
BA_ "SignalLongName" SG_ 462 SecAxlTrqReqProtVal "Secondary Axle Torque Request Protection Value";
BA_ "SignalType" SG_ 462 SecAxlTrqReqProtVal "UNM";
BA_ "VNSigAllNodes" SG_ 462 SecAxlTrqReqProtVal 1;
BA_ "SignalLongName" SG_ 462 SecAxlTrqReqARollCnt "Secondary Axle Torque Request Alive Rolling Count";
BA_ "SignalType" SG_ 462 SecAxlTrqReqARollCnt "UNM";
BA_ "VNSigAllNodes" SG_ 462 SecAxlTrqReqARollCnt 1;
BA_ "SignalLongName" SG_ 462 SATRCplReqVal "Secondary Axle Torque Request : Coupling Request Value";
BA_ "PacketOrder" SG_ 462 SATRCplReqVal 2;
BA_ "SignalType" SG_ 462 SATRCplReqVal "UNM";
BA_ "VNSigAllNodes" SG_ 462 SATRCplReqVal 1;
BA_ "SignalLongName" SG_ 462 SATRCplReqAtv "Secondary Axle Torque Request : Coupling Request Active";
BA_ "PacketOrder" SG_ 462 SATRCplReqAtv 1;
BA_ "SignalType" SG_ 462 SATRCplReqAtv "BLN";
BA_ "VNSigAllNodes" SG_ 462 SATRCplReqAtv 1;
BA_ "SignalLongName" SG_ 510 BPSUD_MsCyPrSnsSUpVal "Brake Pressure Sensor Unprocessed Data : Master Cylinder Pressure Sensor Supply Unprocessed Value";
BA_ "PacketOrder" SG_ 510 BPSUD_MsCyPrSnsSUpVal 3;
BA_ "SignalType" SG_ 510 BPSUD_MsCyPrSnsSUpVal "UNM";
BA_ "VNSigAllNodes" SG_ 510 BPSUD_MsCyPrSnsSUpVal 1;
BA_ "SignalLongName" SG_ 510 BPSUD_MsCyPrSns2UpVal "Brake Pressure Sensor Unprocessed Data : Master Cylinder Pressure Sensor 2 Unprocessed Value";
BA_ "PacketOrder" SG_ 510 BPSUD_MsCyPrSns2UpVal 2;
BA_ "SignalType" SG_ 510 BPSUD_MsCyPrSns2UpVal "UNM";
BA_ "VNSigAllNodes" SG_ 510 BPSUD_MsCyPrSns2UpVal 1;
BA_ "SignalLongName" SG_ 510 BPSUD_MsCyPrSns1UpVal "Brake Pressure Sensor Unprocessed Data : Master Cylinder Pressure Sensor 1 Unprocessed Value";
BA_ "PacketOrder" SG_ 510 BPSUD_MsCyPrSns1UpVal 1;
BA_ "SignalType" SG_ 510 BPSUD_MsCyPrSns1UpVal "UNM";
BA_ "VNSigAllNodes" SG_ 510 BPSUD_MsCyPrSns1UpVal 1;
BA_ "SignalLongName" SG_ 510 BrkPresSnsrDataChksm "Brake Pressure Sensor Data state0589";
BA_ "SignalType" SG_ 510 BrkPresSnsrDataChksm "UNM";
BA_ "VNSigAllNodes" SG_ 510 BrkPresSnsrDataChksm 1;
BA_ "SignalLongName" SG_ 510 BrkPresSnsrDataARC "Brake Pressure Sensor Data Alive Rolling Count";
BA_ "SignalType" SG_ 510 BrkPresSnsrDataARC "UNM";
BA_ "VNSigAllNodes" SG_ 510 BrkPresSnsrDataARC 1;
BA_ "SignalLongName" SG_ 1920 DTCI_CurrentStatus_780 "Diagnostic Trouble Code Information Extended 780 : Current Status";
BA_ "PacketOrder" SG_ 1920 DTCI_CurrentStatus_780 18;
BA_ "SignalType" SG_ 1920 DTCI_CurrentStatus_780 "BLN";
BA_ "VNSigAllNodes" SG_ 1920 DTCI_CurrentStatus_780 1;
BA_ "SignalLongName" SG_ 1920 DTCI_WrnIndRqdSt_780 "Diagnostic Trouble Code Information Extended 780 : Warning Indicator Requested Status";
BA_ "PacketOrder" SG_ 1920 DTCI_WrnIndRqdSt_780 12;
BA_ "SignalType" SG_ 1920 DTCI_WrnIndRqdSt_780 "BLN";
BA_ "VNSigAllNodes" SG_ 1920 DTCI_WrnIndRqdSt_780 1;
BA_ "SignalLongName" SG_ 1920 DTCIUnused7_780 "Diagnostic Trouble Code Information Extended 780 : Unused 7";
BA_ "PacketOrder" SG_ 1920 DTCIUnused7_780 7;
BA_ "SignalType" SG_ 1920 DTCIUnused7_780 "BLN";
BA_ "VNSigAllNodes" SG_ 1920 DTCIUnused7_780 1;
BA_ "SignalLongName" SG_ 1920 DTCIUnused6_780 "Diagnostic Trouble Code Information Extended 780 : Unused 6";
BA_ "PacketOrder" SG_ 1920 DTCIUnused6_780 6;
BA_ "SignalType" SG_ 1920 DTCIUnused6_780 "BLN";
BA_ "VNSigAllNodes" SG_ 1920 DTCIUnused6_780 1;
BA_ "SignalLongName" SG_ 1920 DTCIUnused5_780 "Diagnostic Trouble Code Information Extended 780 : Unused 5";
BA_ "PacketOrder" SG_ 1920 DTCIUnused5_780 5;
BA_ "SignalType" SG_ 1920 DTCIUnused5_780 "BLN";
BA_ "VNSigAllNodes" SG_ 1920 DTCIUnused5_780 1;
BA_ "SignalLongName" SG_ 1920 DTCIUnused4_780 "Diagnostic Trouble Code Information Extended 780 : Unused 4";
BA_ "PacketOrder" SG_ 1920 DTCIUnused4_780 4;
BA_ "SignalType" SG_ 1920 DTCIUnused4_780 "BLN";
BA_ "VNSigAllNodes" SG_ 1920 DTCIUnused4_780 1;
BA_ "SignalLongName" SG_ 1920 DTCIUnused3_780 "Diagnostic Trouble Code Information Extended 780 : Unused 3";
BA_ "PacketOrder" SG_ 1920 DTCIUnused3_780 3;
BA_ "SignalType" SG_ 1920 DTCIUnused3_780 "BLN";
BA_ "VNSigAllNodes" SG_ 1920 DTCIUnused3_780 1;
BA_ "SignalLongName" SG_ 1920 DTCIUnused2_780 "Diagnostic Trouble Code Information Extended 780 : Unused 2";
BA_ "PacketOrder" SG_ 1920 DTCIUnused2_780 2;
BA_ "SignalType" SG_ 1920 DTCIUnused2_780 "BLN";
BA_ "VNSigAllNodes" SG_ 1920 DTCIUnused2_780 1;
BA_ "SignalLongName" SG_ 1920 DTCIUnused1_780 "Diagnostic Trouble Code Information Extended 780 : Unused 1";
BA_ "PacketOrder" SG_ 1920 DTCIUnused1_780 1;
BA_ "SignalType" SG_ 1920 DTCIUnused1_780 "BLN";
BA_ "VNSigAllNodes" SG_ 1920 DTCIUnused1_780 1;
BA_ "SignalLongName" SG_ 1920 DTCI_TstNPsdPwrUpSt_780 "Diagnostic Trouble Code Information Extended 780 : Test Not Passed Since Power Up Status";
BA_ "PacketOrder" SG_ 1920 DTCI_TstNPsdPwrUpSt_780 14;
BA_ "SignalType" SG_ 1920 DTCI_TstNPsdPwrUpSt_780 "BLN";
BA_ "VNSigAllNodes" SG_ 1920 DTCI_TstNPsdPwrUpSt_780 1;
BA_ "SignalLongName" SG_ 1920 DTCI_TstNPsdCdClrdSt_780 "Diagnostic Trouble Code Information Extended 780 : Test Not Passed Since Code Cleared Status";
BA_ "PacketOrder" SG_ 1920 DTCI_TstNPsdCdClrdSt_780 17;
BA_ "SignalType" SG_ 1920 DTCI_TstNPsdCdClrdSt_780 "BLN";
BA_ "VNSigAllNodes" SG_ 1920 DTCI_TstNPsdCdClrdSt_780 1;
BA_ "SignalLongName" SG_ 1920 DTCI_TstFldPwrUpSt_780 "Diagnostic Trouble Code Information Extended 780 : Test Failed Since Power Up Status";
BA_ "PacketOrder" SG_ 1920 DTCI_TstFldPwrUpSt_780 13;
BA_ "SignalType" SG_ 1920 DTCI_TstFldPwrUpSt_780 "BLN";
BA_ "VNSigAllNodes" SG_ 1920 DTCI_TstFldPwrUpSt_780 1;
BA_ "SignalLongName" SG_ 1920 DTCI_TstFldCdClrdStat_780 "Diagnostic Trouble Code Information Extended 780 : Test Failed Since Code Cleared Status";
BA_ "PacketOrder" SG_ 1920 DTCI_TstFldCdClrdStat_780 16;
BA_ "SignalType" SG_ 1920 DTCI_TstFldCdClrdStat_780 "BLN";
BA_ "VNSigAllNodes" SG_ 1920 DTCI_TstFldCdClrdStat_780 1;
BA_ "SignalLongName" SG_ 1920 DTCI_HistStat_780 "Diagnostic Trouble Code Information Extended 780 : History Status";
BA_ "PacketOrder" SG_ 1920 DTCI_HistStat_780 15;
BA_ "SignalType" SG_ 1920 DTCI_HistStat_780 "BLN";
BA_ "VNSigAllNodes" SG_ 1920 DTCI_HistStat_780 1;
BA_ "SignalLongName" SG_ 1920 DTCI_DTCTriggered_780 "Diagnostic Trouble Code Information Extended 780 : Diagnostic Trouble Code Triggered";
BA_ "PacketOrder" SG_ 1920 DTCI_DTCTriggered_780 8;
BA_ "SignalType" SG_ 1920 DTCI_DTCTriggered_780 "BLN";
BA_ "VNSigAllNodes" SG_ 1920 DTCI_DTCTriggered_780 1;
BA_ "SignalLongName" SG_ 1920 DTCI_DTCSource_780 "Diagnostic Trouble Code Information Extended 780 : Diagnostic Trouble Code Source";
BA_ "PacketOrder" SG_ 1920 DTCI_DTCSource_780 9;
BA_ "SignalType" SG_ 1920 DTCI_DTCSource_780 "UNM";
BA_ "VNSigAllNodes" SG_ 1920 DTCI_DTCSource_780 1;
BA_ "SignalLongName" SG_ 1920 DTCI_DTCNumber_780 "Diagnostic Trouble Code Information Extended 780 : Diagnostic Trouble Code Number";
BA_ "PacketOrder" SG_ 1920 DTCI_DTCNumber_780 10;
BA_ "SignalType" SG_ 1920 DTCI_DTCNumber_780 "UNM";
BA_ "VNSigAllNodes" SG_ 1920 DTCI_DTCNumber_780 1;
BA_ "SignalLongName" SG_ 1920 DTCI_DTCFaultType_780 "Diagnostic Trouble Code Information Extended 780 : Diagnostic Trouble Code Fault Type";
BA_ "PacketOrder" SG_ 1920 DTCI_DTCFaultType_780 20;
BA_ "SignalType" SG_ 1920 DTCI_DTCFaultType_780 "ENM";
BA_ "VNSigAllNodes" SG_ 1920 DTCI_DTCFaultType_780 1;
BA_ "SignalLongName" SG_ 1920 DTCI_DTCFailType_780 "Diagnostic Trouble Code Information Extended 780 : Diagnostic Trouble Code Failure Type";
BA_ "PacketOrder" SG_ 1920 DTCI_DTCFailType_780 11;
BA_ "SignalType" SG_ 1920 DTCI_DTCFailType_780 "UNM";
BA_ "VNSigAllNodes" SG_ 1920 DTCI_DTCFailType_780 1;
BA_ "SignalLongName" SG_ 1920 DTCI_CodeSupported_780 "Diagnostic Trouble Code Information Extended 780 : Code Supported";
BA_ "PacketOrder" SG_ 1920 DTCI_CodeSupported_780 19;
BA_ "SignalType" SG_ 1920 DTCI_CodeSupported_780 "BLN";
BA_ "VNSigAllNodes" SG_ 1920 DTCI_CodeSupported_780 1;
BA_ "SignalLongName" SG_ 1907 DTCI_DTCFaultType_773 "Diagnostic Trouble Code Information Extended 773 : Diagnostic Trouble Code Fault Type";
BA_ "PacketOrder" SG_ 1907 DTCI_DTCFaultType_773 20;
BA_ "SignalType" SG_ 1907 DTCI_DTCFaultType_773 "ENM";
BA_ "VNSigAllNodes" SG_ 1907 DTCI_DTCFaultType_773 1;
BA_ "SignalLongName" SG_ 1907 DTCI_CodeSupported_773 "Diagnostic Trouble Code Information Extended 773 : Code Supported";
BA_ "PacketOrder" SG_ 1907 DTCI_CodeSupported_773 19;
BA_ "SignalType" SG_ 1907 DTCI_CodeSupported_773 "BLN";
BA_ "VNSigAllNodes" SG_ 1907 DTCI_CodeSupported_773 1;
BA_ "SignalLongName" SG_ 1907 DTCI_CurrentStatus_773 "Diagnostic Trouble Code Information Extended 773 : Current Status";
BA_ "PacketOrder" SG_ 1907 DTCI_CurrentStatus_773 18;
BA_ "SignalType" SG_ 1907 DTCI_CurrentStatus_773 "BLN";
BA_ "VNSigAllNodes" SG_ 1907 DTCI_CurrentStatus_773 1;
BA_ "SignalLongName" SG_ 1907 DTCI_TstNPsdCdClrdSt_773 "Diagnostic Trouble Code Information Extended 773 : Test Not Passed Since Code Cleared Status";
BA_ "PacketOrder" SG_ 1907 DTCI_TstNPsdCdClrdSt_773 17;
BA_ "SignalType" SG_ 1907 DTCI_TstNPsdCdClrdSt_773 "BLN";
BA_ "VNSigAllNodes" SG_ 1907 DTCI_TstNPsdCdClrdSt_773 1;
BA_ "SignalLongName" SG_ 1907 DTCI_TstFldCdClrdStat_773 "Diagnostic Trouble Code Information Extended 773 : Test Failed Since Code Cleared Status";
BA_ "PacketOrder" SG_ 1907 DTCI_TstFldCdClrdStat_773 16;
BA_ "SignalType" SG_ 1907 DTCI_TstFldCdClrdStat_773 "BLN";
BA_ "VNSigAllNodes" SG_ 1907 DTCI_TstFldCdClrdStat_773 1;
BA_ "SignalLongName" SG_ 1907 DTCI_HistStat_773 "Diagnostic Trouble Code Information Extended 773 : History Status";
BA_ "PacketOrder" SG_ 1907 DTCI_HistStat_773 15;
BA_ "SignalType" SG_ 1907 DTCI_HistStat_773 "BLN";
BA_ "VNSigAllNodes" SG_ 1907 DTCI_HistStat_773 1;
BA_ "SignalLongName" SG_ 1907 DTCI_TstNPsdPwrUpSt_773 "Diagnostic Trouble Code Information Extended 773 : Test Not Passed Since Power Up Status";
BA_ "PacketOrder" SG_ 1907 DTCI_TstNPsdPwrUpSt_773 14;
BA_ "SignalType" SG_ 1907 DTCI_TstNPsdPwrUpSt_773 "BLN";
BA_ "VNSigAllNodes" SG_ 1907 DTCI_TstNPsdPwrUpSt_773 1;
BA_ "SignalLongName" SG_ 1907 DTCI_TstFldPwrUpSt_773 "Diagnostic Trouble Code Information Extended 773 : Test Failed Since Power Up Status";
BA_ "PacketOrder" SG_ 1907 DTCI_TstFldPwrUpSt_773 13;
BA_ "SignalType" SG_ 1907 DTCI_TstFldPwrUpSt_773 "BLN";
BA_ "VNSigAllNodes" SG_ 1907 DTCI_TstFldPwrUpSt_773 1;
BA_ "SignalLongName" SG_ 1907 DTCI_WrnIndRqdSt_773 "Diagnostic Trouble Code Information Extended 773 : Warning Indicator Requested Status";
BA_ "PacketOrder" SG_ 1907 DTCI_WrnIndRqdSt_773 12;
BA_ "SignalType" SG_ 1907 DTCI_WrnIndRqdSt_773 "BLN";
BA_ "VNSigAllNodes" SG_ 1907 DTCI_WrnIndRqdSt_773 1;
BA_ "SignalLongName" SG_ 1907 DTCI_DTCFailType_773 "Diagnostic Trouble Code Information Extended 773 : Diagnostic Trouble Code Failure Type";
BA_ "PacketOrder" SG_ 1907 DTCI_DTCFailType_773 11;
BA_ "SignalType" SG_ 1907 DTCI_DTCFailType_773 "UNM";
BA_ "VNSigAllNodes" SG_ 1907 DTCI_DTCFailType_773 1;
BA_ "SignalLongName" SG_ 1907 DTCI_DTCNumber_773 "Diagnostic Trouble Code Information Extended 773 : Diagnostic Trouble Code Number";
BA_ "PacketOrder" SG_ 1907 DTCI_DTCNumber_773 10;
BA_ "SignalType" SG_ 1907 DTCI_DTCNumber_773 "UNM";
BA_ "VNSigAllNodes" SG_ 1907 DTCI_DTCNumber_773 1;
BA_ "SignalLongName" SG_ 1907 DTCI_DTCSource_773 "Diagnostic Trouble Code Information Extended 773 : Diagnostic Trouble Code Source";
BA_ "PacketOrder" SG_ 1907 DTCI_DTCSource_773 9;
BA_ "SignalType" SG_ 1907 DTCI_DTCSource_773 "UNM";
BA_ "VNSigAllNodes" SG_ 1907 DTCI_DTCSource_773 1;
BA_ "SignalLongName" SG_ 1907 DTCI_DTCTriggered_773 "Diagnostic Trouble Code Information Extended 773 : Diagnostic Trouble Code Triggered";
BA_ "PacketOrder" SG_ 1907 DTCI_DTCTriggered_773 8;
BA_ "SignalType" SG_ 1907 DTCI_DTCTriggered_773 "BLN";
BA_ "VNSigAllNodes" SG_ 1907 DTCI_DTCTriggered_773 1;
BA_ "SignalLongName" SG_ 1907 DTCIUnused7_773 "Diagnostic Trouble Code Information Extended 773 : Unused 7";
BA_ "PacketOrder" SG_ 1907 DTCIUnused7_773 7;
BA_ "SignalType" SG_ 1907 DTCIUnused7_773 "BLN";
BA_ "VNSigAllNodes" SG_ 1907 DTCIUnused7_773 1;
BA_ "SignalLongName" SG_ 1907 DTCIUnused6_773 "Diagnostic Trouble Code Information Extended 773 : Unused 6";
BA_ "PacketOrder" SG_ 1907 DTCIUnused6_773 6;
BA_ "SignalType" SG_ 1907 DTCIUnused6_773 "BLN";
BA_ "VNSigAllNodes" SG_ 1907 DTCIUnused6_773 1;
BA_ "SignalLongName" SG_ 1907 DTCIUnused5_773 "Diagnostic Trouble Code Information Extended 773 : Unused 5";
BA_ "PacketOrder" SG_ 1907 DTCIUnused5_773 5;
BA_ "SignalType" SG_ 1907 DTCIUnused5_773 "BLN";
BA_ "VNSigAllNodes" SG_ 1907 DTCIUnused5_773 1;
BA_ "SignalLongName" SG_ 1907 DTCIUnused4_773 "Diagnostic Trouble Code Information Extended 773 : Unused 4";
BA_ "PacketOrder" SG_ 1907 DTCIUnused4_773 4;
BA_ "SignalType" SG_ 1907 DTCIUnused4_773 "BLN";
BA_ "VNSigAllNodes" SG_ 1907 DTCIUnused4_773 1;
BA_ "SignalLongName" SG_ 1907 DTCIUnused3_773 "Diagnostic Trouble Code Information Extended 773 : Unused 3";
BA_ "PacketOrder" SG_ 1907 DTCIUnused3_773 3;
BA_ "SignalType" SG_ 1907 DTCIUnused3_773 "BLN";
BA_ "VNSigAllNodes" SG_ 1907 DTCIUnused3_773 1;
BA_ "SignalLongName" SG_ 1907 DTCIUnused2_773 "Diagnostic Trouble Code Information Extended 773 : Unused 2";
BA_ "PacketOrder" SG_ 1907 DTCIUnused2_773 2;
BA_ "SignalType" SG_ 1907 DTCIUnused2_773 "BLN";
BA_ "VNSigAllNodes" SG_ 1907 DTCIUnused2_773 1;
BA_ "SignalLongName" SG_ 1907 DTCIUnused1_773 "Diagnostic Trouble Code Information Extended 773 : Unused 1";
BA_ "PacketOrder" SG_ 1907 DTCIUnused1_773 1;
BA_ "SignalType" SG_ 1907 DTCIUnused1_773 "BLN";
BA_ "VNSigAllNodes" SG_ 1907 DTCIUnused1_773 1;
BA_ "SignalLongName" SG_ 1603 DgnInf "Diagnostic Information";
BA_ "SignalType" SG_ 1603 DgnInf "UNM";
BA_ "VNSigAllNodes" SG_ 1603 DgnInf 1;
BA_ "VNSigSLHSSharedDiagnostic" SG_ 1603 DgnInf 1;
BA_ "SignalLongName" SG_ 1347 DgnInf_HS543 "Diagnostic Information HS543";
BA_ "SignalType" SG_ 1347 DgnInf_HS543 "UNM";
BA_ "VNSigAllNodes" SG_ 1347 DgnInf_HS543 1;
BA_ "VNSigSLHSSharedDiagnostic" SG_ 1347 DgnInf_HS543 1;
BA_ "SignalLongName" SG_ 603 DgnInf "Diagnostic Information";
BA_ "SignalType" SG_ 603 DgnInf "UNM";
BA_ "VNSigAllNodes" SG_ 603 DgnInf 1;
BA_ "VNSigSLHSSharedDiagnostic" SG_ 603 DgnInf 1;
BA_ "SignalLongName" SG_ 1371 DgnInf_HS55B "Diagnostic Information HS55B";
BA_ "SignalType" SG_ 1371 DgnInf_HS55B "UNM";
BA_ "VNSigAllNodes" SG_ 1371 DgnInf_HS55B 1;
BA_ "VNSigSLHSSharedDiagnostic" SG_ 1371 DgnInf_HS55B 1;
BA_ "SignalLongName" SG_ 1627 DgnInf "Diagnostic Information";
BA_ "SignalType" SG_ 1627 DgnInf "UNM";
BA_ "VNSigAllNodes" SG_ 1627 DgnInf 1;
BA_ "VNSigSLHSSharedDiagnostic" SG_ 1627 DgnInf 1;
BA_ "SignalLongName" SG_ 1915 DTCI_DTCFaultType_77B "Diagnostic Trouble Code Information Extended 77B : Diagnostic Trouble Code Fault Type";
BA_ "PacketOrder" SG_ 1915 DTCI_DTCFaultType_77B 20;
BA_ "SignalType" SG_ 1915 DTCI_DTCFaultType_77B "ENM";
BA_ "VNSigAllNodes" SG_ 1915 DTCI_DTCFaultType_77B 1;
BA_ "SignalLongName" SG_ 1915 DTCI_CodeSupported_77B "Diagnostic Trouble Code Information Extended 77B : Code Supported";
BA_ "PacketOrder" SG_ 1915 DTCI_CodeSupported_77B 19;
BA_ "SignalType" SG_ 1915 DTCI_CodeSupported_77B "BLN";
BA_ "VNSigAllNodes" SG_ 1915 DTCI_CodeSupported_77B 1;
BA_ "SignalLongName" SG_ 1915 DTCI_CurrentStatus_77B "Diagnostic Trouble Code Information Extended 77B : Current Status";
BA_ "PacketOrder" SG_ 1915 DTCI_CurrentStatus_77B 18;
BA_ "SignalType" SG_ 1915 DTCI_CurrentStatus_77B "BLN";
BA_ "VNSigAllNodes" SG_ 1915 DTCI_CurrentStatus_77B 1;
BA_ "SignalLongName" SG_ 1915 DTCI_TstNPsdCdClrdSt_77B "Diagnostic Trouble Code Information Extended 77B : Test Not Passed Since Code Cleared Status";
BA_ "PacketOrder" SG_ 1915 DTCI_TstNPsdCdClrdSt_77B 17;
BA_ "SignalType" SG_ 1915 DTCI_TstNPsdCdClrdSt_77B "BLN";
BA_ "VNSigAllNodes" SG_ 1915 DTCI_TstNPsdCdClrdSt_77B 1;
BA_ "SignalLongName" SG_ 1915 DTCI_TstFldCdClrdStat_77B "Diagnostic Trouble Code Information Extended 77B : Test Failed Since Code Cleared Status";
BA_ "PacketOrder" SG_ 1915 DTCI_TstFldCdClrdStat_77B 16;
BA_ "SignalType" SG_ 1915 DTCI_TstFldCdClrdStat_77B "BLN";
BA_ "VNSigAllNodes" SG_ 1915 DTCI_TstFldCdClrdStat_77B 1;
BA_ "SignalLongName" SG_ 1915 DTCI_HistStat_77B "Diagnostic Trouble Code Information Extended 77B : History Status";
BA_ "PacketOrder" SG_ 1915 DTCI_HistStat_77B 15;
BA_ "SignalType" SG_ 1915 DTCI_HistStat_77B "BLN";
BA_ "VNSigAllNodes" SG_ 1915 DTCI_HistStat_77B 1;
BA_ "SignalLongName" SG_ 1915 DTCI_TstNPsdPwrUpSt_77B "Diagnostic Trouble Code Information Extended 77B : Test Not Passed Since Power Up Status";
BA_ "PacketOrder" SG_ 1915 DTCI_TstNPsdPwrUpSt_77B 14;
BA_ "SignalType" SG_ 1915 DTCI_TstNPsdPwrUpSt_77B "BLN";
BA_ "VNSigAllNodes" SG_ 1915 DTCI_TstNPsdPwrUpSt_77B 1;
BA_ "SignalLongName" SG_ 1915 DTCI_TstFldPwrUpSt_77B "Diagnostic Trouble Code Information Extended 77B : Test Failed Since Power Up Status";
BA_ "PacketOrder" SG_ 1915 DTCI_TstFldPwrUpSt_77B 13;
BA_ "SignalType" SG_ 1915 DTCI_TstFldPwrUpSt_77B "BLN";
BA_ "VNSigAllNodes" SG_ 1915 DTCI_TstFldPwrUpSt_77B 1;
BA_ "SignalLongName" SG_ 1915 DTCI_WrnIndRqdSt_77B "Diagnostic Trouble Code Information Extended 77B : Warning Indicator Requested Status";
BA_ "PacketOrder" SG_ 1915 DTCI_WrnIndRqdSt_77B 12;
BA_ "SignalType" SG_ 1915 DTCI_WrnIndRqdSt_77B "BLN";
BA_ "VNSigAllNodes" SG_ 1915 DTCI_WrnIndRqdSt_77B 1;
BA_ "SignalLongName" SG_ 1915 DTCI_DTCFailType_77B "Diagnostic Trouble Code Information Extended 77B : Diagnostic Trouble Code Failure Type";
BA_ "PacketOrder" SG_ 1915 DTCI_DTCFailType_77B 11;
BA_ "SignalType" SG_ 1915 DTCI_DTCFailType_77B "UNM";
BA_ "VNSigAllNodes" SG_ 1915 DTCI_DTCFailType_77B 1;
BA_ "SignalLongName" SG_ 1915 DTCI_DTCNumber_77B "Diagnostic Trouble Code Information Extended 77B : Diagnostic Trouble Code Number";
BA_ "PacketOrder" SG_ 1915 DTCI_DTCNumber_77B 10;
BA_ "SignalType" SG_ 1915 DTCI_DTCNumber_77B "UNM";
BA_ "VNSigAllNodes" SG_ 1915 DTCI_DTCNumber_77B 1;
BA_ "SignalLongName" SG_ 1915 DTCI_DTCSource_77B "Diagnostic Trouble Code Information Extended 77B : Diagnostic Trouble Code Source";
BA_ "PacketOrder" SG_ 1915 DTCI_DTCSource_77B 9;
BA_ "SignalType" SG_ 1915 DTCI_DTCSource_77B "UNM";
BA_ "VNSigAllNodes" SG_ 1915 DTCI_DTCSource_77B 1;
BA_ "SignalLongName" SG_ 1915 DTCI_DTCTriggered_77B "Diagnostic Trouble Code Information Extended 77B : Diagnostic Trouble Code Triggered";
BA_ "PacketOrder" SG_ 1915 DTCI_DTCTriggered_77B 8;
BA_ "SignalType" SG_ 1915 DTCI_DTCTriggered_77B "BLN";
BA_ "VNSigAllNodes" SG_ 1915 DTCI_DTCTriggered_77B 1;
BA_ "SignalLongName" SG_ 1915 DTCIUnused7_77B "Diagnostic Trouble Code Information Extended 77B : Unused 7";
BA_ "PacketOrder" SG_ 1915 DTCIUnused7_77B 7;
BA_ "SignalType" SG_ 1915 DTCIUnused7_77B "BLN";
BA_ "VNSigAllNodes" SG_ 1915 DTCIUnused7_77B 1;
BA_ "SignalLongName" SG_ 1915 DTCIUnused6_77B "Diagnostic Trouble Code Information Extended 77B : Unused 6";
BA_ "PacketOrder" SG_ 1915 DTCIUnused6_77B 6;
BA_ "SignalType" SG_ 1915 DTCIUnused6_77B "BLN";
BA_ "VNSigAllNodes" SG_ 1915 DTCIUnused6_77B 1;
BA_ "SignalLongName" SG_ 1915 DTCIUnused5_77B "Diagnostic Trouble Code Information Extended 77B : Unused 5";
BA_ "PacketOrder" SG_ 1915 DTCIUnused5_77B 5;
BA_ "SignalType" SG_ 1915 DTCIUnused5_77B "BLN";
BA_ "VNSigAllNodes" SG_ 1915 DTCIUnused5_77B 1;
BA_ "SignalLongName" SG_ 1915 DTCIUnused4_77B "Diagnostic Trouble Code Information Extended 77B : Unused 4";
BA_ "PacketOrder" SG_ 1915 DTCIUnused4_77B 4;
BA_ "SignalType" SG_ 1915 DTCIUnused4_77B "BLN";
BA_ "VNSigAllNodes" SG_ 1915 DTCIUnused4_77B 1;
BA_ "SignalLongName" SG_ 1915 DTCIUnused3_77B "Diagnostic Trouble Code Information Extended 77B : Unused 3";
BA_ "PacketOrder" SG_ 1915 DTCIUnused3_77B 3;
BA_ "SignalType" SG_ 1915 DTCIUnused3_77B "BLN";
BA_ "VNSigAllNodes" SG_ 1915 DTCIUnused3_77B 1;
BA_ "SignalLongName" SG_ 1915 DTCIUnused2_77B "Diagnostic Trouble Code Information Extended 77B : Unused 2";
BA_ "PacketOrder" SG_ 1915 DTCIUnused2_77B 2;
BA_ "SignalType" SG_ 1915 DTCIUnused2_77B "BLN";
BA_ "VNSigAllNodes" SG_ 1915 DTCIUnused2_77B 1;
BA_ "SignalLongName" SG_ 1915 DTCIUnused1_77B "Diagnostic Trouble Code Information Extended 77B : Unused 1";
BA_ "PacketOrder" SG_ 1915 DTCIUnused1_77B 1;
BA_ "SignalType" SG_ 1915 DTCIUnused1_77B "BLN";
BA_ "VNSigAllNodes" SG_ 1915 DTCIUnused1_77B 1;
BA_ "SignalLongName" SG_ 353 ElecShfRngDispRCExtd "Electronic Shift Range Display Rolling Count Extended";
BA_ "SignalType" SG_ 353 ElecShfRngDispRCExtd "UNM";
BA_ "VNSigAllNodes" SG_ 353 ElecShfRngDispRCExtd 1;
BA_ "SignalLongName" SG_ 353 ElecShfRngDisp "Electronic Shift Range Display";
BA_ "SignalType" SG_ 353 ElecShfRngDisp "ENM";
BA_ "VNSigAllNodes" SG_ 353 ElecShfRngDisp 1;
BA_ "SignalLongName" SG_ 353 ESPTransMalfIO "Electronic Shift Primary Transmission Malfunction Indication On";
BA_ "SignalType" SG_ 353 ESPTransMalfIO "BLN";
BA_ "VNSigAllNodes" SG_ 353 ESPTransMalfIO 1;
BA_ "SignalLongName" SG_ 353 ESPRngInvldReqIO "Electronic Shift Primary Range Invalid Request Indication On";
BA_ "SignalType" SG_ 353 ESPRngInvldReqIO "BLN";
BA_ "VNSigAllNodes" SG_ 353 ESPRngInvldReqIO 1;
BA_ "SignalLongName" SG_ 353 ESPPrkInvldReqIO "Electronic Shift Primary Park Invalid Request Indication On";
BA_ "SignalType" SG_ 353 ESPPrkInvldReqIO "BLN";
BA_ "VNSigAllNodes" SG_ 353 ESPPrkInvldReqIO 1;
BA_ "SignalLongName" SG_ 353 ESPHldShfLvrToEngRgIO "Electronic Shift Primary Hold Shift Lever to Engage Range Indication On";
BA_ "SignalType" SG_ 353 ESPHldShfLvrToEngRgIO "BLN";
BA_ "VNSigAllNodes" SG_ 353 ESPHldShfLvrToEngRgIO 1;
BA_ "SignalLongName" SG_ 353 ESPDrvrPrkIlkSftAtdIO "Electronic Shift Primary Driver Park Interlock Shift Attempted Indication On";
BA_ "SignalType" SG_ 353 ESPDrvrPrkIlkSftAtdIO "BLN";
BA_ "VNSigAllNodes" SG_ 353 ESPDrvrPrkIlkSftAtdIO 1;
BA_ "SignalLongName" SG_ 353 ESPDrvrIlkShfAtdIO "Electronic Shift Primary Driver Interlock Shift Attempted Indication On";
BA_ "SignalType" SG_ 353 ESPDrvrIlkShfAtdIO "BLN";
BA_ "VNSigAllNodes" SG_ 353 ESPDrvrIlkShfAtdIO 1;
BA_ "SignalLongName" SG_ 308 PFAS_SrvPedAlrtIO "Pedestrian Friendly Alert Status : Service Pedestrian Friendly Alert Indication On";
BA_ "PacketOrder" SG_ 308 PFAS_SrvPedAlrtIO 7;
BA_ "SignalType" SG_ 308 PFAS_SrvPedAlrtIO "BLN";
BA_ "VNSigAllNodes" SG_ 308 PFAS_SrvPedAlrtIO 1;
BA_ "SignalLongName" SG_ 308 PFAS_PFASysStat "Pedestrian Friendly Alert Status : Pedestrian Friendly Alert System Status";
BA_ "PacketOrder" SG_ 308 PFAS_PFASysStat 6;
BA_ "SignalType" SG_ 308 PFAS_PFASysStat "ENM";
BA_ "VNSigAllNodes" SG_ 308 PFAS_PFASysStat 1;
BA_ "SignalLongName" SG_ 308 PFAS_PFASndVolCtrl "Pedestrian Friendly Alert Status : Pedestrian Friendly Alert Sound Volume Control";
BA_ "PacketOrder" SG_ 308 PFAS_PFASndVolCtrl 5;
BA_ "SignalType" SG_ 308 PFAS_PFASndVolCtrl "UNM";
BA_ "VNSigAllNodes" SG_ 308 PFAS_PFASndVolCtrl 1;
BA_ "SignalLongName" SG_ 308 PFAS_PFASndGenEn "Pedestrian Friendly Alert Status : Pedestrian Friendly Alert Sound Generation Enable";
BA_ "PacketOrder" SG_ 308 PFAS_PFASndGenEn 1;
BA_ "SignalType" SG_ 308 PFAS_PFASndGenEn "BLN";
BA_ "VNSigAllNodes" SG_ 308 PFAS_PFASndGenEn 1;
BA_ "SignalLongName" SG_ 308 PFAS_PFARevSnd "Pedestrian Friendly Alert Status : Pedestrian Friendly Alert Reverse Sound";
BA_ "PacketOrder" SG_ 308 PFAS_PFARevSnd 3;
BA_ "SignalType" SG_ 308 PFAS_PFARevSnd "ENM";
BA_ "VNSigAllNodes" SG_ 308 PFAS_PFARevSnd 1;
BA_ "SignalLongName" SG_ 308 PFAS_PFAFwdSnd "Pedestrian Friendly Alert Status : Pedestrian Friendly Alert Forward Sound";
BA_ "PacketOrder" SG_ 308 PFAS_PFAFwdSnd 2;
BA_ "SignalType" SG_ 308 PFAS_PFAFwdSnd "ENM";
BA_ "VNSigAllNodes" SG_ 308 PFAS_PFAFwdSnd 1;
BA_ "SignalLongName" SG_ 308 PFAS_PFACrsOvrSpd "Pedestrian Friendly Alert Status : Pedestrian Friendly Alert Crossover Speed";
BA_ "PacketOrder" SG_ 308 PFAS_PFACrsOvrSpd 4;
BA_ "SignalType" SG_ 308 PFAS_PFACrsOvrSpd "UNM";
BA_ "VNSigAllNodes" SG_ 308 PFAS_PFACrsOvrSpd 1;
BA_ "SignalLongName" SG_ 308 PedFrndlyAlrtCsSetAvl "Pedestrian Friendly Alert Customization Setting Available";
BA_ "SignalType" SG_ 308 PedFrndlyAlrtCsSetAvl "BLN";
BA_ "VNSigAllNodes" SG_ 308 PedFrndlyAlrtCsSetAvl 1;
BA_ "SignalLongName" SG_ 308 PedFrndlyAlrtCsCrStVal "Pedestrian Friendly Alert Customization Current Setting Value";
BA_ "SignalType" SG_ 308 PedFrndlyAlrtCsCrStVal "ENM";
BA_ "VNSigAllNodes" SG_ 308 PedFrndlyAlrtCsCrStVal 1;
BA_ "SignalLongName" SG_ 563 SPMCA_SusPrfMd6Avl "Suspension Performance Mode Customization Available : Suspension Performance Mode 6 Available";
BA_ "PacketOrder" SG_ 563 SPMCA_SusPrfMd6Avl 6;
BA_ "SignalType" SG_ 563 SPMCA_SusPrfMd6Avl "BLN";
BA_ "VNSigAllNodes" SG_ 563 SPMCA_SusPrfMd6Avl 1;
BA_ "SignalLongName" SG_ 563 SPMCA_SusPrfMd5Avl "Suspension Performance Mode Customization Available : Suspension Performance Mode 5 Available";
BA_ "PacketOrder" SG_ 563 SPMCA_SusPrfMd5Avl 5;
BA_ "SignalType" SG_ 563 SPMCA_SusPrfMd5Avl "BLN";
BA_ "VNSigAllNodes" SG_ 563 SPMCA_SusPrfMd5Avl 1;
BA_ "SignalLongName" SG_ 563 SPMCA_SusPrfMd4Avl "Suspension Performance Mode Customization Available : Suspension Performance Mode 4 Available";
BA_ "PacketOrder" SG_ 563 SPMCA_SusPrfMd4Avl 4;
BA_ "SignalType" SG_ 563 SPMCA_SusPrfMd4Avl "BLN";
BA_ "VNSigAllNodes" SG_ 563 SPMCA_SusPrfMd4Avl 1;
BA_ "SignalLongName" SG_ 563 SPMCA_SusPrfMd3Avl "Suspension Performance Mode Customization Available : Suspension Performance Mode 3 Available";
BA_ "PacketOrder" SG_ 563 SPMCA_SusPrfMd3Avl 3;
BA_ "SignalType" SG_ 563 SPMCA_SusPrfMd3Avl "BLN";
BA_ "VNSigAllNodes" SG_ 563 SPMCA_SusPrfMd3Avl 1;
BA_ "SignalLongName" SG_ 563 SPMCA_SusPrfMd2Avl "Suspension Performance Mode Customization Available : Suspension Performance Mode 2 Available";
BA_ "PacketOrder" SG_ 563 SPMCA_SusPrfMd2Avl 2;
BA_ "SignalType" SG_ 563 SPMCA_SusPrfMd2Avl "BLN";
BA_ "VNSigAllNodes" SG_ 563 SPMCA_SusPrfMd2Avl 1;
BA_ "SignalLongName" SG_ 563 SPMCA_SusPrfMd1Avl "Suspension Performance Mode Customization Available : Suspension Performance Mode 1 Available";
BA_ "PacketOrder" SG_ 563 SPMCA_SusPrfMd1Avl 1;
BA_ "SignalType" SG_ 563 SPMCA_SusPrfMd1Avl "BLN";
BA_ "VNSigAllNodes" SG_ 563 SPMCA_SusPrfMd1Avl 1;
BA_ "SignalLongName" SG_ 563 SPMCA_StrPrfMd6Avl "Steering Performance Mode Customization Available : Steering Performance Mode 6 Available";
BA_ "PacketOrder" SG_ 563 SPMCA_StrPrfMd6Avl 6;
BA_ "SignalType" SG_ 563 SPMCA_StrPrfMd6Avl "BLN";
BA_ "VNSigAllNodes" SG_ 563 SPMCA_StrPrfMd6Avl 1;
BA_ "SignalLongName" SG_ 563 SPMCA_StrPrfMd5Avl "Steering Performance Mode Customization Available : Steering Performance Mode 5 Available";
BA_ "PacketOrder" SG_ 563 SPMCA_StrPrfMd5Avl 5;
BA_ "SignalType" SG_ 563 SPMCA_StrPrfMd5Avl "BLN";
BA_ "VNSigAllNodes" SG_ 563 SPMCA_StrPrfMd5Avl 1;
BA_ "SignalLongName" SG_ 563 SPMCA_StrPrfMd4Avl "Steering Performance Mode Customization Available : Steering Performance Mode 4 Available";
BA_ "PacketOrder" SG_ 563 SPMCA_StrPrfMd4Avl 4;
BA_ "SignalType" SG_ 563 SPMCA_StrPrfMd4Avl "BLN";
BA_ "VNSigAllNodes" SG_ 563 SPMCA_StrPrfMd4Avl 1;
BA_ "SignalLongName" SG_ 563 SPMCA_StrPrfMd3Avl "Steering Performance Mode Customization Available : Steering Performance Mode 3 Available";
BA_ "PacketOrder" SG_ 563 SPMCA_StrPrfMd3Avl 3;
BA_ "SignalType" SG_ 563 SPMCA_StrPrfMd3Avl "BLN";
BA_ "VNSigAllNodes" SG_ 563 SPMCA_StrPrfMd3Avl 1;
BA_ "SignalLongName" SG_ 563 SPMCA_StrPrfMd2Avl "Steering Performance Mode Customization Available : Steering Performance Mode 2 Available";
BA_ "PacketOrder" SG_ 563 SPMCA_StrPrfMd2Avl 2;
BA_ "SignalType" SG_ 563 SPMCA_StrPrfMd2Avl "BLN";
BA_ "VNSigAllNodes" SG_ 563 SPMCA_StrPrfMd2Avl 1;
BA_ "SignalLongName" SG_ 563 SPMCA_StrPrfMd1Avl "Steering Performance Mode Customization Available : Steering Performance Mode 1 Available";
BA_ "PacketOrder" SG_ 563 SPMCA_StrPrfMd1Avl 1;
BA_ "SignalType" SG_ 563 SPMCA_StrPrfMd1Avl "BLN";
BA_ "VNSigAllNodes" SG_ 563 SPMCA_StrPrfMd1Avl 1;
BA_ "SignalLongName" SG_ 563 SPMCA_SndPrfMd6Avl "Sound Performance Mode Customization Available : Sound Performance Mode 6 Available";
BA_ "PacketOrder" SG_ 563 SPMCA_SndPrfMd6Avl 6;
BA_ "SignalType" SG_ 563 SPMCA_SndPrfMd6Avl "BLN";
BA_ "VNSigAllNodes" SG_ 563 SPMCA_SndPrfMd6Avl 1;
BA_ "SignalLongName" SG_ 563 SPMCA_SndPrfMd5Avl "Sound Performance Mode Customization Available : Sound Performance Mode 5 Available";
BA_ "PacketOrder" SG_ 563 SPMCA_SndPrfMd5Avl 5;
BA_ "SignalType" SG_ 563 SPMCA_SndPrfMd5Avl "BLN";
BA_ "VNSigAllNodes" SG_ 563 SPMCA_SndPrfMd5Avl 1;
BA_ "SignalLongName" SG_ 563 SPMCA_SndPrfMd4Avl "Sound Performance Mode Customization Available : Sound Performance Mode 4 Available";
BA_ "PacketOrder" SG_ 563 SPMCA_SndPrfMd4Avl 4;
BA_ "SignalType" SG_ 563 SPMCA_SndPrfMd4Avl "BLN";
BA_ "VNSigAllNodes" SG_ 563 SPMCA_SndPrfMd4Avl 1;
BA_ "SignalLongName" SG_ 563 SPMCA_SndPrfMd3Avl "Sound Performance Mode Customization Available : Sound Performance Mode 3 Available";
BA_ "PacketOrder" SG_ 563 SPMCA_SndPrfMd3Avl 3;
BA_ "SignalType" SG_ 563 SPMCA_SndPrfMd3Avl "BLN";
BA_ "VNSigAllNodes" SG_ 563 SPMCA_SndPrfMd3Avl 1;
BA_ "SignalLongName" SG_ 563 SPMCA_SndPrfMd2Avl "Sound Performance Mode Customization Available : Sound Performance Mode 2 Available";
BA_ "PacketOrder" SG_ 563 SPMCA_SndPrfMd2Avl 2;
BA_ "SignalType" SG_ 563 SPMCA_SndPrfMd2Avl "BLN";
BA_ "VNSigAllNodes" SG_ 563 SPMCA_SndPrfMd2Avl 1;
BA_ "SignalLongName" SG_ 563 SPMCA_SndPrfMd1Avl "Sound Performance Mode Customization Available : Sound Performance Mode 1 Available";
BA_ "PacketOrder" SG_ 563 SPMCA_SndPrfMd1Avl 1;
BA_ "SignalType" SG_ 563 SPMCA_SndPrfMd1Avl "BLN";
BA_ "VNSigAllNodes" SG_ 563 SPMCA_SndPrfMd1Avl 1;
BA_ "SignalLongName" SG_ 563 DPMCA_DispPrfMd6Avl "Display Performance Mode Customization Available : Display Performance Mode 6 Available";
BA_ "PacketOrder" SG_ 563 DPMCA_DispPrfMd6Avl 6;
BA_ "SignalType" SG_ 563 DPMCA_DispPrfMd6Avl "BLN";
BA_ "VNSigAllNodes" SG_ 563 DPMCA_DispPrfMd6Avl 1;
BA_ "SignalLongName" SG_ 563 DPMCA_DispPrfMd5Avl "Display Performance Mode Customization Available : Display Performance Mode 5 Available";
BA_ "PacketOrder" SG_ 563 DPMCA_DispPrfMd5Avl 5;
BA_ "SignalType" SG_ 563 DPMCA_DispPrfMd5Avl "BLN";
BA_ "VNSigAllNodes" SG_ 563 DPMCA_DispPrfMd5Avl 1;
BA_ "SignalLongName" SG_ 563 DPMCA_DispPrfMd4Avl "Display Performance Mode Customization Available : Display Performance Mode 4 Available";
BA_ "PacketOrder" SG_ 563 DPMCA_DispPrfMd4Avl 4;
BA_ "SignalType" SG_ 563 DPMCA_DispPrfMd4Avl "BLN";
BA_ "VNSigAllNodes" SG_ 563 DPMCA_DispPrfMd4Avl 1;
BA_ "SignalLongName" SG_ 563 DPMCA_DispPrfMd3Avl "Display Performance Mode Customization Available : Display Performance Mode 3 Available";
BA_ "PacketOrder" SG_ 563 DPMCA_DispPrfMd3Avl 3;
BA_ "SignalType" SG_ 563 DPMCA_DispPrfMd3Avl "BLN";
BA_ "VNSigAllNodes" SG_ 563 DPMCA_DispPrfMd3Avl 1;
BA_ "SignalLongName" SG_ 563 DPMCA_DispPrfMd2Avl "Display Performance Mode Customization Available : Display Performance Mode 2 Available";
BA_ "PacketOrder" SG_ 563 DPMCA_DispPrfMd2Avl 2;
BA_ "SignalType" SG_ 563 DPMCA_DispPrfMd2Avl "BLN";
BA_ "VNSigAllNodes" SG_ 563 DPMCA_DispPrfMd2Avl 1;
BA_ "SignalLongName" SG_ 563 DPMCA_DispPrfMd1Avl "Display Performance Mode Customization Available : Display Performance Mode 1 Available";
BA_ "PacketOrder" SG_ 563 DPMCA_DispPrfMd1Avl 1;
BA_ "SignalType" SG_ 563 DPMCA_DispPrfMd1Avl "BLN";
BA_ "VNSigAllNodes" SG_ 563 DPMCA_DispPrfMd1Avl 1;
BA_ "SignalLongName" SG_ 563 DPMCA_DrvlPrfMd6Avl "Driveline Performance Mode Customization Available : Driveline Performance Mode 6 Available";
BA_ "PacketOrder" SG_ 563 DPMCA_DrvlPrfMd6Avl 6;
BA_ "SignalType" SG_ 563 DPMCA_DrvlPrfMd6Avl "BLN";
BA_ "VNSigAllNodes" SG_ 563 DPMCA_DrvlPrfMd6Avl 1;
BA_ "SignalLongName" SG_ 563 DPMCA_DrvlPrfMd5Avl "Driveline Performance Mode Customization Available : Driveline Performance Mode 5 Available";
BA_ "PacketOrder" SG_ 563 DPMCA_DrvlPrfMd5Avl 5;
BA_ "SignalType" SG_ 563 DPMCA_DrvlPrfMd5Avl "BLN";
BA_ "VNSigAllNodes" SG_ 563 DPMCA_DrvlPrfMd5Avl 1;
BA_ "SignalLongName" SG_ 563 DPMCA_DrvlPrfMd4Avl "Driveline Performance Mode Customization Available : Driveline Performance Mode 4 Available";
BA_ "PacketOrder" SG_ 563 DPMCA_DrvlPrfMd4Avl 4;
BA_ "SignalType" SG_ 563 DPMCA_DrvlPrfMd4Avl "BLN";
BA_ "VNSigAllNodes" SG_ 563 DPMCA_DrvlPrfMd4Avl 1;
BA_ "SignalLongName" SG_ 563 DPMCA_DrvlPrfMd3Avl "Driveline Performance Mode Customization Available : Driveline Performance Mode 3 Available";
BA_ "PacketOrder" SG_ 563 DPMCA_DrvlPrfMd3Avl 3;
BA_ "SignalType" SG_ 563 DPMCA_DrvlPrfMd3Avl "BLN";
BA_ "VNSigAllNodes" SG_ 563 DPMCA_DrvlPrfMd3Avl 1;
BA_ "SignalLongName" SG_ 563 DPMCA_DrvlPrfMd2Avl "Driveline Performance Mode Customization Available : Driveline Performance Mode 2 Available";
BA_ "PacketOrder" SG_ 563 DPMCA_DrvlPrfMd2Avl 2;
BA_ "SignalType" SG_ 563 DPMCA_DrvlPrfMd2Avl "BLN";
BA_ "VNSigAllNodes" SG_ 563 DPMCA_DrvlPrfMd2Avl 1;
BA_ "SignalLongName" SG_ 563 DPMCA_DrvlPrfMd1Avl "Driveline Performance Mode Customization Available : Driveline Performance Mode 1 Available";
BA_ "PacketOrder" SG_ 563 DPMCA_DrvlPrfMd1Avl 1;
BA_ "SignalType" SG_ 563 DPMCA_DrvlPrfMd1Avl "BLN";
BA_ "VNSigAllNodes" SG_ 563 DPMCA_DrvlPrfMd1Avl 1;
BA_ "SignalLongName" SG_ 384 LKATqOvrDltCmdPrtVl "Lane Keeping Assist Torque Overlay Delta Command Protection Value";
BA_ "SignalType" SG_ 384 LKATqOvrDltCmdPrtVl "UNM";
BA_ "VNSigAllNodes" SG_ 384 LKATqOvrDltCmdPrtVl 1;
BA_ "GenSigDeltaValue" SG_ 384 LKATqOvrDltCmdPrtVl 1;
BA_ "GenSigSendType" SG_ 384 LKATqOvrDltCmdPrtVl 12;
BA_ "SignalLongName" SG_ 384 LKATqOvrDltCmdRC "Lane Keeping Assist Torque Overlay Delta Command Rolling Count";
BA_ "SignalType" SG_ 384 LKATqOvrDltCmdRC "UNM";
BA_ "VNSigAllNodes" SG_ 384 LKATqOvrDltCmdRC 1;
BA_ "GenSigDeltaValue" SG_ 384 LKATqOvrDltCmdRC 1;
BA_ "GenSigSendType" SG_ 384 LKATqOvrDltCmdRC 12;
BA_ "SignalLongName" SG_ 384 LKATODC_TrqVl "Lane Keeping Assist Torque Overlay Delta Command : Torque Value";
BA_ "PacketOrder" SG_ 384 LKATODC_TrqVl 2;
BA_ "SignalType" SG_ 384 LKATODC_TrqVl "SNM";
BA_ "VNSigAllNodes" SG_ 384 LKATODC_TrqVl 1;
BA_ "GenSigDeltaValue" SG_ 384 LKATODC_TrqVl 1;
BA_ "GenSigSendType" SG_ 384 LKATODC_TrqVl 12;
BA_ "SignalLongName" SG_ 384 LKATODC_TrqRqAct "Lane Keeping Assist Torque Overlay Delta Command : Torque Request Active";
BA_ "PacketOrder" SG_ 384 LKATODC_TrqRqAct 1;
BA_ "SignalType" SG_ 384 LKATODC_TrqRqAct "BLN";
BA_ "VNSigAllNodes" SG_ 384 LKATODC_TrqRqAct 1;
BA_ "GenSigSendType" SG_ 384 LKATODC_TrqRqAct 10;
BA_ "SignalLongName" SG_ 866 RegenBrkAxTrqAch "Regenerative Braking Axle Torque Achieved";
BA_ "SignalType" SG_ 866 RegenBrkAxTrqAch "UNM";
BA_ "VNSigAllNodes" SG_ 866 RegenBrkAxTrqAch 1;
BA_ "SignalLongName" SG_ 866 ColPrSysHzrdLghtsReq "Collision Preparation System Hazard Lights Request";
BA_ "SignalType" SG_ 866 ColPrSysHzrdLghtsReq "ENM";
BA_ "VNSigAllNodes" SG_ 866 ColPrSysHzrdLghtsReq 1;
BA_ "SignalLongName" SG_ 866 ColPrSysWndwsReq "Collision Preparation System Windows Request";
BA_ "SignalType" SG_ 866 ColPrSysWndwsReq "ENM";
BA_ "VNSigAllNodes" SG_ 866 ColPrSysWndwsReq 1;
BA_ "SignalLongName" SG_ 866 ColPrSysDrsReq "Collision Preparation System Doors Request";
BA_ "SignalType" SG_ 866 ColPrSysDrsReq "ENM";
BA_ "VNSigAllNodes" SG_ 866 ColPrSysDrsReq 1;
BA_ "SignalLongName" SG_ 866 ColPrSysSnrfReq "Collision Preparation System Sunroof Request";
BA_ "SignalType" SG_ 866 ColPrSysSnrfReq "ENM";
BA_ "VNSigAllNodes" SG_ 866 ColPrSysSnrfReq 1;
BA_ "SignalLongName" SG_ 866 CPSInfotmntMtReq "Collision Preparation System Infotainment Mute Request";
BA_ "SignalType" SG_ 866 CPSInfotmntMtReq "ENM";
BA_ "VNSigAllNodes" SG_ 866 CPSInfotmntMtReq 1;
BA_ "SignalLongName" SG_ 866 StBltTgtSetAvl "Seat Belt Tightening Settings Available";
BA_ "SignalType" SG_ 866 StBltTgtSetAvl "BLN";
BA_ "VNSigAllNodes" SG_ 866 StBltTgtSetAvl 1;
BA_ "SignalLongName" SG_ 866 StBltTgtCrtSetVal "Seat Belt Tightening Current Setting Value";
BA_ "SignalType" SG_ 866 StBltTgtCrtSetVal "ENM";
BA_ "VNSigAllNodes" SG_ 866 StBltTgtCrtSetVal 1;
BA_ "SignalLongName" SG_ 866 MotStBltUnblIO "Motorized Seat Belt Unavailable Indication On";
BA_ "SignalType" SG_ 866 MotStBltUnblIO "BLN";
BA_ "VNSigAllNodes" SG_ 866 MotStBltUnblIO 1;
BA_ "SignalLongName" SG_ 866 MotStBltFldIO "Motorized Seat Belt Failed Indication On";
BA_ "SignalType" SG_ 866 MotStBltFldIO "BLN";
BA_ "VNSigAllNodes" SG_ 866 MotStBltFldIO 1;
BA_ "SignalLongName" SG_ 567 ExtHlStrAssCsCrStVal "Extended Hill Start Assist Customization Current Setting Value";
BA_ "SignalType" SG_ 567 ExtHlStrAssCsCrStVal "ENM";
BA_ "VNSigAllNodes" SG_ 567 ExtHlStrAssCsCrStVal 1;
BA_ "SignalLongName" SG_ 567 ExtHlStrAssCsStAvl "Extended Hill Start Assist Customization Setting Available";
BA_ "SignalType" SG_ 567 ExtHlStrAssCsStAvl "BLN";
BA_ "VNSigAllNodes" SG_ 567 ExtHlStrAssCsStAvl 1;
BA_ "SignalLongName" SG_ 567 DrvStyPerfMdCsCrStVal "Driving Style Performance Mode Customization Current Setting Value";
BA_ "SignalType" SG_ 567 DrvStyPerfMdCsCrStVal "ENM";
BA_ "VNSigAllNodes" SG_ 567 DrvStyPerfMdCsCrStVal 1;
BA_ "SignalLongName" SG_ 567 DrvStyPerfMdCsStAvl "Driving Style Performance Mode Customization Setting Available";
BA_ "SignalType" SG_ 567 DrvStyPerfMdCsStAvl "BLN";
BA_ "VNSigAllNodes" SG_ 567 DrvStyPerfMdCsStAvl 1;
BA_ "SignalLongName" SG_ 567 PsngStPerfMdCsCrStVal "Passenger Seat Performance Mode Customization Current Setting Value";
BA_ "SignalType" SG_ 567 PsngStPerfMdCsCrStVal "ENM";
BA_ "VNSigAllNodes" SG_ 567 PsngStPerfMdCsCrStVal 1;
BA_ "SignalLongName" SG_ 567 PsngStPerfMdCsStAvl "Passenger Seat Performance Mode Customization Setting Available";
BA_ "SignalType" SG_ 567 PsngStPerfMdCsStAvl "BLN";
BA_ "VNSigAllNodes" SG_ 567 PsngStPerfMdCsStAvl 1;
BA_ "SignalLongName" SG_ 567 DrvrStPerfMdCsCrStVal "Driver Seat Performance Mode Customization Current Setting Value";
BA_ "SignalType" SG_ 567 DrvrStPerfMdCsCrStVal "ENM";
BA_ "VNSigAllNodes" SG_ 567 DrvrStPerfMdCsCrStVal 1;
BA_ "SignalLongName" SG_ 567 DrvrStPerfMdCsStAvl "Driver Seat Performance Mode Customization Setting Available";
BA_ "SignalType" SG_ 567 DrvrStPerfMdCsStAvl "BLN";
BA_ "VNSigAllNodes" SG_ 567 DrvrStPerfMdCsStAvl 1;
BA_ "SignalLongName" SG_ 567 ACCPerfMdCsCrStVal "Adaptive Cruise Control Performance Mode Customization Current Setting Value";
BA_ "SignalType" SG_ 567 ACCPerfMdCsCrStVal "ENM";
BA_ "VNSigAllNodes" SG_ 567 ACCPerfMdCsCrStVal 1;
BA_ "SignalLongName" SG_ 567 ACCPerfMdCsStAvl "Adaptive Cruise Control Performance Mode Customization Setting Available";
BA_ "SignalType" SG_ 567 ACCPerfMdCsStAvl "BLN";
BA_ "VNSigAllNodes" SG_ 567 ACCPerfMdCsStAvl 1;
BA_ "SignalLongName" SG_ 372 ARSActAngStsRegtChksm "Active Rear Steer Actual Angle Status Regenerated state0589";
BA_ "SignalType" SG_ 372 ARSActAngStsRegtChksm "UNM";
BA_ "VNSigAllNodes" SG_ 372 ARSActAngStsRegtChksm 1;
BA_ "SignalLongName" SG_ 372 ARSActAngRegtARC "Active Rear Steer Actual Angle Regenerated Alive Rolling Count";
BA_ "SignalType" SG_ 372 ARSActAngRegtARC "UNM";
BA_ "VNSigAllNodes" SG_ 372 ARSActAngRegtARC 1;
BA_ "SignalLongName" SG_ 372 ARSOpStat "Active Rear Steer Operational Status";
BA_ "SignalType" SG_ 372 ARSOpStat "ENM";
BA_ "VNSigAllNodes" SG_ 372 ARSOpStat 1;
BA_ "SignalLongName" SG_ 372 ARSAlgmtCmplt "Active Rear Steer Alignment Complete";
BA_ "SignalType" SG_ 372 ARSAlgmtCmplt "BLN";
BA_ "VNSigAllNodes" SG_ 372 ARSAlgmtCmplt 1;
BA_ "SignalLongName" SG_ 372 ARSActAnglV "Active Rear Steer Actual Angle Validity";
BA_ "SignalType" SG_ 372 ARSActAnglV "ENM";
BA_ "VNSigAllNodes" SG_ 372 ARSActAnglV 1;
BA_ "SignalLongName" SG_ 372 ARSActAngl "Active Rear Steer Actual Angle";
BA_ "SignalType" SG_ 372 ARSActAngl "SNM";
BA_ "VNSigAllNodes" SG_ 372 ARSActAngl 1;
BA_ "SignalLongName" SG_ 372 ARSFlrIO "Active Rear Steer Failure Indication On";
BA_ "SignalType" SG_ 372 ARSFlrIO "BLN";
BA_ "VNSigAllNodes" SG_ 372 ARSFlrIO 1;
BA_REL_ "GenSigTimeoutTime" BU_SG_REL_ EBCM_OBD_HS SG_ 1034 CRL_Cnfdnc 250;
BA_REL_ "GenSigTimeoutMsg" BU_SG_REL_ EBCM_OBD_HS SG_ 1034 CRL_Cnfdnc 1034;
BA_REL_ "GenSigSuprvResp" BU_SG_REL_ EBCM_OBD_HS SG_ 1034 CRL_Cnfdnc 1;
BA_REL_ "GenSigTimeoutTime" BU_SG_REL_ EBCM_HS SG_ 1034 CRL_Cnfdnc 250;
BA_REL_ "GenSigTimeoutMsg" BU_SG_REL_ EBCM_HS SG_ 1034 CRL_Cnfdnc 1034;
BA_REL_ "GenSigSuprvResp" BU_SG_REL_ EBCM_HS SG_ 1034 CRL_Cnfdnc 1;
BA_REL_ "GenSigTimeoutTime" BU_SG_REL_ EBCM_OBD_HS SG_ 1034 CRL_ViewRng 250;
BA_REL_ "GenSigTimeoutMsg" BU_SG_REL_ EBCM_OBD_HS SG_ 1034 CRL_ViewRng 1034;
BA_REL_ "GenSigSuprvResp" BU_SG_REL_ EBCM_OBD_HS SG_ 1034 CRL_ViewRng 1;
BA_REL_ "GenSigTimeoutTime" BU_SG_REL_ EBCM_HS SG_ 1034 CRL_ViewRng 250;
BA_REL_ "GenSigTimeoutMsg" BU_SG_REL_ EBCM_HS SG_ 1034 CRL_ViewRng 1034;
BA_REL_ "GenSigSuprvResp" BU_SG_REL_ EBCM_HS SG_ 1034 CRL_ViewRng 1;
BA_REL_ "GenSigTimeoutTime" BU_SG_REL_ EBCM_OBD_HS SG_ 1034 CRL_CoefdA 250;
BA_REL_ "GenSigTimeoutMsg" BU_SG_REL_ EBCM_OBD_HS SG_ 1034 CRL_CoefdA 1034;
BA_REL_ "GenSigSuprvResp" BU_SG_REL_ EBCM_OBD_HS SG_ 1034 CRL_CoefdA 1;
BA_REL_ "GenSigTimeoutTime" BU_SG_REL_ EBCM_HS SG_ 1034 CRL_CoefdA 250;
BA_REL_ "GenSigTimeoutMsg" BU_SG_REL_ EBCM_HS SG_ 1034 CRL_CoefdA 1034;
BA_REL_ "GenSigSuprvResp" BU_SG_REL_ EBCM_HS SG_ 1034 CRL_CoefdA 1;
BA_REL_ "GenSigTimeoutTime" BU_SG_REL_ EBCM_OBD_HS SG_ 1034 CRL_CoefA 250;
BA_REL_ "GenSigTimeoutMsg" BU_SG_REL_ EBCM_OBD_HS SG_ 1034 CRL_CoefA 1034;
BA_REL_ "GenSigSuprvResp" BU_SG_REL_ EBCM_OBD_HS SG_ 1034 CRL_CoefA 1;
BA_REL_ "GenSigTimeoutTime" BU_SG_REL_ EBCM_HS SG_ 1034 CRL_CoefA 250;
BA_REL_ "GenSigTimeoutMsg" BU_SG_REL_ EBCM_HS SG_ 1034 CRL_CoefA 1034;
BA_REL_ "GenSigSuprvResp" BU_SG_REL_ EBCM_HS SG_ 1034 CRL_CoefA 1;
BA_REL_ "GenSigTimeoutTime" BU_SG_REL_ EBCM_OBD_HS SG_ 1033 CLL_Cnfdnc 250;
BA_REL_ "GenSigTimeoutMsg" BU_SG_REL_ EBCM_OBD_HS SG_ 1033 CLL_Cnfdnc 1033;
BA_REL_ "GenSigSuprvResp" BU_SG_REL_ EBCM_OBD_HS SG_ 1033 CLL_Cnfdnc 1;
BA_REL_ "GenSigTimeoutTime" BU_SG_REL_ EBCM_HS SG_ 1033 CLL_Cnfdnc 250;
BA_REL_ "GenSigTimeoutMsg" BU_SG_REL_ EBCM_HS SG_ 1033 CLL_Cnfdnc 1033;
BA_REL_ "GenSigSuprvResp" BU_SG_REL_ EBCM_HS SG_ 1033 CLL_Cnfdnc 1;
BA_REL_ "GenSigTimeoutTime" BU_SG_REL_ EBCM_OBD_HS SG_ 1033 CLL_ViewRng 250;
BA_REL_ "GenSigTimeoutMsg" BU_SG_REL_ EBCM_OBD_HS SG_ 1033 CLL_ViewRng 1033;
BA_REL_ "GenSigSuprvResp" BU_SG_REL_ EBCM_OBD_HS SG_ 1033 CLL_ViewRng 1;
BA_REL_ "GenSigTimeoutTime" BU_SG_REL_ EBCM_HS SG_ 1033 CLL_ViewRng 250;
BA_REL_ "GenSigTimeoutMsg" BU_SG_REL_ EBCM_HS SG_ 1033 CLL_ViewRng 1033;
BA_REL_ "GenSigSuprvResp" BU_SG_REL_ EBCM_HS SG_ 1033 CLL_ViewRng 1;
BA_REL_ "GenSigTimeoutTime" BU_SG_REL_ EBCM_OBD_HS SG_ 1033 CLL_CoefdA 250;
BA_REL_ "GenSigTimeoutMsg" BU_SG_REL_ EBCM_OBD_HS SG_ 1033 CLL_CoefdA 1033;
BA_REL_ "GenSigSuprvResp" BU_SG_REL_ EBCM_OBD_HS SG_ 1033 CLL_CoefdA 1;
BA_REL_ "GenSigTimeoutTime" BU_SG_REL_ EBCM_HS SG_ 1033 CLL_CoefdA 250;
BA_REL_ "GenSigTimeoutMsg" BU_SG_REL_ EBCM_HS SG_ 1033 CLL_CoefdA 1033;
BA_REL_ "GenSigSuprvResp" BU_SG_REL_ EBCM_HS SG_ 1033 CLL_CoefdA 1;
BA_REL_ "GenSigTimeoutTime" BU_SG_REL_ EBCM_OBD_HS SG_ 1033 CLL_CoefA 250;
BA_REL_ "GenSigTimeoutMsg" BU_SG_REL_ EBCM_OBD_HS SG_ 1033 CLL_CoefA 1033;
BA_REL_ "GenSigSuprvResp" BU_SG_REL_ EBCM_OBD_HS SG_ 1033 CLL_CoefA 1;
BA_REL_ "GenSigTimeoutTime" BU_SG_REL_ EBCM_HS SG_ 1033 CLL_CoefA 250;
BA_REL_ "GenSigTimeoutMsg" BU_SG_REL_ EBCM_HS SG_ 1033 CLL_CoefA 1033;
BA_REL_ "GenSigSuprvResp" BU_SG_REL_ EBCM_HS SG_ 1033 CLL_CoefA 1;
BA_REL_ "GenSigTimeoutTime" BU_SG_REL_ EBCM_OBD_HS SG_ 800 FCACtrlBrkSysCmdPrtVl 250;
BA_REL_ "GenSigTimeoutMsg" BU_SG_REL_ EBCM_OBD_HS SG_ 800 FCACtrlBrkSysCmdPrtVl 800;
BA_REL_ "GenSigSuprvResp" BU_SG_REL_ EBCM_OBD_HS SG_ 800 FCACtrlBrkSysCmdPrtVl 1;
BA_REL_ "GenSigTimeoutTime" BU_SG_REL_ EBCM_HS SG_ 800 FCACtrlBrkSysCmdPrtVl 250;
BA_REL_ "GenSigTimeoutMsg" BU_SG_REL_ EBCM_HS SG_ 800 FCACtrlBrkSysCmdPrtVl 800;
BA_REL_ "GenSigSuprvResp" BU_SG_REL_ EBCM_HS SG_ 800 FCACtrlBrkSysCmdPrtVl 1;
BA_REL_ "GenSigTimeoutTime" BU_SG_REL_ EBCM_OBD_HS SG_ 800 FCACBSC_CtrlAcc 250;
BA_REL_ "GenSigTimeoutMsg" BU_SG_REL_ EBCM_OBD_HS SG_ 800 FCACBSC_CtrlAcc 800;
BA_REL_ "GenSigSuprvResp" BU_SG_REL_ EBCM_OBD_HS SG_ 800 FCACBSC_CtrlAcc 1;
BA_REL_ "GenSigTimeoutTime" BU_SG_REL_ EBCM_HS SG_ 800 FCACBSC_CtrlAcc 250;
BA_REL_ "GenSigTimeoutMsg" BU_SG_REL_ EBCM_HS SG_ 800 FCACBSC_CtrlAcc 800;
BA_REL_ "GenSigSuprvResp" BU_SG_REL_ EBCM_HS SG_ 800 FCACBSC_CtrlAcc 1;
BA_REL_ "GenSigTimeoutTime" BU_SG_REL_ EBCM_OBD_HS SG_ 800 FCACBSC_AutBrkRpRt 250;
BA_REL_ "GenSigTimeoutMsg" BU_SG_REL_ EBCM_OBD_HS SG_ 800 FCACBSC_AutBrkRpRt 800;
BA_REL_ "GenSigSuprvResp" BU_SG_REL_ EBCM_OBD_HS SG_ 800 FCACBSC_AutBrkRpRt 1;
BA_REL_ "GenSigTimeoutTime" BU_SG_REL_ EBCM_HS SG_ 800 FCACBSC_AutBrkRpRt 250;
BA_REL_ "GenSigTimeoutMsg" BU_SG_REL_ EBCM_HS SG_ 800 FCACBSC_AutBrkRpRt 800;
BA_REL_ "GenSigSuprvResp" BU_SG_REL_ EBCM_HS SG_ 800 FCACBSC_AutBrkRpRt 1;
BA_REL_ "GenSigTimeoutTime" BU_SG_REL_ EBCM_OBD_HS SG_ 800 FCACBSC_AutBrkRqTp 250;
BA_REL_ "GenSigTimeoutMsg" BU_SG_REL_ EBCM_OBD_HS SG_ 800 FCACBSC_AutBrkRqTp 800;
BA_REL_ "GenSigSuprvResp" BU_SG_REL_ EBCM_OBD_HS SG_ 800 FCACBSC_AutBrkRqTp 1;
BA_REL_ "GenSigTimeoutTime" BU_SG_REL_ EBCM_HS SG_ 800 FCACBSC_AutBrkRqTp 250;
BA_REL_ "GenSigTimeoutMsg" BU_SG_REL_ EBCM_HS SG_ 800 FCACBSC_AutBrkRqTp 800;
BA_REL_ "GenSigSuprvResp" BU_SG_REL_ EBCM_HS SG_ 800 FCACBSC_AutBrkRqTp 1;
BA_REL_ "GenSigTimeoutTime" BU_SG_REL_ EBCM_OBD_HS SG_ 800 FCACBSC_AutBrkRqd 250;
BA_REL_ "GenSigTimeoutMsg" BU_SG_REL_ EBCM_OBD_HS SG_ 800 FCACBSC_AutBrkRqd 800;
BA_REL_ "GenSigSuprvResp" BU_SG_REL_ EBCM_OBD_HS SG_ 800 FCACBSC_AutBrkRqd 1;
BA_REL_ "GenSigTimeoutTime" BU_SG_REL_ EBCM_HS SG_ 800 FCACBSC_AutBrkRqd 250;
BA_REL_ "GenSigTimeoutMsg" BU_SG_REL_ EBCM_HS SG_ 800 FCACBSC_AutBrkRqd 800;
BA_REL_ "GenSigSuprvResp" BU_SG_REL_ EBCM_HS SG_ 800 FCACBSC_AutBrkRqd 1;
BA_REL_ "GenSigTimeoutTime" BU_SG_REL_ EBCM_OBD_HS SG_ 800 FCACtrlBrkSysCmdRC 250;
BA_REL_ "GenSigTimeoutMsg" BU_SG_REL_ EBCM_OBD_HS SG_ 800 FCACtrlBrkSysCmdRC 800;
BA_REL_ "GenSigSuprvResp" BU_SG_REL_ EBCM_OBD_HS SG_ 800 FCACtrlBrkSysCmdRC 1;
BA_REL_ "GenSigTimeoutTime" BU_SG_REL_ EBCM_HS SG_ 800 FCACtrlBrkSysCmdRC 250;
BA_REL_ "GenSigTimeoutMsg" BU_SG_REL_ EBCM_HS SG_ 800 FCACtrlBrkSysCmdRC 800;
BA_REL_ "GenSigSuprvResp" BU_SG_REL_ EBCM_HS SG_ 800 FCACtrlBrkSysCmdRC 1;
BA_REL_ "GenSigTimeoutTime" BU_SG_REL_ EBCM_OBD_HS SG_ 554 PrtdEPBSwStat 250;
BA_REL_ "GenSigTimeoutMsg" BU_SG_REL_ EBCM_OBD_HS SG_ 554 PrtdEPBSwStat 554;
BA_REL_ "GenSigSuprvResp" BU_SG_REL_ EBCM_OBD_HS SG_ 554 PrtdEPBSwStat 1;
BA_REL_ "GenSigTimeoutTime" BU_SG_REL_ EBCM_HS SG_ 554 PrtdEPBSwStat 250;
BA_REL_ "GenSigTimeoutMsg" BU_SG_REL_ EBCM_HS SG_ 554 PrtdEPBSwStat 554;
BA_REL_ "GenSigSuprvResp" BU_SG_REL_ EBCM_HS SG_ 554 PrtdEPBSwStat 1;
BA_REL_ "GenSigTimeoutTime" BU_SG_REL_ CGM_HS SG_ 801 WhlBdySnsHmPosLrnd 250;
BA_REL_ "GenSigTimeoutMsg" BU_SG_REL_ CGM_HS SG_ 801 WhlBdySnsHmPosLrnd 801;
BA_REL_ "GenSigSuprvResp" BU_SG_REL_ CGM_HS SG_ 801 WhlBdySnsHmPosLrnd 1;
BA_REL_ "GenSigTimeoutTime" BU_SG_REL_ CGM_HS SG_ 801 WBRP_ARC 250;
BA_REL_ "GenSigTimeoutMsg" BU_SG_REL_ CGM_HS SG_ 801 WBRP_ARC 801;
BA_REL_ "GenSigSuprvResp" BU_SG_REL_ CGM_HS SG_ 801 WBRP_ARC 1;
BA_REL_ "GenSigTimeoutTime" BU_SG_REL_ CGM_HS SG_ 801 WBRP_Tmestmp 250;
BA_REL_ "GenSigTimeoutMsg" BU_SG_REL_ CGM_HS SG_ 801 WBRP_Tmestmp 801;
BA_REL_ "GenSigSuprvResp" BU_SG_REL_ CGM_HS SG_ 801 WBRP_Tmestmp 1;
BA_REL_ "GenSigTimeoutTime" BU_SG_REL_ CGM_HS SG_ 801 WBRP_RtFrtV 250;
BA_REL_ "GenSigTimeoutMsg" BU_SG_REL_ CGM_HS SG_ 801 WBRP_RtFrtV 801;
BA_REL_ "GenSigSuprvResp" BU_SG_REL_ CGM_HS SG_ 801 WBRP_RtFrtV 1;
BA_REL_ "GenSigTimeoutTime" BU_SG_REL_ CGM_HS SG_ 801 WBRP_RtFrt 250;
BA_REL_ "GenSigTimeoutMsg" BU_SG_REL_ CGM_HS SG_ 801 WBRP_RtFrt 801;
BA_REL_ "GenSigSuprvResp" BU_SG_REL_ CGM_HS SG_ 801 WBRP_RtFrt 1;
BA_REL_ "GenSigTimeoutTime" BU_SG_REL_ CGM_HS SG_ 801 WBRP_RtRrV 250;
BA_REL_ "GenSigTimeoutMsg" BU_SG_REL_ CGM_HS SG_ 801 WBRP_RtRrV 801;
BA_REL_ "GenSigSuprvResp" BU_SG_REL_ CGM_HS SG_ 801 WBRP_RtRrV 1;
BA_REL_ "GenSigTimeoutTime" BU_SG_REL_ CGM_HS SG_ 801 WBRP_RtRr 250;
BA_REL_ "GenSigTimeoutMsg" BU_SG_REL_ CGM_HS SG_ 801 WBRP_RtRr 801;
BA_REL_ "GenSigSuprvResp" BU_SG_REL_ CGM_HS SG_ 801 WBRP_RtRr 1;
BA_REL_ "GenSigTimeoutTime" BU_SG_REL_ CGM_HS SG_ 801 WBRP_LftRrV 250;
BA_REL_ "GenSigTimeoutMsg" BU_SG_REL_ CGM_HS SG_ 801 WBRP_LftRrV 801;
BA_REL_ "GenSigSuprvResp" BU_SG_REL_ CGM_HS SG_ 801 WBRP_LftRrV 1;
BA_REL_ "GenSigTimeoutTime" BU_SG_REL_ CGM_HS SG_ 801 WBRP_LftRr 250;
BA_REL_ "GenSigTimeoutMsg" BU_SG_REL_ CGM_HS SG_ 801 WBRP_LftRr 801;
BA_REL_ "GenSigSuprvResp" BU_SG_REL_ CGM_HS SG_ 801 WBRP_LftRr 1;
BA_REL_ "GenSigTimeoutTime" BU_SG_REL_ CGM_HS SG_ 801 WBRP_LftFrtV 250;
BA_REL_ "GenSigTimeoutMsg" BU_SG_REL_ CGM_HS SG_ 801 WBRP_LftFrtV 801;
BA_REL_ "GenSigSuprvResp" BU_SG_REL_ CGM_HS SG_ 801 WBRP_LftFrtV 1;
BA_REL_ "GenSigTimeoutTime" BU_SG_REL_ CGM_HS SG_ 801 WBRP_LftFrt 250;
BA_REL_ "GenSigTimeoutMsg" BU_SG_REL_ CGM_HS SG_ 801 WBRP_LftFrt 801;
BA_REL_ "GenSigSuprvResp" BU_SG_REL_ CGM_HS SG_ 801 WBRP_LftFrt 1;
BA_REL_ "GenSigTimeoutTime" BU_SG_REL_ CGM_HS SG_ 844 IMUProtYawRt 250;
BA_REL_ "GenSigTimeoutMsg" BU_SG_REL_ CGM_HS SG_ 844 IMUProtYawRt 844;
BA_REL_ "GenSigSuprvResp" BU_SG_REL_ CGM_HS SG_ 844 IMUProtYawRt 1;
BA_REL_ "GenSigTimeoutTime" BU_SG_REL_ EPS_HS SG_ 844 IMUProtYawRt 250;
BA_REL_ "GenSigTimeoutMsg" BU_SG_REL_ EPS_HS SG_ 844 IMUProtYawRt 844;
BA_REL_ "GenSigSuprvResp" BU_SG_REL_ EPS_HS SG_ 844 IMUProtYawRt 1;
BA_REL_ "GenSigTimeoutTime" BU_SG_REL_ CGM_HS SG_ 844 IMUProtLonAcc 250;
BA_REL_ "GenSigTimeoutMsg" BU_SG_REL_ CGM_HS SG_ 844 IMUProtLonAcc 844;
BA_REL_ "GenSigSuprvResp" BU_SG_REL_ CGM_HS SG_ 844 IMUProtLonAcc 1;
BA_REL_ "GenSigTimeoutTime" BU_SG_REL_ EPS_HS SG_ 844 IMUProtLonAcc 250;
BA_REL_ "GenSigTimeoutMsg" BU_SG_REL_ EPS_HS SG_ 844 IMUProtLonAcc 844;
BA_REL_ "GenSigSuprvResp" BU_SG_REL_ EPS_HS SG_ 844 IMUProtLonAcc 1;
BA_REL_ "GenSigTimeoutTime" BU_SG_REL_ CGM_HS SG_ 844 IMUProtLatAcc 250;
BA_REL_ "GenSigTimeoutMsg" BU_SG_REL_ CGM_HS SG_ 844 IMUProtLatAcc 844;
BA_REL_ "GenSigSuprvResp" BU_SG_REL_ CGM_HS SG_ 844 IMUProtLatAcc 1;
BA_REL_ "GenSigTimeoutTime" BU_SG_REL_ EPS_HS SG_ 844 IMUProtLatAcc 250;
BA_REL_ "GenSigTimeoutMsg" BU_SG_REL_ EPS_HS SG_ 844 IMUProtLatAcc 844;
BA_REL_ "GenSigSuprvResp" BU_SG_REL_ EPS_HS SG_ 844 IMUProtLatAcc 1;
BA_REL_ "GenSigTimeoutTime" BU_SG_REL_ EPS_HS SG_ 844 IMUProtChksum 250;
BA_REL_ "GenSigTimeoutMsg" BU_SG_REL_ EPS_HS SG_ 844 IMUProtChksum 844;
BA_REL_ "GenSigSuprvResp" BU_SG_REL_ EPS_HS SG_ 844 IMUProtChksum 1;
BA_REL_ "GenSigTimeoutTime" BU_SG_REL_ EPS_HS SG_ 844 IMUProtARC 250;
BA_REL_ "GenSigTimeoutMsg" BU_SG_REL_ EPS_HS SG_ 844 IMUProtARC 844;
BA_REL_ "GenSigSuprvResp" BU_SG_REL_ EPS_HS SG_ 844 IMUProtARC 1;
BA_REL_ "GenSigTimeoutTime" BU_SG_REL_ ICCM_OBD_HS SG_ 528 BrkSysAutBrkReqRC 250;
BA_REL_ "GenSigTimeoutMsg" BU_SG_REL_ ICCM_OBD_HS SG_ 528 BrkSysAutBrkReqRC 528;
BA_REL_ "GenSigSuprvResp" BU_SG_REL_ ICCM_OBD_HS SG_ 528 BrkSysAutBrkReqRC 1;
BA_REL_ "GenSigTimeoutTime" BU_SG_REL_ ICCM_HS SG_ 528 BrkSysAutBrkReqRC 250;
BA_REL_ "GenSigTimeoutMsg" BU_SG_REL_ ICCM_HS SG_ 528 BrkSysAutBrkReqRC 528;
BA_REL_ "GenSigSuprvResp" BU_SG_REL_ ICCM_HS SG_ 528 BrkSysAutBrkReqRC 1;
BA_REL_ "GenSigTimeoutTime" BU_SG_REL_ ICCM_OBD_HS SG_ 528 BrkSysAutBrkReqPVal 250;
BA_REL_ "GenSigTimeoutMsg" BU_SG_REL_ ICCM_OBD_HS SG_ 528 BrkSysAutBrkReqPVal 528;
BA_REL_ "GenSigSuprvResp" BU_SG_REL_ ICCM_OBD_HS SG_ 528 BrkSysAutBrkReqPVal 1;
BA_REL_ "GenSigTimeoutTime" BU_SG_REL_ ICCM_HS SG_ 528 BrkSysAutBrkReqPVal 250;
BA_REL_ "GenSigTimeoutMsg" BU_SG_REL_ ICCM_HS SG_ 528 BrkSysAutBrkReqPVal 528;
BA_REL_ "GenSigSuprvResp" BU_SG_REL_ ICCM_HS SG_ 528 BrkSysAutBrkReqPVal 1;
BA_REL_ "GenSigTimeoutTime" BU_SG_REL_ ICCM_OBD_HS SG_ 528 BSABR_TrlBrkRq 250;
BA_REL_ "GenSigTimeoutMsg" BU_SG_REL_ ICCM_OBD_HS SG_ 528 BSABR_TrlBrkRq 528;
BA_REL_ "GenSigSuprvResp" BU_SG_REL_ ICCM_OBD_HS SG_ 528 BSABR_TrlBrkRq 1;
BA_REL_ "GenSigTimeoutTime" BU_SG_REL_ ICCM_HS SG_ 528 BSABR_TrlBrkRq 250;
BA_REL_ "GenSigTimeoutMsg" BU_SG_REL_ ICCM_HS SG_ 528 BSABR_TrlBrkRq 528;
BA_REL_ "GenSigSuprvResp" BU_SG_REL_ ICCM_HS SG_ 528 BSABR_TrlBrkRq 1;
BA_REL_ "GenSigTimeoutTime" BU_SG_REL_ ICCM_OBD_HS SG_ 528 BSABR_TrlBrkCntlIntRq 250;
BA_REL_ "GenSigTimeoutMsg" BU_SG_REL_ ICCM_OBD_HS SG_ 528 BSABR_TrlBrkCntlIntRq 528;
BA_REL_ "GenSigSuprvResp" BU_SG_REL_ ICCM_OBD_HS SG_ 528 BSABR_TrlBrkCntlIntRq 1;
BA_REL_ "GenSigTimeoutTime" BU_SG_REL_ ICCM_HS SG_ 528 BSABR_TrlBrkCntlIntRq 250;
BA_REL_ "GenSigTimeoutMsg" BU_SG_REL_ ICCM_HS SG_ 528 BSABR_TrlBrkCntlIntRq 528;
BA_REL_ "GenSigSuprvResp" BU_SG_REL_ ICCM_HS SG_ 528 BSABR_TrlBrkCntlIntRq 1;
BA_REL_ "GenSigTimeoutTime" BU_SG_REL_ TCCM_HS SG_ 462 SecAxlLkTqRqCplRqTp 250;
BA_REL_ "GenSigTimeoutMsg" BU_SG_REL_ TCCM_HS SG_ 462 SecAxlLkTqRqCplRqTp 462;
BA_REL_ "GenSigSuprvResp" BU_SG_REL_ TCCM_HS SG_ 462 SecAxlLkTqRqCplRqTp 1;
BA_REL_ "GenSigTimeoutTime" BU_SG_REL_ TCCM_HS SG_ 462 SATRCplReqVal 250;
BA_REL_ "GenSigTimeoutMsg" BU_SG_REL_ TCCM_HS SG_ 462 SATRCplReqVal 462;
BA_REL_ "GenSigSuprvResp" BU_SG_REL_ TCCM_HS SG_ 462 SATRCplReqVal 1;
BA_REL_ "GenSigTimeoutTime" BU_SG_REL_ TCCM_HS SG_ 462 SATRCplReqAtv 250;
BA_REL_ "GenSigTimeoutMsg" BU_SG_REL_ TCCM_HS SG_ 462 SATRCplReqAtv 462;
BA_REL_ "GenSigSuprvResp" BU_SG_REL_ TCCM_HS SG_ 462 SATRCplReqAtv 1;
BA_REL_ "GenSigTimeoutTime" BU_SG_REL_ BCM_HS SG_ 353 ElecShfRngDispRCExtd 250;
BA_REL_ "GenSigTimeoutMsg" BU_SG_REL_ BCM_HS SG_ 353 ElecShfRngDispRCExtd 353;
BA_REL_ "GenSigSuprvResp" BU_SG_REL_ BCM_HS SG_ 353 ElecShfRngDispRCExtd 1;
BA_REL_ "GenSigTimeoutTime" BU_SG_REL_ BCM_HS SG_ 353 ElecShfRngDisp 250;
BA_REL_ "GenSigTimeoutMsg" BU_SG_REL_ BCM_HS SG_ 353 ElecShfRngDisp 353;
BA_REL_ "GenSigSuprvResp" BU_SG_REL_ BCM_HS SG_ 353 ElecShfRngDisp 1;
BA_REL_ "GenSigTimeoutTime" BU_SG_REL_ BCM_HS SG_ 353 ESPTransMalfIO 250;
BA_REL_ "GenSigTimeoutMsg" BU_SG_REL_ BCM_HS SG_ 353 ESPTransMalfIO 353;
BA_REL_ "GenSigSuprvResp" BU_SG_REL_ BCM_HS SG_ 353 ESPTransMalfIO 1;
BA_REL_ "GenSigTimeoutTime" BU_SG_REL_ BCM_HS SG_ 353 ESPRngInvldReqIO 250;
BA_REL_ "GenSigTimeoutMsg" BU_SG_REL_ BCM_HS SG_ 353 ESPRngInvldReqIO 353;
BA_REL_ "GenSigSuprvResp" BU_SG_REL_ BCM_HS SG_ 353 ESPRngInvldReqIO 1;
BA_REL_ "GenSigTimeoutTime" BU_SG_REL_ BCM_HS SG_ 353 ESPPrkInvldReqIO 250;
BA_REL_ "GenSigTimeoutMsg" BU_SG_REL_ BCM_HS SG_ 353 ESPPrkInvldReqIO 353;
BA_REL_ "GenSigSuprvResp" BU_SG_REL_ BCM_HS SG_ 353 ESPPrkInvldReqIO 1;
BA_REL_ "GenSigTimeoutTime" BU_SG_REL_ BCM_HS SG_ 353 ESPHldShfLvrToEngRgIO 250;
BA_REL_ "GenSigTimeoutMsg" BU_SG_REL_ BCM_HS SG_ 353 ESPHldShfLvrToEngRgIO 353;
BA_REL_ "GenSigSuprvResp" BU_SG_REL_ BCM_HS SG_ 353 ESPHldShfLvrToEngRgIO 1;
BA_REL_ "GenSigTimeoutTime" BU_SG_REL_ BCM_HS SG_ 353 ESPDrvrPrkIlkSftAtdIO 250;
BA_REL_ "GenSigTimeoutMsg" BU_SG_REL_ BCM_HS SG_ 353 ESPDrvrPrkIlkSftAtdIO 353;
BA_REL_ "GenSigSuprvResp" BU_SG_REL_ BCM_HS SG_ 353 ESPDrvrPrkIlkSftAtdIO 1;
BA_REL_ "GenSigTimeoutTime" BU_SG_REL_ BCM_HS SG_ 353 ESPDrvrIlkShfAtdIO 250;
BA_REL_ "GenSigTimeoutMsg" BU_SG_REL_ BCM_HS SG_ 353 ESPDrvrIlkShfAtdIO 353;
BA_REL_ "GenSigSuprvResp" BU_SG_REL_ BCM_HS SG_ 353 ESPDrvrIlkShfAtdIO 1;
BA_REL_ "GenSigTimeoutTime" BU_SG_REL_ BCM_HS SG_ 563 SPMCA_SusPrfMd6Avl 5000;
BA_REL_ "GenSigTimeoutMsg" BU_SG_REL_ BCM_HS SG_ 563 SPMCA_SusPrfMd6Avl 563;
BA_REL_ "GenSigSuprvResp" BU_SG_REL_ BCM_HS SG_ 563 SPMCA_SusPrfMd6Avl 1;
BA_REL_ "GenSigTimeoutTime" BU_SG_REL_ BCM_HS SG_ 563 SPMCA_SusPrfMd5Avl 5000;
BA_REL_ "GenSigTimeoutMsg" BU_SG_REL_ BCM_HS SG_ 563 SPMCA_SusPrfMd5Avl 563;
BA_REL_ "GenSigSuprvResp" BU_SG_REL_ BCM_HS SG_ 563 SPMCA_SusPrfMd5Avl 1;
BA_REL_ "GenSigTimeoutTime" BU_SG_REL_ BCM_HS SG_ 563 SPMCA_SusPrfMd4Avl 5000;
BA_REL_ "GenSigTimeoutMsg" BU_SG_REL_ BCM_HS SG_ 563 SPMCA_SusPrfMd4Avl 563;
BA_REL_ "GenSigSuprvResp" BU_SG_REL_ BCM_HS SG_ 563 SPMCA_SusPrfMd4Avl 1;
BA_REL_ "GenSigTimeoutTime" BU_SG_REL_ BCM_HS SG_ 563 SPMCA_SusPrfMd3Avl 5000;
BA_REL_ "GenSigTimeoutMsg" BU_SG_REL_ BCM_HS SG_ 563 SPMCA_SusPrfMd3Avl 563;
BA_REL_ "GenSigSuprvResp" BU_SG_REL_ BCM_HS SG_ 563 SPMCA_SusPrfMd3Avl 1;
BA_REL_ "GenSigTimeoutTime" BU_SG_REL_ BCM_HS SG_ 563 SPMCA_SusPrfMd2Avl 5000;
BA_REL_ "GenSigTimeoutMsg" BU_SG_REL_ BCM_HS SG_ 563 SPMCA_SusPrfMd2Avl 563;
BA_REL_ "GenSigSuprvResp" BU_SG_REL_ BCM_HS SG_ 563 SPMCA_SusPrfMd2Avl 1;
BA_REL_ "GenSigTimeoutTime" BU_SG_REL_ BCM_HS SG_ 563 SPMCA_SusPrfMd1Avl 5000;
BA_REL_ "GenSigTimeoutMsg" BU_SG_REL_ BCM_HS SG_ 563 SPMCA_SusPrfMd1Avl 563;
BA_REL_ "GenSigSuprvResp" BU_SG_REL_ BCM_HS SG_ 563 SPMCA_SusPrfMd1Avl 1;
BA_REL_ "GenSigTimeoutTime" BU_SG_REL_ BCM_HS SG_ 563 SPMCA_StrPrfMd6Avl 5000;
BA_REL_ "GenSigTimeoutMsg" BU_SG_REL_ BCM_HS SG_ 563 SPMCA_StrPrfMd6Avl 563;
BA_REL_ "GenSigSuprvResp" BU_SG_REL_ BCM_HS SG_ 563 SPMCA_StrPrfMd6Avl 1;
BA_REL_ "GenSigTimeoutTime" BU_SG_REL_ BCM_HS SG_ 563 SPMCA_StrPrfMd5Avl 5000;
BA_REL_ "GenSigTimeoutMsg" BU_SG_REL_ BCM_HS SG_ 563 SPMCA_StrPrfMd5Avl 563;
BA_REL_ "GenSigSuprvResp" BU_SG_REL_ BCM_HS SG_ 563 SPMCA_StrPrfMd5Avl 1;
BA_REL_ "GenSigTimeoutTime" BU_SG_REL_ BCM_HS SG_ 563 SPMCA_StrPrfMd4Avl 5000;
BA_REL_ "GenSigTimeoutMsg" BU_SG_REL_ BCM_HS SG_ 563 SPMCA_StrPrfMd4Avl 563;
BA_REL_ "GenSigSuprvResp" BU_SG_REL_ BCM_HS SG_ 563 SPMCA_StrPrfMd4Avl 1;
BA_REL_ "GenSigTimeoutTime" BU_SG_REL_ BCM_HS SG_ 563 SPMCA_StrPrfMd3Avl 5000;
BA_REL_ "GenSigTimeoutMsg" BU_SG_REL_ BCM_HS SG_ 563 SPMCA_StrPrfMd3Avl 563;
BA_REL_ "GenSigSuprvResp" BU_SG_REL_ BCM_HS SG_ 563 SPMCA_StrPrfMd3Avl 1;
BA_REL_ "GenSigTimeoutTime" BU_SG_REL_ BCM_HS SG_ 563 SPMCA_StrPrfMd2Avl 5000;
BA_REL_ "GenSigTimeoutMsg" BU_SG_REL_ BCM_HS SG_ 563 SPMCA_StrPrfMd2Avl 563;
BA_REL_ "GenSigSuprvResp" BU_SG_REL_ BCM_HS SG_ 563 SPMCA_StrPrfMd2Avl 1;
BA_REL_ "GenSigTimeoutTime" BU_SG_REL_ BCM_HS SG_ 563 SPMCA_StrPrfMd1Avl 5000;
BA_REL_ "GenSigTimeoutMsg" BU_SG_REL_ BCM_HS SG_ 563 SPMCA_StrPrfMd1Avl 563;
BA_REL_ "GenSigSuprvResp" BU_SG_REL_ BCM_HS SG_ 563 SPMCA_StrPrfMd1Avl 1;
BA_REL_ "GenSigTimeoutTime" BU_SG_REL_ BCM_HS SG_ 563 SPMCA_SndPrfMd6Avl 5000;
BA_REL_ "GenSigTimeoutMsg" BU_SG_REL_ BCM_HS SG_ 563 SPMCA_SndPrfMd6Avl 563;
BA_REL_ "GenSigSuprvResp" BU_SG_REL_ BCM_HS SG_ 563 SPMCA_SndPrfMd6Avl 1;
BA_REL_ "GenSigTimeoutTime" BU_SG_REL_ BCM_HS SG_ 563 SPMCA_SndPrfMd5Avl 5000;
BA_REL_ "GenSigTimeoutMsg" BU_SG_REL_ BCM_HS SG_ 563 SPMCA_SndPrfMd5Avl 563;
BA_REL_ "GenSigSuprvResp" BU_SG_REL_ BCM_HS SG_ 563 SPMCA_SndPrfMd5Avl 1;
BA_REL_ "GenSigTimeoutTime" BU_SG_REL_ BCM_HS SG_ 563 SPMCA_SndPrfMd4Avl 5000;
BA_REL_ "GenSigTimeoutMsg" BU_SG_REL_ BCM_HS SG_ 563 SPMCA_SndPrfMd4Avl 563;
BA_REL_ "GenSigSuprvResp" BU_SG_REL_ BCM_HS SG_ 563 SPMCA_SndPrfMd4Avl 1;
BA_REL_ "GenSigTimeoutTime" BU_SG_REL_ BCM_HS SG_ 563 SPMCA_SndPrfMd3Avl 5000;
BA_REL_ "GenSigTimeoutMsg" BU_SG_REL_ BCM_HS SG_ 563 SPMCA_SndPrfMd3Avl 563;
BA_REL_ "GenSigSuprvResp" BU_SG_REL_ BCM_HS SG_ 563 SPMCA_SndPrfMd3Avl 1;
BA_REL_ "GenSigTimeoutTime" BU_SG_REL_ BCM_HS SG_ 563 SPMCA_SndPrfMd2Avl 5000;
BA_REL_ "GenSigTimeoutMsg" BU_SG_REL_ BCM_HS SG_ 563 SPMCA_SndPrfMd2Avl 563;
BA_REL_ "GenSigSuprvResp" BU_SG_REL_ BCM_HS SG_ 563 SPMCA_SndPrfMd2Avl 1;
BA_REL_ "GenSigTimeoutTime" BU_SG_REL_ BCM_HS SG_ 563 SPMCA_SndPrfMd1Avl 5000;
BA_REL_ "GenSigTimeoutMsg" BU_SG_REL_ BCM_HS SG_ 563 SPMCA_SndPrfMd1Avl 563;
BA_REL_ "GenSigSuprvResp" BU_SG_REL_ BCM_HS SG_ 563 SPMCA_SndPrfMd1Avl 1;
BA_REL_ "GenSigTimeoutTime" BU_SG_REL_ BCM_HS SG_ 563 DPMCA_DispPrfMd6Avl 5000;
BA_REL_ "GenSigTimeoutMsg" BU_SG_REL_ BCM_HS SG_ 563 DPMCA_DispPrfMd6Avl 563;
BA_REL_ "GenSigSuprvResp" BU_SG_REL_ BCM_HS SG_ 563 DPMCA_DispPrfMd6Avl 1;
BA_REL_ "GenSigTimeoutTime" BU_SG_REL_ BCM_HS SG_ 563 DPMCA_DispPrfMd5Avl 5000;
BA_REL_ "GenSigTimeoutMsg" BU_SG_REL_ BCM_HS SG_ 563 DPMCA_DispPrfMd5Avl 563;
BA_REL_ "GenSigSuprvResp" BU_SG_REL_ BCM_HS SG_ 563 DPMCA_DispPrfMd5Avl 1;
BA_REL_ "GenSigTimeoutTime" BU_SG_REL_ BCM_HS SG_ 563 DPMCA_DispPrfMd4Avl 5000;
BA_REL_ "GenSigTimeoutMsg" BU_SG_REL_ BCM_HS SG_ 563 DPMCA_DispPrfMd4Avl 563;
BA_REL_ "GenSigSuprvResp" BU_SG_REL_ BCM_HS SG_ 563 DPMCA_DispPrfMd4Avl 1;
BA_REL_ "GenSigTimeoutTime" BU_SG_REL_ BCM_HS SG_ 563 DPMCA_DispPrfMd3Avl 5000;
BA_REL_ "GenSigTimeoutMsg" BU_SG_REL_ BCM_HS SG_ 563 DPMCA_DispPrfMd3Avl 563;
BA_REL_ "GenSigSuprvResp" BU_SG_REL_ BCM_HS SG_ 563 DPMCA_DispPrfMd3Avl 1;
BA_REL_ "GenSigTimeoutTime" BU_SG_REL_ BCM_HS SG_ 563 DPMCA_DispPrfMd2Avl 5000;
BA_REL_ "GenSigTimeoutMsg" BU_SG_REL_ BCM_HS SG_ 563 DPMCA_DispPrfMd2Avl 563;
BA_REL_ "GenSigSuprvResp" BU_SG_REL_ BCM_HS SG_ 563 DPMCA_DispPrfMd2Avl 1;
BA_REL_ "GenSigTimeoutTime" BU_SG_REL_ BCM_HS SG_ 563 DPMCA_DispPrfMd1Avl 5000;
BA_REL_ "GenSigTimeoutMsg" BU_SG_REL_ BCM_HS SG_ 563 DPMCA_DispPrfMd1Avl 563;
BA_REL_ "GenSigSuprvResp" BU_SG_REL_ BCM_HS SG_ 563 DPMCA_DispPrfMd1Avl 1;
BA_REL_ "GenSigTimeoutTime" BU_SG_REL_ BCM_HS SG_ 563 DPMCA_DrvlPrfMd6Avl 5000;
BA_REL_ "GenSigTimeoutMsg" BU_SG_REL_ BCM_HS SG_ 563 DPMCA_DrvlPrfMd6Avl 563;
BA_REL_ "GenSigSuprvResp" BU_SG_REL_ BCM_HS SG_ 563 DPMCA_DrvlPrfMd6Avl 1;
BA_REL_ "GenSigTimeoutTime" BU_SG_REL_ BCM_HS SG_ 563 DPMCA_DrvlPrfMd5Avl 5000;
BA_REL_ "GenSigTimeoutMsg" BU_SG_REL_ BCM_HS SG_ 563 DPMCA_DrvlPrfMd5Avl 563;
BA_REL_ "GenSigSuprvResp" BU_SG_REL_ BCM_HS SG_ 563 DPMCA_DrvlPrfMd5Avl 1;
BA_REL_ "GenSigTimeoutTime" BU_SG_REL_ BCM_HS SG_ 563 DPMCA_DrvlPrfMd4Avl 5000;
BA_REL_ "GenSigTimeoutMsg" BU_SG_REL_ BCM_HS SG_ 563 DPMCA_DrvlPrfMd4Avl 563;
BA_REL_ "GenSigSuprvResp" BU_SG_REL_ BCM_HS SG_ 563 DPMCA_DrvlPrfMd4Avl 1;
BA_REL_ "GenSigTimeoutTime" BU_SG_REL_ BCM_HS SG_ 563 DPMCA_DrvlPrfMd3Avl 5000;
BA_REL_ "GenSigTimeoutMsg" BU_SG_REL_ BCM_HS SG_ 563 DPMCA_DrvlPrfMd3Avl 563;
BA_REL_ "GenSigSuprvResp" BU_SG_REL_ BCM_HS SG_ 563 DPMCA_DrvlPrfMd3Avl 1;
BA_REL_ "GenSigTimeoutTime" BU_SG_REL_ BCM_HS SG_ 563 DPMCA_DrvlPrfMd2Avl 5000;
BA_REL_ "GenSigTimeoutMsg" BU_SG_REL_ BCM_HS SG_ 563 DPMCA_DrvlPrfMd2Avl 563;
BA_REL_ "GenSigSuprvResp" BU_SG_REL_ BCM_HS SG_ 563 DPMCA_DrvlPrfMd2Avl 1;
BA_REL_ "GenSigTimeoutTime" BU_SG_REL_ BCM_HS SG_ 563 DPMCA_DrvlPrfMd1Avl 5000;
BA_REL_ "GenSigTimeoutMsg" BU_SG_REL_ BCM_HS SG_ 563 DPMCA_DrvlPrfMd1Avl 563;
BA_REL_ "GenSigSuprvResp" BU_SG_REL_ BCM_HS SG_ 563 DPMCA_DrvlPrfMd1Avl 1;
BA_REL_ "GenSigTimeoutTime" BU_SG_REL_ EPS_HS SG_ 384 LKATqOvrDltCmdPrtVl 250;
BA_REL_ "GenSigTimeoutMsg" BU_SG_REL_ EPS_HS SG_ 384 LKATqOvrDltCmdPrtVl 384;
BA_REL_ "GenSigSuprvResp" BU_SG_REL_ EPS_HS SG_ 384 LKATqOvrDltCmdPrtVl 1;
BA_REL_ "GenSigTimeoutTime" BU_SG_REL_ EPS_HS SG_ 384 LKATqOvrDltCmdRC 250;
BA_REL_ "GenSigTimeoutMsg" BU_SG_REL_ EPS_HS SG_ 384 LKATqOvrDltCmdRC 384;
BA_REL_ "GenSigSuprvResp" BU_SG_REL_ EPS_HS SG_ 384 LKATqOvrDltCmdRC 1;
BA_REL_ "GenSigTimeoutTime" BU_SG_REL_ EPS_HS SG_ 384 LKATODC_TrqVl 250;
BA_REL_ "GenSigTimeoutMsg" BU_SG_REL_ EPS_HS SG_ 384 LKATODC_TrqVl 384;
BA_REL_ "GenSigSuprvResp" BU_SG_REL_ EPS_HS SG_ 384 LKATODC_TrqVl 1;
BA_REL_ "GenSigTimeoutTime" BU_SG_REL_ BCM_HS SG_ 384 LKATODC_TrqVl 250;
BA_REL_ "GenSigTimeoutMsg" BU_SG_REL_ BCM_HS SG_ 384 LKATODC_TrqVl 384;
BA_REL_ "GenSigSuprvResp" BU_SG_REL_ BCM_HS SG_ 384 LKATODC_TrqVl 1;
BA_REL_ "GenSigTimeoutTime" BU_SG_REL_ EPS_HS SG_ 384 LKATODC_TrqRqAct 250;
BA_REL_ "GenSigTimeoutMsg" BU_SG_REL_ EPS_HS SG_ 384 LKATODC_TrqRqAct 384;
BA_REL_ "GenSigSuprvResp" BU_SG_REL_ EPS_HS SG_ 384 LKATODC_TrqRqAct 1;
BA_REL_ "GenSigTimeoutTime" BU_SG_REL_ BCM_HS SG_ 384 LKATODC_TrqRqAct 250;
BA_REL_ "GenSigTimeoutMsg" BU_SG_REL_ BCM_HS SG_ 384 LKATODC_TrqRqAct 384;
BA_REL_ "GenSigSuprvResp" BU_SG_REL_ BCM_HS SG_ 384 LKATODC_TrqRqAct 1;
BA_REL_ "GenSigTimeoutTime" BU_SG_REL_ BCM_HS SG_ 567 DrvStyPerfMdCsCrStVal 625;
BA_REL_ "GenSigTimeoutMsg" BU_SG_REL_ BCM_HS SG_ 567 DrvStyPerfMdCsCrStVal 567;
BA_REL_ "GenSigSuprvResp" BU_SG_REL_ BCM_HS SG_ 567 DrvStyPerfMdCsCrStVal 1;
BA_REL_ "GenSigTimeoutTime" BU_SG_REL_ BCM_HS SG_ 567 DrvStyPerfMdCsStAvl 625;
BA_REL_ "GenSigTimeoutMsg" BU_SG_REL_ BCM_HS SG_ 567 DrvStyPerfMdCsStAvl 567;
BA_REL_ "GenSigSuprvResp" BU_SG_REL_ BCM_HS SG_ 567 DrvStyPerfMdCsStAvl 1;
BA_REL_ "GenSigTimeoutTime" BU_SG_REL_ BCM_HS SG_ 567 PsngStPerfMdCsCrStVal 625;
BA_REL_ "GenSigTimeoutMsg" BU_SG_REL_ BCM_HS SG_ 567 PsngStPerfMdCsCrStVal 567;
BA_REL_ "GenSigSuprvResp" BU_SG_REL_ BCM_HS SG_ 567 PsngStPerfMdCsCrStVal 1;
BA_REL_ "GenSigTimeoutTime" BU_SG_REL_ BCM_HS SG_ 567 PsngStPerfMdCsStAvl 625;
BA_REL_ "GenSigTimeoutMsg" BU_SG_REL_ BCM_HS SG_ 567 PsngStPerfMdCsStAvl 567;
BA_REL_ "GenSigSuprvResp" BU_SG_REL_ BCM_HS SG_ 567 PsngStPerfMdCsStAvl 1;
BA_REL_ "GenSigTimeoutTime" BU_SG_REL_ BCM_HS SG_ 567 DrvrStPerfMdCsCrStVal 625;
BA_REL_ "GenSigTimeoutMsg" BU_SG_REL_ BCM_HS SG_ 567 DrvrStPerfMdCsCrStVal 567;
BA_REL_ "GenSigSuprvResp" BU_SG_REL_ BCM_HS SG_ 567 DrvrStPerfMdCsCrStVal 1;
BA_REL_ "GenSigTimeoutTime" BU_SG_REL_ BCM_HS SG_ 567 DrvrStPerfMdCsStAvl 625;
BA_REL_ "GenSigTimeoutMsg" BU_SG_REL_ BCM_HS SG_ 567 DrvrStPerfMdCsStAvl 567;
BA_REL_ "GenSigSuprvResp" BU_SG_REL_ BCM_HS SG_ 567 DrvrStPerfMdCsStAvl 1;
BA_REL_ "GenSigTimeoutTime" BU_SG_REL_ BCM_HS SG_ 567 ACCPerfMdCsCrStVal 625;
BA_REL_ "GenSigTimeoutMsg" BU_SG_REL_ BCM_HS SG_ 567 ACCPerfMdCsCrStVal 567;
BA_REL_ "GenSigSuprvResp" BU_SG_REL_ BCM_HS SG_ 567 ACCPerfMdCsCrStVal 1;
BA_REL_ "GenSigTimeoutTime" BU_SG_REL_ BCM_HS SG_ 567 ACCPerfMdCsStAvl 625;
BA_REL_ "GenSigTimeoutMsg" BU_SG_REL_ BCM_HS SG_ 567 ACCPerfMdCsStAvl 567;
BA_REL_ "GenSigSuprvResp" BU_SG_REL_ BCM_HS SG_ 567 ACCPerfMdCsStAvl 1;
VAL_ 1931 DTCI_CodeSupported_78B 1 "true" 0 "false" ;
VAL_ 1931 DTCI_CurrentStatus_78B 1 "true" 0 "false" ;
VAL_ 1931 DTCI_DTCFaultType_78B 3 "Type C" 2 "Type B" 1 "Type A" 0 "Not Supported" ;
VAL_ 1931 DTCI_DTCTriggered_78B 1 "true" 0 "false" ;
VAL_ 1931 DTCI_HistStat_78B 1 "true" 0 "false" ;
VAL_ 1931 DTCI_TstFldCdClrdStat_78B 1 "true" 0 "false" ;
VAL_ 1931 DTCI_TstFldPwrUpSt_78B 1 "true" 0 "false" ;
VAL_ 1931 DTCI_TstNPsdCdClrdSt_78B 1 "true" 0 "false" ;
VAL_ 1931 DTCI_TstNPsdPwrUpSt_78B 1 "true" 0 "false" ;
VAL_ 1931 DTCIUnused1_78B 1 "true" 0 "false" ;
VAL_ 1931 DTCIUnused2_78B 1 "true" 0 "false" ;
VAL_ 1931 DTCIUnused3_78B 1 "true" 0 "false" ;
VAL_ 1931 DTCIUnused4_78B 1 "true" 0 "false" ;
VAL_ 1931 DTCIUnused5_78B 1 "true" 0 "false" ;
VAL_ 1931 DTCIUnused6_78B 1 "true" 0 "false" ;
VAL_ 1931 DTCIUnused7_78B 1 "true" 0 "false" ;
VAL_ 1931 DTCI_WrnIndRqdSt_78B 1 "true" 0 "false" ;
VAL_ 1928 DTCI_CodeSupported_788 1 "true" 0 "false" ;
VAL_ 1928 DTCI_CurrentStatus_788 1 "true" 0 "false" ;
VAL_ 1928 DTCI_DTCFaultType_788 3 "Type C" 2 "Type B" 1 "Type A" 0 "Not Supported" ;
VAL_ 1928 DTCI_DTCTriggered_788 1 "true" 0 "false" ;
VAL_ 1928 DTCI_HistStat_788 1 "true" 0 "false" ;
VAL_ 1928 DTCI_TstFldCdClrdStat_788 1 "true" 0 "false" ;
VAL_ 1928 DTCI_TstFldPwrUpSt_788 1 "true" 0 "false" ;
VAL_ 1928 DTCI_TstNPsdCdClrdSt_788 1 "true" 0 "false" ;
VAL_ 1928 DTCI_TstNPsdPwrUpSt_788 1 "true" 0 "false" ;
VAL_ 1928 DTCIUnused1_788 1 "true" 0 "false" ;
VAL_ 1928 DTCIUnused2_788 1 "true" 0 "false" ;
VAL_ 1928 DTCIUnused3_788 1 "true" 0 "false" ;
VAL_ 1928 DTCIUnused4_788 1 "true" 0 "false" ;
VAL_ 1928 DTCIUnused5_788 1 "true" 0 "false" ;
VAL_ 1928 DTCIUnused6_788 1 "true" 0 "false" ;
VAL_ 1928 DTCIUnused7_788 1 "true" 0 "false" ;
VAL_ 1928 DTCI_WrnIndRqdSt_788 1 "true" 0 "false" ;
VAL_ 1925 DTCI_CodeSupported_785 1 "true" 0 "false" ;
VAL_ 1925 DTCI_CurrentStatus_785 1 "true" 0 "false" ;
VAL_ 1925 DTCI_DTCFaultType_785 3 "Type C" 2 "Type B" 1 "Type A" 0 "Not Supported" ;
VAL_ 1925 DTCI_DTCTriggered_785 1 "true" 0 "false" ;
VAL_ 1925 DTCI_HistStat_785 1 "true" 0 "false" ;
VAL_ 1925 DTCI_TstFldCdClrdStat_785 1 "true" 0 "false" ;
VAL_ 1925 DTCI_TstFldPwrUpSt_785 1 "true" 0 "false" ;
VAL_ 1925 DTCI_TstNPsdCdClrdSt_785 1 "true" 0 "false" ;
VAL_ 1925 DTCI_TstNPsdPwrUpSt_785 1 "true" 0 "false" ;
VAL_ 1925 DTCIUnused1_785 1 "true" 0 "false" ;
VAL_ 1925 DTCIUnused2_785 1 "true" 0 "false" ;
VAL_ 1925 DTCIUnused3_785 1 "true" 0 "false" ;
VAL_ 1925 DTCIUnused4_785 1 "true" 0 "false" ;
VAL_ 1925 DTCIUnused5_785 1 "true" 0 "false" ;
VAL_ 1925 DTCIUnused6_785 1 "true" 0 "false" ;
VAL_ 1925 DTCIUnused7_785 1 "true" 0 "false" ;
VAL_ 1925 DTCI_WrnIndRqdSt_785 1 "true" 0 "false" ;
VAL_ 1922 DTCI_WrnIndRqdSt_782 1 "true" 0 "false" ;
VAL_ 1922 DTCIUnused7_782 1 "true" 0 "false" ;
VAL_ 1922 DTCIUnused6_782 1 "true" 0 "false" ;
VAL_ 1922 DTCIUnused5_782 1 "true" 0 "false" ;
VAL_ 1922 DTCIUnused4_782 1 "true" 0 "false" ;
VAL_ 1922 DTCIUnused3_782 1 "true" 0 "false" ;
VAL_ 1922 DTCIUnused2_782 1 "true" 0 "false" ;
VAL_ 1922 DTCIUnused1_782 1 "true" 0 "false" ;
VAL_ 1922 DTCI_TstNPsdPwrUpSt_782 1 "true" 0 "false" ;
VAL_ 1922 DTCI_TstNPsdCdClrdSt_782 1 "true" 0 "false" ;
VAL_ 1922 DTCI_TstFldPwrUpSt_782 1 "true" 0 "false" ;
VAL_ 1922 DTCI_TstFldCdClrdStat_782 1 "true" 0 "false" ;
VAL_ 1922 DTCI_HistStat_782 1 "true" 0 "false" ;
VAL_ 1922 DTCI_DTCTriggered_782 1 "true" 0 "false" ;
VAL_ 1922 DTCI_DTCFaultType_782 3 "Type C" 2 "Type B" 1 "Type A" 0 "Not Supported" ;
VAL_ 1922 DTCI_CurrentStatus_782 1 "true" 0 "false" ;
VAL_ 1922 DTCI_CodeSupported_782 1 "true" 0 "false" ;
VAL_ 1904 DTCI_WrnIndRqdSt_770 1 "true" 0 "false" ;
VAL_ 1904 DTCIUnused7_770 1 "true" 0 "false" ;
VAL_ 1904 DTCIUnused6_770 1 "true" 0 "false" ;
VAL_ 1904 DTCIUnused5_770 1 "true" 0 "false" ;
VAL_ 1904 DTCIUnused4_770 1 "true" 0 "false" ;
VAL_ 1904 DTCIUnused3_770 1 "true" 0 "false" ;
VAL_ 1904 DTCIUnused2_770 1 "true" 0 "false" ;
VAL_ 1904 DTCIUnused1_770 1 "true" 0 "false" ;
VAL_ 1904 DTCI_TstNPsdPwrUpSt_770 1 "true" 0 "false" ;
VAL_ 1904 DTCI_TstNPsdCdClrdSt_770 1 "true" 0 "false" ;
VAL_ 1904 DTCI_TstFldPwrUpSt_770 1 "true" 0 "false" ;
VAL_ 1904 DTCI_TstFldCdClrdStat_770 1 "true" 0 "false" ;
VAL_ 1904 DTCI_HistStat_770 1 "true" 0 "false" ;
VAL_ 1904 DTCI_DTCTriggered_770 1 "true" 0 "false" ;
VAL_ 1904 DTCI_DTCFaultType_770 3 "Type C" 2 "Type B" 1 "Type A" 0 "Not Supported" ;
VAL_ 1904 DTCI_CurrentStatus_770 1 "true" 0 "false" ;
VAL_ 1904 DTCI_CodeSupported_770 1 "true" 0 "false" ;
VAL_ 1921 DTCI_CurrentStatus_781 1 "true" 0 "false" ;
VAL_ 1921 DTCI_WrnIndRqdSt_781 1 "true" 0 "false" ;
VAL_ 1921 DTCIUnused7_781 1 "true" 0 "false" ;
VAL_ 1921 DTCIUnused6_781 1 "true" 0 "false" ;
VAL_ 1921 DTCIUnused5_781 1 "true" 0 "false" ;
VAL_ 1921 DTCIUnused4_781 1 "true" 0 "false" ;
VAL_ 1921 DTCIUnused3_781 1 "true" 0 "false" ;
VAL_ 1921 DTCIUnused2_781 1 "true" 0 "false" ;
VAL_ 1921 DTCIUnused1_781 1 "true" 0 "false" ;
VAL_ 1921 DTCI_TstNPsdPwrUpSt_781 1 "true" 0 "false" ;
VAL_ 1921 DTCI_TstNPsdCdClrdSt_781 1 "true" 0 "false" ;
VAL_ 1921 DTCI_TstFldPwrUpSt_781 1 "true" 0 "false" ;
VAL_ 1921 DTCI_TstFldCdClrdStat_781 1 "true" 0 "false" ;
VAL_ 1921 DTCI_HistStat_781 1 "true" 0 "false" ;
VAL_ 1921 DTCI_DTCTriggered_781 1 "true" 0 "false" ;
VAL_ 1921 DTCI_DTCFaultType_781 3 "Type C" 2 "Type B" 1 "Type A" 0 "Not Supported" ;
VAL_ 1921 DTCI_CodeSupported_781 1 "true" 0 "false" ;
VAL_ 1912 DTCI_DTCFaultType_778 3 "Type C" 2 "Type B" 1 "Type A" 0 "Not Supported" ;
VAL_ 1912 DTCI_CodeSupported_778 1 "true" 0 "false" ;
VAL_ 1912 DTCI_CurrentStatus_778 1 "true" 0 "false" ;
VAL_ 1912 DTCI_TstNPsdCdClrdSt_778 1 "true" 0 "false" ;
VAL_ 1912 DTCI_TstFldCdClrdStat_778 1 "true" 0 "false" ;
VAL_ 1912 DTCI_HistStat_778 1 "true" 0 "false" ;
VAL_ 1912 DTCI_TstNPsdPwrUpSt_778 1 "true" 0 "false" ;
VAL_ 1912 DTCI_TstFldPwrUpSt_778 1 "true" 0 "false" ;
VAL_ 1912 DTCI_WrnIndRqdSt_778 1 "true" 0 "false" ;
VAL_ 1912 DTCI_DTCTriggered_778 1 "true" 0 "false" ;
VAL_ 1912 DTCIUnused7_778 1 "true" 0 "false" ;
VAL_ 1912 DTCIUnused6_778 1 "true" 0 "false" ;
VAL_ 1912 DTCIUnused5_778 1 "true" 0 "false" ;
VAL_ 1912 DTCIUnused4_778 1 "true" 0 "false" ;
VAL_ 1912 DTCIUnused3_778 1 "true" 0 "false" ;
VAL_ 1912 DTCIUnused2_778 1 "true" 0 "false" ;
VAL_ 1912 DTCIUnused1_778 1 "true" 0 "false" ;
VAL_ 1034 CRL_Cnfdnc 7 "Reserved4" 6 "Reserved3" 5 "Reserved2" 4 "Reserved1" 3 "Best" 2 "Marking Present" 1 "Weak Marking" 0 "No Lane" ;
VAL_ 1033 CLL_Cnfdnc 7 "Reserved4" 6 "Reserved3" 5 "Reserved2" 4 "Reserved1" 3 "Best" 2 "Marking Present" 1 "Weak Marking" 0 "No Lane" ;
VAL_ 800 FCACBSC_AutBrkRpRt 0 "None" 1 "Light" 2 "Full" 3 "Reserved" ;
VAL_ 800 FCACBSC_AutBrkRqTp 0 "None" 1 "Prefill" 2 "Haptic Pulse" 3 "Brake Per Requested Decel" 4 "Apply Park Brake" 5 "Hold" 6 "Lower Panic Brake Threshold" 7 "Reserved" 8 "Object Detected/Confirmation" ;
VAL_ 800 FCACBSC_AutBrkRqd 1 "true" 0 "false" ;
VAL_ 554 PrtdEPBSwStat 3 "Active" 2 "Apply" 1 "state0800" 0 "Not Active" ;
VAL_ 554 ElecPrkBrkAvailStat 7 "Unused and Reserved 3" 6 "Unused and Reserved 2" 5 "Unused and Reserved 1" 4 "Unavailable, Failed other" 3 "Unavailable, Failed state0800d" 2 "Unavailable, Failed Applied" 1 "Available, Not Failed" 0 "Unavailable, Not Failed" ;
VAL_ 554 ElecPrkBrkApplStat 3 "Park Brake Application in Progress" 2 "Park brake state0800d" 1 "Park Brake Applied" 0 "Unknown" ;
VAL_ 464 FrtAxlOpeMod 0 "Open" 1 "Active" 2 "Locked" 3 "Unknown" ;
VAL_ 465 RrAxlOpeMod 3 "Unknown" 2 "Locked" 1 "Active" 0 "Open" ;
VAL_ 465 RrAxlEstTrqV 1 "Invalid" 0 "Valid" ;
VAL_ 465 RrAxlStat 3 "Permanently Failed" 2 "Temporary Limited" 1 "Temporary Inhibit" 0 "Normal" ;
VAL_ 465 RrAxlCtrlMod 1 "External" 0 "Internal" ;
VAL_ 465 RAMDVLAtv 1 "true" 0 "false" ;
VAL_ 801 WhlBdySnsHmPosLrnd 1 "true" 0 "false" ;
VAL_ 801 WBRP_RtFrtV 1 "Invalid" 0 "Valid" ;
VAL_ 801 WBRP_RtRrV 1 "Invalid" 0 "Valid" ;
VAL_ 801 WBRP_LftRrV 1 "Invalid" 0 "Valid" ;
VAL_ 801 WBRP_LftFrtV 1 "Invalid" 0 "Valid" ;
VAL_ 844 IMUProtYawRtM 0 "Don't Use Data" 1 "Use Data" ;
VAL_ 844 IMUProtLonAccM 0 "Don't Use Data" 1 "Use Data" ;
VAL_ 844 IMUProtLatAccM 0 "Don't Use Data" 1 "Use Data" ;
VAL_ 528 BSABR_TrlBrkCntlIntRq 1 "true" 0 "false" ;
VAL_ 462 SecAxlLkTqRqCplRqTp 0 "No Action" 1 "Maximum Allowed Torque" 2 "Minimum Allowed Torque" 3 "Control To Requested Torque" ;
VAL_ 462 SATRCplReqAtv 1 "true" 0 "false" ;
VAL_ 1920 DTCI_CurrentStatus_780 1 "true" 0 "false" ;
VAL_ 1920 DTCI_WrnIndRqdSt_780 1 "true" 0 "false" ;
VAL_ 1920 DTCIUnused7_780 1 "true" 0 "false" ;
VAL_ 1920 DTCIUnused6_780 1 "true" 0 "false" ;
VAL_ 1920 DTCIUnused5_780 1 "true" 0 "false" ;
VAL_ 1920 DTCIUnused4_780 1 "true" 0 "false" ;
VAL_ 1920 DTCIUnused3_780 1 "true" 0 "false" ;
VAL_ 1920 DTCIUnused2_780 1 "true" 0 "false" ;
VAL_ 1920 DTCIUnused1_780 1 "true" 0 "false" ;
VAL_ 1920 DTCI_TstNPsdPwrUpSt_780 1 "true" 0 "false" ;
VAL_ 1920 DTCI_TstNPsdCdClrdSt_780 1 "true" 0 "false" ;
VAL_ 1920 DTCI_TstFldPwrUpSt_780 1 "true" 0 "false" ;
VAL_ 1920 DTCI_TstFldCdClrdStat_780 1 "true" 0 "false" ;
VAL_ 1920 DTCI_HistStat_780 1 "true" 0 "false" ;
VAL_ 1920 DTCI_DTCTriggered_780 1 "true" 0 "false" ;
VAL_ 1920 DTCI_DTCFaultType_780 3 "Type C" 2 "Type B" 1 "Type A" 0 "Not Supported" ;
VAL_ 1920 DTCI_CodeSupported_780 1 "true" 0 "false" ;
VAL_ 1907 DTCI_DTCFaultType_773 3 "Type C" 2 "Type B" 1 "Type A" 0 "Not Supported" ;
VAL_ 1907 DTCI_CodeSupported_773 1 "true" 0 "false" ;
VAL_ 1907 DTCI_CurrentStatus_773 1 "true" 0 "false" ;
VAL_ 1907 DTCI_TstNPsdCdClrdSt_773 1 "true" 0 "false" ;
VAL_ 1907 DTCI_TstFldCdClrdStat_773 1 "true" 0 "false" ;
VAL_ 1907 DTCI_HistStat_773 1 "true" 0 "false" ;
VAL_ 1907 DTCI_TstNPsdPwrUpSt_773 1 "true" 0 "false" ;
VAL_ 1907 DTCI_TstFldPwrUpSt_773 1 "true" 0 "false" ;
VAL_ 1907 DTCI_WrnIndRqdSt_773 1 "true" 0 "false" ;
VAL_ 1907 DTCI_DTCTriggered_773 1 "true" 0 "false" ;
VAL_ 1907 DTCIUnused7_773 1 "true" 0 "false" ;
VAL_ 1907 DTCIUnused6_773 1 "true" 0 "false" ;
VAL_ 1907 DTCIUnused5_773 1 "true" 0 "false" ;
VAL_ 1907 DTCIUnused4_773 1 "true" 0 "false" ;
VAL_ 1907 DTCIUnused3_773 1 "true" 0 "false" ;
VAL_ 1907 DTCIUnused2_773 1 "true" 0 "false" ;
VAL_ 1907 DTCIUnused1_773 1 "true" 0 "false" ;
VAL_ 1915 DTCI_DTCFaultType_77B 3 "Type C" 2 "Type B" 1 "Type A" 0 "Not Supported" ;
VAL_ 1915 DTCI_CodeSupported_77B 1 "true" 0 "false" ;
VAL_ 1915 DTCI_CurrentStatus_77B 1 "true" 0 "false" ;
VAL_ 1915 DTCI_TstNPsdCdClrdSt_77B 1 "true" 0 "false" ;
VAL_ 1915 DTCI_TstFldCdClrdStat_77B 1 "true" 0 "false" ;
VAL_ 1915 DTCI_HistStat_77B 1 "true" 0 "false" ;
VAL_ 1915 DTCI_TstNPsdPwrUpSt_77B 1 "true" 0 "false" ;
VAL_ 1915 DTCI_TstFldPwrUpSt_77B 1 "true" 0 "false" ;
VAL_ 1915 DTCI_WrnIndRqdSt_77B 1 "true" 0 "false" ;
VAL_ 1915 DTCI_DTCTriggered_77B 1 "true" 0 "false" ;
VAL_ 1915 DTCIUnused7_77B 1 "true" 0 "false" ;
VAL_ 1915 DTCIUnused6_77B 1 "true" 0 "false" ;
VAL_ 1915 DTCIUnused5_77B 1 "true" 0 "false" ;
VAL_ 1915 DTCIUnused4_77B 1 "true" 0 "false" ;
VAL_ 1915 DTCIUnused3_77B 1 "true" 0 "false" ;
VAL_ 1915 DTCIUnused2_77B 1 "true" 0 "false" ;
VAL_ 1915 DTCIUnused1_77B 1 "true" 0 "false" ;
VAL_ 353 ElecShfRngDisp 15 "Unused and Reserved 4" 14 "Unused and Reserved 3" 13 "Unused and Reserved 2" 12 "Park Requested And Denied" 11 "Drive Requested And In Progress" 10 "Neutral Requested And In Progress" 9 "Reverse Requested And In Progress" 8 "Park Requested And In Progress" 7 "Unused and Reserved 1" 6 "Manual Nominal" 5 "Low Nominal" 4 "Drive Nominal" 3 "Neutral Nominal" 2 "Reverse Nominal" 1 "Park Nominal" 0 "No Display " ;
VAL_ 353 ESPTransMalfIO 1 "true" 0 "false" ;
VAL_ 353 ESPRngInvldReqIO 1 "true" 0 "false" ;
VAL_ 353 ESPPrkInvldReqIO 1 "true" 0 "false" ;
VAL_ 353 ESPHldShfLvrToEngRgIO 1 "true" 0 "false" ;
VAL_ 353 ESPDrvrPrkIlkSftAtdIO 1 "true" 0 "false" ;
VAL_ 353 ESPDrvrIlkShfAtdIO 1 "true" 0 "false" ;
VAL_ 308 PFAS_SrvPedAlrtIO 1 "true" 0 "false" ;
VAL_ 308 PFAS_PFASysStat 0 "Disable" 1 "Active" 2 "Fault" 3 "Unused and Reserved" ;
VAL_ 308 PFAS_PFASndGenEn 1 "true" 0 "false" ;
VAL_ 308 PFAS_PFARevSnd 0 "No Action" 1 "Sound #1" 2 "Sound #2" 3 "Sound #3" ;
VAL_ 308 PFAS_PFAFwdSnd 0 "No Action" 1 "Sound #1" 2 "Sound #2" 3 "Sound #3" ;
VAL_ 308 PedFrndlyAlrtCsSetAvl 1 "true" 0 "false" ;
VAL_ 308 PedFrndlyAlrtCsCrStVal 0 "No Value" 1 "Off" 2 "On" ;
VAL_ 563 SPMCA_SusPrfMd6Avl 1 "true" 0 "false" ;
VAL_ 563 SPMCA_SusPrfMd5Avl 1 "true" 0 "false" ;
VAL_ 563 SPMCA_SusPrfMd4Avl 1 "true" 0 "false" ;
VAL_ 563 SPMCA_SusPrfMd3Avl 1 "true" 0 "false" ;
VAL_ 563 SPMCA_SusPrfMd2Avl 1 "true" 0 "false" ;
VAL_ 563 SPMCA_SusPrfMd1Avl 1 "true" 0 "false" ;
VAL_ 563 SPMCA_StrPrfMd6Avl 1 "true" 0 "false" ;
VAL_ 563 SPMCA_StrPrfMd5Avl 1 "true" 0 "false" ;
VAL_ 563 SPMCA_StrPrfMd4Avl 1 "true" 0 "false" ;
VAL_ 563 SPMCA_StrPrfMd3Avl 1 "true" 0 "false" ;
VAL_ 563 SPMCA_StrPrfMd2Avl 1 "true" 0 "false" ;
VAL_ 563 SPMCA_StrPrfMd1Avl 1 "true" 0 "false" ;
VAL_ 563 SPMCA_SndPrfMd6Avl 1 "true" 0 "false" ;
VAL_ 563 SPMCA_SndPrfMd5Avl 1 "true" 0 "false" ;
VAL_ 563 SPMCA_SndPrfMd4Avl 1 "true" 0 "false" ;
VAL_ 563 SPMCA_SndPrfMd3Avl 1 "true" 0 "false" ;
VAL_ 563 SPMCA_SndPrfMd2Avl 1 "true" 0 "false" ;
VAL_ 563 SPMCA_SndPrfMd1Avl 1 "true" 0 "false" ;
VAL_ 563 DPMCA_DispPrfMd6Avl 1 "true" 0 "false" ;
VAL_ 563 DPMCA_DispPrfMd5Avl 1 "true" 0 "false" ;
VAL_ 563 DPMCA_DispPrfMd4Avl 1 "true" 0 "false" ;
VAL_ 563 DPMCA_DispPrfMd3Avl 1 "true" 0 "false" ;
VAL_ 563 DPMCA_DispPrfMd2Avl 1 "true" 0 "false" ;
VAL_ 563 DPMCA_DispPrfMd1Avl 1 "true" 0 "false" ;
VAL_ 563 DPMCA_DrvlPrfMd6Avl 1 "true" 0 "false" ;
VAL_ 563 DPMCA_DrvlPrfMd5Avl 1 "true" 0 "false" ;
VAL_ 563 DPMCA_DrvlPrfMd4Avl 1 "true" 0 "false" ;
VAL_ 563 DPMCA_DrvlPrfMd3Avl 1 "true" 0 "false" ;
VAL_ 563 DPMCA_DrvlPrfMd2Avl 1 "true" 0 "false" ;
VAL_ 563 DPMCA_DrvlPrfMd1Avl 1 "true" 0 "false" ;
VAL_ 384 LKATODC_TrqRqAct 1 "true" 0 "false" ;
VAL_ 866 ColPrSysHzrdLghtsReq 0 "No Action" 1 "Activate" 2 "Deactivate" 3 "Reserved" ;
VAL_ 866 ColPrSysWndwsReq 0 "No Action" 1 "Close" 2 "Open" 3 "Reserved" ;
VAL_ 866 ColPrSysDrsReq 0 "No Action" 1 "Lock All" 2 "Unlock All" 3 "Reserved" ;
VAL_ 866 ColPrSysSnrfReq 0 "No Action" 1 "Close" 2 "Open" 3 "Reserved" ;
VAL_ 866 CPSInfotmntMtReq 0 "No Mute" 1 "Unused and Reserved 1" 2 "Unused and Reserved 2" 3 "Mute" ;
VAL_ 866 StBltTgtSetAvl 1 "true" 0 "false" ;
VAL_ 866 StBltTgtCrtSetVal 0 "No Action" 1 "Low" 2 "Normal" 3 "Performance" 4 "Locked" ;
VAL_ 866 MotStBltUnblIO 1 "true" 0 "false" ;
VAL_ 866 MotStBltFldIO 1 "true" 0 "false" ;
VAL_ 567 ExtHlStrAssCsCrStVal 2 "Standard Hold" 1 "Extended Hold" 0 "No Action" ;
VAL_ 567 ExtHlStrAssCsStAvl 1 "true" 0 "false" ;
VAL_ 567 DrvStyPerfMdCsCrStVal 7 "Performance Mode 7" 6 "Performance Mode 6" 5 "Performance Mode 5" 4 "Performance Mode 4" 3 "Performance Mode 3" 2 "Performance Mode 2" 1 "Performance Mode 1" 0 "No Action" ;
VAL_ 567 DrvStyPerfMdCsStAvl 1 "true" 0 "false" ;
VAL_ 567 PsngStPerfMdCsCrStVal 7 "Auto" 6 "Performance Mode 6" 5 "Performance Mode 5" 4 "Performance Mode 4" 3 "Performance Mode 3" 2 "Performance Mode 2" 1 "Performance Mode 1" 0 "No Action" ;
VAL_ 567 PsngStPerfMdCsStAvl 1 "true" 0 "false" ;
VAL_ 567 DrvrStPerfMdCsCrStVal 7 "Auto" 6 "Performance Mode 6" 5 "Performance Mode 5" 4 "Performance Mode 4" 3 "Performance Mode 3" 2 "Performance Mode 2" 1 "Performance Mode 1" 0 "No Action" ;
VAL_ 567 DrvrStPerfMdCsStAvl 1 "true" 0 "false" ;
VAL_ 567 ACCPerfMdCsCrStVal 7 "Auto" 6 "Performance Mode 6" 5 "Performance Mode 5" 4 "Performance Mode 4" 3 "Performance Mode 3" 2 "Performance Mode 2" 1 "Performance Mode 1" 0 "No Action" ;
VAL_ 567 ACCPerfMdCsStAvl 1 "true" 0 "false" ;
VAL_ 372 ARSOpStat 0 "Normal" 1 "Temporarily Unavailable" 2 "Reduced Performance" 3 "Failed" ;
VAL_ 372 ARSAlgmtCmplt 1 "true" 0 "false" ;
VAL_ 372 ARSActAnglV 1 "Invalid" 0 "Valid" ;
VAL_ 372 ARSFlrIO 1 "true" 0 "false" ;
SIG_GROUP_ 1931 DTCInfo_78B 1 : DTCI_CodeSupported_78B DTCI_CurrentStatus_78B DTCI_DTCFailType_78B DTCI_DTCFaultType_78B DTCI_DTCNumber_78B DTCI_DTCSource_78B DTCI_DTCTriggered_78B DTCI_HistStat_78B DTCI_TstFldCdClrdStat_78B DTCI_TstFldPwrUpSt_78B DTCI_TstNPsdCdClrdSt_78B DTCI_TstNPsdPwrUpSt_78B DTCIUnused1_78B DTCIUnused2_78B DTCIUnused3_78B DTCIUnused4_78B DTCIUnused5_78B DTCIUnused6_78B DTCIUnused7_78B DTCI_WrnIndRqdSt_78B;
SIG_GROUP_ 1928 DTCInfo_788 1 : DTCI_CodeSupported_788 DTCI_CurrentStatus_788 DTCI_DTCFailType_788 DTCI_DTCFaultType_788 DTCI_DTCNumber_788 DTCI_DTCSource_788 DTCI_DTCTriggered_788 DTCI_HistStat_788 DTCI_TstFldCdClrdStat_788 DTCI_TstFldPwrUpSt_788 DTCI_TstNPsdCdClrdSt_788 DTCI_TstNPsdPwrUpSt_788 DTCIUnused1_788 DTCIUnused2_788 DTCIUnused3_788 DTCIUnused4_788 DTCIUnused5_788 DTCIUnused6_788 DTCIUnused7_788 DTCI_WrnIndRqdSt_788;
SIG_GROUP_ 1925 DTCInfo_785 1 : DTCI_CodeSupported_785 DTCI_CurrentStatus_785 DTCI_DTCFailType_785 DTCI_DTCFaultType_785 DTCI_DTCNumber_785 DTCI_DTCSource_785 DTCI_DTCTriggered_785 DTCI_HistStat_785 DTCI_TstFldCdClrdStat_785 DTCI_TstFldPwrUpSt_785 DTCI_TstNPsdCdClrdSt_785 DTCI_TstNPsdPwrUpSt_785 DTCIUnused1_785 DTCIUnused2_785 DTCIUnused3_785 DTCIUnused4_785 DTCIUnused5_785 DTCIUnused6_785 DTCIUnused7_785 DTCI_WrnIndRqdSt_785;
SIG_GROUP_ 1922 DTCInfo_782 1 : DTCI_WrnIndRqdSt_782 DTCIUnused7_782 DTCIUnused6_782 DTCIUnused5_782 DTCIUnused4_782 DTCIUnused3_782 DTCIUnused2_782 DTCIUnused1_782 DTCI_TstNPsdPwrUpSt_782 DTCI_TstNPsdCdClrdSt_782 DTCI_TstFldPwrUpSt_782 DTCI_TstFldCdClrdStat_782 DTCI_HistStat_782 DTCI_DTCTriggered_782 DTCI_DTCSource_782 DTCI_DTCNumber_782 DTCI_DTCFaultType_782 DTCI_DTCFailType_782 DTCI_CurrentStatus_782 DTCI_CodeSupported_782;
SIG_GROUP_ 1904 DTCInfo_770 1 : DTCI_WrnIndRqdSt_770 DTCIUnused7_770 DTCIUnused6_770 DTCIUnused5_770 DTCIUnused4_770 DTCIUnused3_770 DTCIUnused2_770 DTCIUnused1_770 DTCI_TstNPsdPwrUpSt_770 DTCI_TstNPsdCdClrdSt_770 DTCI_TstFldPwrUpSt_770 DTCI_TstFldCdClrdStat_770 DTCI_HistStat_770 DTCI_DTCTriggered_770 DTCI_DTCSource_770 DTCI_DTCNumber_770 DTCI_DTCFaultType_770 DTCI_DTCFailType_770 DTCI_CurrentStatus_770 DTCI_CodeSupported_770;
SIG_GROUP_ 1921 DTCInfo_781 1 : DTCI_CurrentStatus_781 DTCI_WrnIndRqdSt_781 DTCIUnused7_781 DTCIUnused6_781 DTCIUnused5_781 DTCIUnused4_781 DTCIUnused3_781 DTCIUnused2_781 DTCIUnused1_781 DTCI_TstNPsdPwrUpSt_781 DTCI_TstNPsdCdClrdSt_781 DTCI_TstFldPwrUpSt_781 DTCI_TstFldCdClrdStat_781 DTCI_HistStat_781 DTCI_DTCTriggered_781 DTCI_DTCSource_781 DTCI_DTCNumber_781 DTCI_DTCFaultType_781 DTCI_DTCFailType_781 DTCI_CodeSupported_781;
SIG_GROUP_ 1912 DTCInfo_778 1 : DTCI_DTCFaultType_778 DTCI_CodeSupported_778 DTCI_CurrentStatus_778 DTCI_TstNPsdCdClrdSt_778 DTCI_TstFldCdClrdStat_778 DTCI_HistStat_778 DTCI_TstNPsdPwrUpSt_778 DTCI_TstFldPwrUpSt_778 DTCI_WrnIndRqdSt_778 DTCI_DTCFailType_778 DTCI_DTCNumber_778 DTCI_DTCSource_778 DTCI_DTCTriggered_778 DTCIUnused7_778 DTCIUnused6_778 DTCIUnused5_778 DTCIUnused4_778 DTCIUnused3_778 DTCIUnused2_778 DTCIUnused1_778;
SIG_GROUP_ 1034 CurvRghtLine 1 : CRL_Cnfdnc CRL_ViewRng CRL_CoefdA CRL_CoefA;
SIG_GROUP_ 1033 CurvLftLine 1 : CLL_Cnfdnc CLL_ViewRng CLL_CoefdA CLL_CoefA;
SIG_GROUP_ 800 FCACtrlBrkSysCmd 1 : FCACBSC_CtrlAcc FCACBSC_AutBrkRpRt FCACBSC_AutBrkRqTp FCACBSC_AutBrkRqd;
SIG_GROUP_ 465 RrAxlMaxDifVelLm 1 : RAMDVLReqVal RAMDVLAtv;
SIG_GROUP_ 801 WhlBdyRelPos 1 : WBRP_ARC WBRP_Tmestmp WBRP_RtFrtV WBRP_RtFrt WBRP_RtRrV WBRP_RtRr WBRP_LftRrV WBRP_LftRr WBRP_LftFrtV WBRP_LftFrt;
SIG_GROUP_ 528 BrkSysAutBrkReq 1 : BSABR_TrlBrkRq BSABR_TrlBrkCntlIntRq;
SIG_GROUP_ 462 SecAxlTrqReq 1 : SATRCplReqVal SATRCplReqAtv;
SIG_GROUP_ 510 BrkPresSnsrUnprocData 1 : BPSUD_MsCyPrSnsSUpVal BPSUD_MsCyPrSns2UpVal BPSUD_MsCyPrSns1UpVal;
SIG_GROUP_ 1920 DTCInfo_780 1 : DTCI_CurrentStatus_780 DTCI_WrnIndRqdSt_780 DTCIUnused7_780 DTCIUnused6_780 DTCIUnused5_780 DTCIUnused4_780 DTCIUnused3_780 DTCIUnused2_780 DTCIUnused1_780 DTCI_TstNPsdPwrUpSt_780 DTCI_TstNPsdCdClrdSt_780 DTCI_TstFldPwrUpSt_780 DTCI_TstFldCdClrdStat_780 DTCI_HistStat_780 DTCI_DTCTriggered_780 DTCI_DTCSource_780 DTCI_DTCNumber_780 DTCI_DTCFaultType_780 DTCI_DTCFailType_780 DTCI_CodeSupported_780;
SIG_GROUP_ 1907 DTCInfo_773 1 : DTCIUnused4_773 DTCIUnused3_773 DTCIUnused2_773 DTCIUnused1_773 DTCI_DTCFaultType_773 DTCI_CodeSupported_773 DTCI_CurrentStatus_773 DTCI_TstNPsdCdClrdSt_773 DTCI_TstFldCdClrdStat_773 DTCI_HistStat_773 DTCI_TstNPsdPwrUpSt_773 DTCI_TstFldPwrUpSt_773 DTCI_WrnIndRqdSt_773 DTCI_DTCFailType_773 DTCI_DTCNumber_773 DTCI_DTCSource_773 DTCI_DTCTriggered_773 DTCIUnused7_773 DTCIUnused6_773 DTCIUnused5_773;
SIG_GROUP_ 1915 DTCInfo_77B 1 : DTCI_DTCFaultType_77B DTCI_CodeSupported_77B DTCI_CurrentStatus_77B DTCI_TstNPsdCdClrdSt_77B DTCI_TstFldCdClrdStat_77B DTCI_HistStat_77B DTCI_TstNPsdPwrUpSt_77B DTCI_TstFldPwrUpSt_77B DTCI_WrnIndRqdSt_77B DTCI_DTCFailType_77B DTCI_DTCNumber_77B DTCI_DTCSource_77B DTCI_DTCTriggered_77B DTCIUnused7_77B DTCIUnused6_77B DTCIUnused5_77B DTCIUnused4_77B DTCIUnused3_77B DTCIUnused2_77B DTCIUnused1_77B;
SIG_GROUP_ 308 PedFrndlyAlrtStat 1 : PFAS_SrvPedAlrtIO PFAS_PFASysStat PFAS_PFASndVolCtrl PFAS_PFASndGenEn PFAS_PFARevSnd PFAS_PFAFwdSnd PFAS_PFACrsOvrSpd;
SIG_GROUP_ 563 SusPerfMdCustAvl 1 : SPMCA_SusPrfMd6Avl SPMCA_SusPrfMd5Avl SPMCA_SusPrfMd4Avl SPMCA_SusPrfMd3Avl SPMCA_SusPrfMd2Avl SPMCA_SusPrfMd1Avl;
SIG_GROUP_ 563 StrPerfMdCustAvl 1 : SPMCA_StrPrfMd6Avl SPMCA_StrPrfMd5Avl SPMCA_StrPrfMd4Avl SPMCA_StrPrfMd3Avl SPMCA_StrPrfMd2Avl SPMCA_StrPrfMd1Avl;
SIG_GROUP_ 563 SndPerfMdCustAvl 1 : SPMCA_SndPrfMd6Avl SPMCA_SndPrfMd5Avl SPMCA_SndPrfMd4Avl SPMCA_SndPrfMd3Avl SPMCA_SndPrfMd2Avl SPMCA_SndPrfMd1Avl;
SIG_GROUP_ 563 DispPerfCustMdAvl 1 : DPMCA_DispPrfMd6Avl DPMCA_DispPrfMd5Avl DPMCA_DispPrfMd4Avl DPMCA_DispPrfMd3Avl DPMCA_DispPrfMd2Avl DPMCA_DispPrfMd1Avl;
SIG_GROUP_ 563 DrvlnPerfMdCustAvl 1 : DPMCA_DrvlPrfMd6Avl DPMCA_DrvlPrfMd5Avl DPMCA_DrvlPrfMd4Avl DPMCA_DrvlPrfMd3Avl DPMCA_DrvlPrfMd2Avl DPMCA_DrvlPrfMd1Avl;
SIG_GROUP_ 384 LKATqOvrDltCmd 1 : LKATODC_TrqVl LKATODC_TrqRqAct;
